[part 4 of 10: package /E40_Platform_System_SystemPackage/Components]
AUTOSAR XML (schema 4-2-1)
package /E40_Platform_System_SystemPackage/Components  (continued)
  21 x constant specification:
    CWarnMsg_Core_ObserverHudWarningDisplayDataValue0: value-spec={short-label=CWarnMsg_Core_ObserverHudWarningDisplayDataValue0, fields=[CWarnMsg_Core_ObserverHudWarningDisplayDataValue_0:0, CWarnMsg_Core_ObserverHudWarningDisplayDataValue_1:0, CWarnMsg_Core_ObserverHudWarningDisplayDataValue_2:[CWarnMsg_Core_ObserverdynData0Value:0, CWarnMsg_Core_ObserverdynData1Value:0, CWarnMsg_Core_ObserverdynData2Value:0, CWarnMsg_Core_ObserverdynData3Value:0, CWarnMsg_Core_ObserverdynData4Value:0, CWarnMsg_Core_ObserverdynData5Value:0, CWarnMsg_Core_ObserverdynData6Value:0, CWarnMsg_Core_ObserverdynData7Value:0]]}
    CWarnMsg_Core_ObserverTpmsWarningDataDataValue0: value-spec={short-label=CWarnMsg_Core_ObserverTpmsWarningDataDataValue0, fields=CWarnMsg_Core_ObserverTpmsWarningDataDataValue_0:[CWarnMsg_Core_ObservertpmsWarndata0Value:0, CWarnMsg_Core_ObservertpmsWarndata1Value:0, CWarnMsg_Core_ObservertpmsWarndata2Value:0, CWarnMsg_Core_ObservertpmsWarndata3Value:0, CWarnMsg_Core_ObservertpmsWarndata4Value:0]}
    CWarnMsg_Core_ObserverWarningHighInterrupt_StateValue0: value-spec=CWarnMsg_Core_ObserverWarningHighInterrupt_StateValue0:0
    CWarnMsg_Core_ObserverWarningInterrupt_StateValue0: value-spec=CWarnMsg_Core_ObserverWarningInterrupt_StateValue0:0
    CWarnMsg_Core_ObserverWarningDisplayDataValue0: value-spec={short-label=CWarnMsg_Core_ObserverWarningDisplayDataValue0, fields=[CWarnMsg_Core_ObserverWarningDisplayDataValue_0:0, CWarnMsg_Core_ObserverWarningDisplayDataValue_1:0, CWarnMsg_Core_ObserverWarningDisplayDataValue_2:[CWarnMsg_Core_ObserverdynData0Value:0, CWarnMsg_Core_ObserverdynData1Value:0, CWarnMsg_Core_ObserverdynData2Value:0, CWarnMsg_Core_ObserverdynData3Value:0, CWarnMsg_Core_ObserverdynData4Value:0, CWarnMsg_Core_ObserverdynData5Value:0, CWarnMsg_Core_ObserverdynData6Value:0, CWarnMsg_Core_ObserverdynData7Value:0]]}
    CWarnMsg_Core_ObserverChime_RequestValue0: value-spec=CWarnMsg_Core_ObserverChime_RequestValue0:0
    CWarnMsg_Core_ObserverChime_StatusValue0: value-spec=CWarnMsg_Core_ObserverChime_StatusValue0:0
    CWarnMsg_Core_ObserverIgnitionSubstateValue0: value-spec=CWarnMsg_Core_ObserverIgnitionSubstateValue0:0
    CWarnMsg_Core_ObserverWSSCurrentClusterModeValue0: value-spec=CWarnMsg_Core_ObserverWSSCurrentClusterModeValue0:0
    CWarnMsg_Core_ObserverFactoryModeValue0: value-spec=CWarnMsg_Core_ObserverFactoryModeValue0:0
    CWarnMsg_Core_ObserverFactoryModeStatusValue0: value-spec=CWarnMsg_Core_ObserverFactoryModeStatusValue0:0
    CWarnMsg_Core_ObserverHMI_ReadyStatusValue0: value-spec=CWarnMsg_Core_ObserverHMI_ReadyStatusValue0:0
    CWarnMsg_Core_ObserverHMIScreenMode_StatusValue0: value-spec=CWarnMsg_Core_ObserverHMIScreenMode_StatusValue0:0
    CWarnMsg_Core_ObserverWakeType_HwValue0: value-spec=CWarnMsg_Core_ObserverWakeType_HwValue0:0
    CWarnMsg_Core_ObserverWakeType_IntValue0: value-spec=CWarnMsg_Core_ObserverWakeType_IntValue0:0
    CWarnMsg_Core_ObserverHudWarningStatusDataValue0: value-spec={short-label=CWarnMsg_Core_ObserverHudWarningStatusDataValue0, fields=[CWarnMsg_Core_ObserverHudWarningStatusDataValue_0:0, CWarnMsg_Core_ObserverHudWarningStatusDataValue_1:0, CWarnMsg_Core_ObserverHudWarningStatusDataValue_2:[CWarnMsg_Core_ObserverdynData0Value:0, CWarnMsg_Core_ObserverdynData1Value:0, CWarnMsg_Core_ObserverdynData2Value:0, CWarnMsg_Core_ObserverdynData3Value:0, CWarnMsg_Core_ObserverdynData4Value:0, CWarnMsg_Core_ObserverdynData5Value:0, CWarnMsg_Core_ObserverdynData6Value:0, CWarnMsg_Core_ObserverdynData7Value:0, CWarnMsg_Core_ObserverdynData8Value:0, CWarnMsg_Core_ObserverdynData9Value:0]]}
    CWarnMsg_Core_ObserverStarterStatus_OutValue0: value-spec=CWarnMsg_Core_ObserverStarterStatus_OutValue0:0
    CWarnMsg_Core_ObserverNvmDataValue0: value-spec=CWarnMsg_Core_ObserverNvmDataValue0:0
    CWarnMsg_Core_ObserverTpms_PayloadValue0: value-spec=CWarnMsg_Core_ObserverTpms_PayloadValue0:[CWarnMsg_Core_ObserverTpms_Payload0Value:0, CWarnMsg_Core_ObserverTpms_Payload1Value:0, CWarnMsg_Core_ObserverTpms_Payload2Value:0, CWarnMsg_Core_ObserverTpms_Payload3Value:0, CWarnMsg_Core_ObserverTpms_Payload4Value:0]
    CWarnMsg_Core_ObserverTargetSwValue0: value-spec=CWarnMsg_Core_ObserverTargetSwValue0:0
    CWarnMsg_Core_ObserverWarningStatusDataValue0: value-spec={short-label=CWarnMsg_Core_ObserverWarningStatusDataValue0, fields=[CWarnMsg_Core_ObserverWarningStatusDataValue_0:0, CWarnMsg_Core_ObserverWarningStatusDataValue_1:0, CWarnMsg_Core_ObserverWarningStatusDataValue_2:[CWarnMsg_Core_ObserverdynData0Value:0, CWarnMsg_Core_ObserverdynData1Value:0, CWarnMsg_Core_ObserverdynData2Value:0, CWarnMsg_Core_ObserverdynData3Value:0, CWarnMsg_Core_ObserverdynData4Value:0, CWarnMsg_Core_ObserverdynData5Value:0, CWarnMsg_Core_ObserverdynData6Value:0, CWarnMsg_Core_ObserverdynData7Value:0, CWarnMsg_Core_ObserverdynData8Value:0, CWarnMsg_Core_ObserverdynData9Value:0]]}
  swc implementation IMPL_CWarnMsg_Core_Observer: programming-language=C, behavior=IB_CWarnMsg_Core_Observer
    code-descriptors:
      code CodeDescriptor
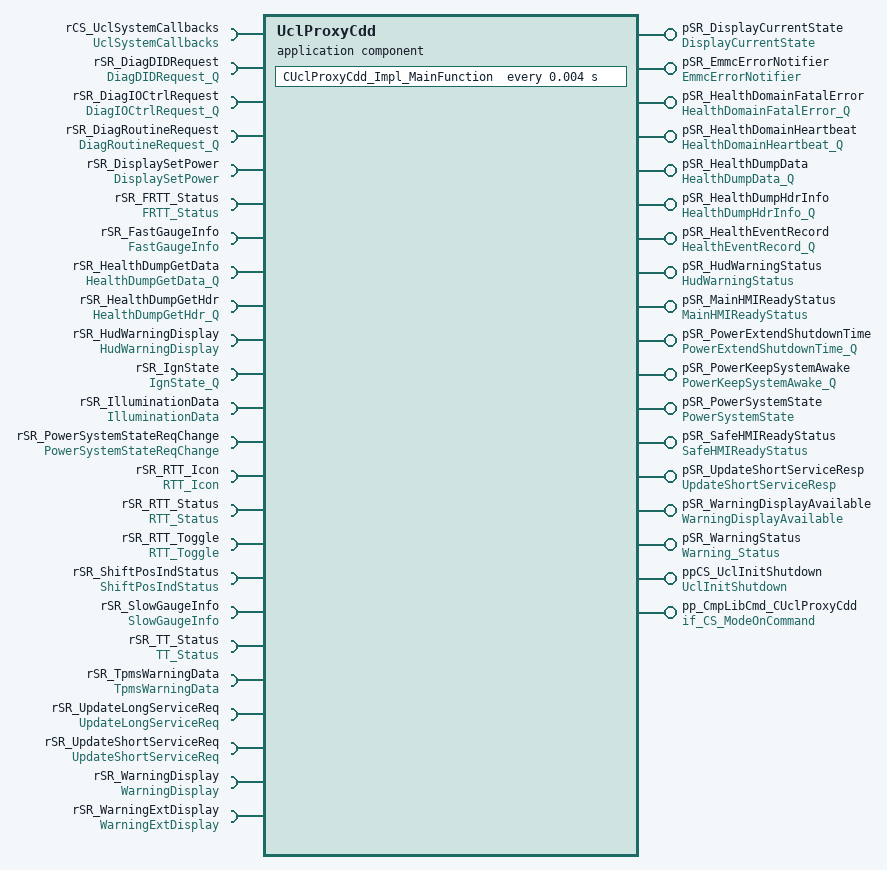
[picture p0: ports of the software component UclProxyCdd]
  application sw component type UclProxyCdd
    18 x provide port:
      pSR_DisplayCurrentState: nonqueued-sender-com-spec{data-element=DisplayCurrentStateData, init-value=constant-reference=UclProxyCddDisplayCurrentStateDataValue0}, provided-interface=DisplayCurrentState
      pSR_EmmcErrorNotifier: nonqueued-sender-com-spec{data-element=EmmcErrorNotifierData, init-value=constant-reference=UclProxyCddEmmcErrorNotifierDataValue0}, provided-interface=EmmcErrorNotifier
      pSR_HealthDomainFatalError: queued-sender-com-spec=HealthDomainFatalErrorData, provided-interface=HealthDomainFatalError_Q
      pSR_HealthDomainHeartbeat: queued-sender-com-spec=HealthDomainHeartbeatData, provided-interface=HealthDomainHeartbeat_Q
      pSR_HealthDumpData: queued-sender-com-spec=HealthDumpDataData, provided-interface=HealthDumpData_Q
      pSR_HealthDumpHdrInfo: queued-sender-com-spec=HealthDumpHdrInfoData, provided-interface=HealthDumpHdrInfo_Q
      pSR_HealthEventRecord: queued-sender-com-spec=HealthEventRecordData, provided-interface=HealthEventRecord_Q
      pSR_HudWarningStatus: nonqueued-sender-com-spec{data-element=HudWarningStatusData, init-value=constant-reference=UclProxyCddHudWarningStatusDataValue0}, provided-interface=HudWarningStatus
      pSR_MainHMIReadyStatus: queued-sender-com-spec=MainHMIReadyStatusData, provided-interface=MainHMIReadyStatus
      pSR_PowerExtendShutdownTime: queued-sender-com-spec=PowerExtendShutdownTimeData, provided-interface=PowerExtendShutdownTime_Q
      pSR_PowerKeepSystemAwake: queued-sender-com-spec=PowerKeepSystemAwakeData, provided-interface=PowerKeepSystemAwake_Q
      pSR_PowerSystemState: nonqueued-sender-com-spec{data-element=PowerSystemStateData, init-value=constant-reference=UclProxyCddPowerSystemStateDataValue0}, provided-interface=PowerSystemState
      pSR_SafeHMIReadyStatus: queued-sender-com-spec=SafeHMIReadyStatusData, provided-interface=SafeHMIReadyStatus
      pSR_UpdateShortServiceResp: nonqueued-sender-com-spec{data-element=UpdateShortServiceRespData, init-value=constant-reference=UclProxyCddUpdateShortServiceRespDataValue0}, provided-interface=UpdateShortServiceResp
      pSR_WarningDisplayAvailable: nonqueued-sender-com-spec{data-element=WarningDisplayAvailableData, init-value=constant-reference=UclProxyCddWarningDisplayAvailableDataValue0}, provided-interface=WarningDisplayAvailable
      pSR_WarningStatus: nonqueued-sender-com-spec{data-element=WarningStatusData, init-value=constant-reference=UclProxyCddWarningStatusDataValue0}, provided-interface=Warning_Status
      ppCS_UclInitShutdown: provided-com-specs=[{operation=Impl_Initialize, queue-length=1}, {operation=Impl_Shutdown, queue-length=1}], provided-interface=UclInitShutdown
      pp_CmpLibCmd_CUclProxyCdd: server-com-spec{operation=Impl_OnCommand, queue-length=1}, provided-interface=if_CS_ModeOnCommand
    24 x require port:
      rCS_UclSystemCallbacks: required-interface=UclSystemCallbacks
      rSR_DiagDIDRequest: queued-receiver-com-spec{data-element=DiagDIDRequestData, queue-length=2}, required-interface=DiagDIDRequest_Q
      rSR_DiagIOCtrlRequest: queued-receiver-com-spec{data-element=DiagIOCtrlRequestData, queue-length=2}, required-interface=DiagIOCtrlRequest_Q
      rSR_DiagRoutineRequest: queued-receiver-com-spec{data-element=DiagRoutineRequestData, queue-length=2}, required-interface=DiagRoutineRequest_Q
      rSR_DisplaySetPower: nonqueued-receiver-com-spec{data-element=DisplaySetPower/DisplaySetPowerData, init-value=constant-reference=UclProxyCddDisplaySetPowerDataValue0}, required-interface=DisplaySetPower
      rSR_FRTT_Status: nonqueued-receiver-com-spec{data-element=FRTT_StatusData, init-value=constant-reference=UclProxyCddFRTT_StatusDataValue0}, required-interface=FRTT_Status
      rSR_FastGaugeInfo: nonqueued-receiver-com-spec{data-element=FastGaugeInfoData, init-value=constant-reference=UclProxyCddFastGaugeInfoDataValue0}, required-interface=FastGaugeInfo
      rSR_HealthDumpGetData: queued-receiver-com-spec{data-element=HealthDumpGetDataData, queue-length=1}, required-interface=HealthDumpGetData_Q
      rSR_HealthDumpGetHdr: queued-receiver-com-spec{data-element=HealthDumpGetHdrData, queue-length=1}, required-interface=HealthDumpGetHdr_Q
      rSR_HudWarningDisplay: nonqueued-receiver-com-spec{data-element=HudWarningDisplayData, init-value=constant-reference=UclProxyCddHudWarningDisplayDataValue0}, required-interface=HudWarningDisplay
      rSR_IgnState: queued-receiver-com-spec{data-element=IgnStateData, queue-length=5}, required-interface=IgnState_Q
      rSR_IlluminationData: nonqueued-receiver-com-spec{data-element=IlluminationDataData, init-value=constant-reference=UclProxyCddIlluminationDataDataValue0}, required-interface=IlluminationData
      rSR_PowerSystemStateReqChange: nonqueued-receiver-com-spec{data-element=PowerSystemStateReqChangeData, init-value=constant-reference=UclProxyCddPowerSystemStateReqChangeDataValue0}, required-interface=PowerSystemStateReqChange
      rSR_RTT_Icon: nonqueued-receiver-com-spec{data-element=RTT_IconData, init-value=constant-reference=UclProxyCddRTT_IconDataValue0}, required-interface=RTT_Icon
      rSR_RTT_Status: nonqueued-receiver-com-spec{data-element=RTT_StatusData, init-value=constant-reference=UclProxyCddRTT_StatusDataValue0}, required-interface=RTT_Status
      rSR_RTT_Toggle: nonqueued-receiver-com-spec{data-element=RTT_ToggleData, init-value=constant-reference=UclProxyCddRTT_ToggleDataValue0}, required-interface=RTT_Toggle
      rSR_ShiftPosIndStatus: nonqueued-receiver-com-spec{data-element=ShiftPosIndStatusData, init-value=constant-reference=UclProxyCddShiftPosIndStatusDataValue0}, required-interface=ShiftPosIndStatus
      rSR_SlowGaugeInfo: nonqueued-receiver-com-spec{data-element=SlowGaugeInfoData, init-value=constant-reference=UclProxyCddSlowGaugeInfoDataValue0}, required-interface=SlowGaugeInfo
      rSR_TT_Status: nonqueued-receiver-com-spec{data-element=TT_StatusData, init-value=constant-reference=UclProxyCddTT_StatusDataValue0}, required-interface=TT_Status
      rSR_TpmsWarningData: nonqueued-receiver-com-spec{data-element=TpmsWarningDataData, init-value=constant-reference=UclProxyCddTpmsWarningDataDataValue0}, required-interface=TpmsWarningData
      rSR_UpdateLongServiceReq: nonqueued-receiver-com-spec{data-element=UpdateLongServiceReqData, init-value=constant-reference=UclProxyCddUpdateLongServiceReqDataValue0}, required-interface=UpdateLongServiceReq
      rSR_UpdateShortServiceReq: nonqueued-receiver-com-spec{data-element=UpdateShortServiceReqData, init-value=constant-reference=UclProxyCddUpdateShortServiceReqDataValue0}, required-interface=UpdateShortServiceReq
      rSR_WarningDisplay: nonqueued-receiver-com-spec{data-element=WarningDisplayData, init-value=constant-reference=UclProxyCddWarningDisplayDataValue0}, required-interface=WarningDisplay
      rSR_WarningExtDisplay: nonqueued-receiver-com-spec{data-element=WarningExtDisplayData, init-value=constant-reference=UclProxyCddWarningExtDisplayDataValue0}, required-interface=WarningExtDisplay
    behavior IB_UclProxyCdd
      operation invoked event OIE_ppCS_UclInitShutdown_CUclProxyCdd_Impl_InitializeTrigByImpl_Initialize: start-on-event=CUclProxyCdd_Impl_Initialize, operation=ppCS_UclInitShutdown.Impl_Initialize
      timing event TECUclProxyCdd_Impl_MainFunction: start-on-event=CUclProxyCdd_Impl_MainFunction, period=0.004
      operation invoked event OIE_pp_CmpLibCmd_CUclProxyCdd_CUclProxyCdd_Impl_OnCommandTrigByImpl_OnCommand: start-on-event=CUclProxyCdd_Impl_OnCommand, operation=pp_CmpLibCmd_CUclProxyCdd.Impl_OnCommand
      operation invoked event OIE_ppCS_UclInitShutdown_CUclProxyCdd_Impl_ShutdownTrigByImpl_Shutdown: start-on-event=CUclProxyCdd_Impl_Shutdown, operation=ppCS_UclInitShutdown.Impl_Shutdown
      17 x data received event:
        DREOnDre_DisplaySetPowerTrigByDisplaySetPowerData: start-on-event=OnDre_DisplaySetPower, data=rSR_DisplaySetPower.DisplaySetPowerData
        DREOnDre_FRTT_StatusTrigByFRTT_StatusData: start-on-event=OnDre_FRTT_Status, data=rSR_FRTT_Status.FRTT_StatusData
        DREOnDre_FastGaugeInfoTrigByFastGaugeInfoData: start-on-event=OnDre_FastGaugeInfo, data=rSR_FastGaugeInfo.FastGaugeInfoData
        DREOnDre_HealthDumpGetDataTrigByHealthDumpGetDataData: start-on-event=OnDre_HealthDumpGetData, data=rSR_HealthDumpGetData.HealthDumpGetDataData
        DREOnDre_HealthDumpGetHdrTrigByHealthDumpGetHdrData: start-on-event=OnDre_HealthDumpGetHdr, data=rSR_HealthDumpGetHdr.HealthDumpGetHdrData
        DREOnDre_IlluminationDataTrigByWarningExtDisplayData: start-on-event=OnDre_IlluminationData, data=rSR_WarningExtDisplay.WarningExtDisplayData
        DREOnDre_PowerSystemStateReqChangeTrigByPowerSystemStateReqChangeData: start-on-event=OnDre_PowerSystemStateReqChange, data=rSR_PowerSystemStateReqChange.PowerSystemStateReqChangeData
        DREOnDre_RTT_IconTrigByRTT_IconData: start-on-event=OnDre_RTT_Icon, data=rSR_RTT_Icon.RTT_IconData
        DREOnDre_RTT_StatusTrigByRTT_StatusData: start-on-event=OnDre_RTT_Status, data=rSR_RTT_Status.RTT_StatusData
        DREOnDre_RTT_ToggleTrigByRTT_ToggleData: start-on-event=OnDre_RTT_Toggle, data=rSR_RTT_Toggle.RTT_ToggleData
        DREOnDre_ShiftPosIndStatusTrigByShiftPosIndStatusData: start-on-event=OnDre_ShiftPosIndStatus, data=rSR_ShiftPosIndStatus.ShiftPosIndStatusData
        DREOnDre_SlowGaugeInfoTrigBySlowGaugeInfoData: start-on-event=OnDre_SlowGaugeInfo, data=rSR_SlowGaugeInfo.SlowGaugeInfoData
        DREOnDre_TT_StatusTrigByTT_StatusData: start-on-event=OnDre_TT_Status, data=rSR_TT_Status.TT_StatusData
        DREOnDre_UpdateLongServiceReqTrigByRTT_ToggleData: start-on-event=OnDre_UpdateLongServiceReq, data=rSR_RTT_Toggle.RTT_ToggleData
        DREOnDre_UpdateShortServiceReqTrigByRTT_ToggleData: start-on-event=OnDre_UpdateShortServiceReq, data=rSR_RTT_Toggle.RTT_ToggleData
        DREOnDre_WarningDisplayTrigByWarningDisplayData: start-on-event=OnDre_WarningDisplay, data=rSR_WarningDisplay.WarningDisplayData
        DREOnDre_WarningExtDisplayTrigByIlluminationDataData: start-on-event=OnDre_WarningExtDisplay, data=rSR_IlluminationData.IlluminationDataData
      port-api-options:
        enable-take-address=false, indirect-api=false, port=pSR_DisplayCurrentState
        enable-take-address=false, indirect-api=false, port=pSR_EmmcErrorNotifier
        enable-take-address=false, indirect-api=false, port=pSR_HealthDomainFatalError
        enable-take-address=false, indirect-api=false, port=pSR_HealthDomainHeartbeat
        enable-take-address=false, indirect-api=false, port=pSR_HealthDumpData
        enable-take-address=false, indirect-api=false, port=pSR_HealthDumpHdrInfo
        enable-take-address=false, indirect-api=false, port=pSR_HealthEventRecord
        enable-take-address=false, indirect-api=false, port=pSR_HudWarningStatus
        enable-take-address=false, indirect-api=false, port=pSR_MainHMIReadyStatus
        enable-take-address=false, indirect-api=false, port=pSR_PowerExtendShutdownTime
        enable-take-address=false, indirect-api=false, port=pSR_PowerKeepSystemAwake
        enable-take-address=false, indirect-api=false, port=pSR_PowerSystemState
        enable-take-address=false, indirect-api=false, port=pSR_SafeHMIReadyStatus
        enable-take-address=false, indirect-api=false, port=pSR_UpdateShortServiceResp
        enable-take-address=false, indirect-api=false, port=pSR_WarningDisplayAvailable
        enable-take-address=false, indirect-api=false, port=pSR_WarningStatus
        enable-take-address=false, indirect-api=false, port=ppCS_UclInitShutdown
        enable-take-address=false, indirect-api=false, port=pp_CmpLibCmd_CUclProxyCdd
        enable-take-address=false, indirect-api=false, port=rCS_UclSystemCallbacks
        enable-take-address=false, indirect-api=false, port=rSR_DiagDIDRequest
        enable-take-address=false, indirect-api=false, port=rSR_DiagIOCtrlRequest
        enable-take-address=false, indirect-api=false, port=rSR_DiagRoutineRequest
        enable-take-address=false, indirect-api=false, port=rSR_DisplaySetPower
        enable-take-address=false, indirect-api=false, port=rSR_FRTT_Status
        enable-take-address=false, indirect-api=false, port=rSR_FastGaugeInfo
        enable-take-address=false, indirect-api=false, port=rSR_HealthDumpGetData
        enable-take-address=false, indirect-api=false, port=rSR_HealthDumpGetHdr
        enable-take-address=false, indirect-api=false, port=rSR_HudWarningDisplay
        enable-take-address=false, indirect-api=false, port=rSR_IgnState
        enable-take-address=false, indirect-api=false, port=rSR_IlluminationData
        enable-take-address=false, indirect-api=false, port=rSR_PowerSystemStateReqChange
        enable-take-address=false, indirect-api=false, port=rSR_RTT_Icon
        enable-take-address=false, indirect-api=false, port=rSR_RTT_Status
        enable-take-address=false, indirect-api=false, port=rSR_RTT_Toggle
        enable-take-address=false, indirect-api=false, port=rSR_ShiftPosIndStatus
        enable-take-address=false, indirect-api=false, port=rSR_SlowGaugeInfo
        enable-take-address=false, indirect-api=false, port=rSR_TT_Status
        enable-take-address=false, indirect-api=false, port=rSR_TpmsWarningData
        enable-take-address=false, indirect-api=false, port=rSR_UpdateLongServiceReq
        enable-take-address=false, indirect-api=false, port=rSR_UpdateShortServiceReq
        enable-take-address=false, indirect-api=false, port=rSR_WarningDisplay
        enable-take-address=false, indirect-api=false, port=rSR_WarningExtDisplay
      21 x runnable, all with can-be-invoked-concurrently=true:
        CUclProxyCdd_Impl_Initialize
        CUclProxyCdd_Impl_MainFunction
          data-receive-point-by-arguments:
            23 x access:
              DRP_rSR_DiagDIDRequest_DiagDIDRequestData: accessed-variable=rSR_DiagDIDRequest.DiagDIDRequestData
              DRP_rSR_DiagIOCtrlRequest_DiagIOCtrlRequestData: accessed-variable=rSR_DiagIOCtrlRequest.DiagIOCtrlRequestData
              DRP_rSR_DiagRoutineRequest_DiagRoutineRequestData: accessed-variable=rSR_DiagRoutineRequest.DiagRoutineRequestData
              DRA_rSR_DisplaySetPower_DisplaySetPowerData: accessed-variable=rSR_DisplaySetPower.DisplaySetPowerData
              DRA_rSR_FRTT_Status_FRTT_StatusData: accessed-variable=rSR_FRTT_Status.FRTT_StatusData
              DRA_rSR_FastGaugeInfo_FastGaugeInfoData: accessed-variable=rSR_FastGaugeInfo.FastGaugeInfoData
              DRP_rSR_HealthDumpGetData_HealthDumpGetDataData: accessed-variable=rSR_HealthDumpGetData.HealthDumpGetDataData
              DRP_rSR_HealthDumpGetHdr_HealthDumpGetHdrData: accessed-variable=rSR_HealthDumpGetHdr.HealthDumpGetHdrData
              DRA_rSR_HudWarningDisplay_HudWarningDisplayData: accessed-variable=rSR_HudWarningDisplay.HudWarningDisplayData
              DRP_rSR_IgnState_IgnStateData: accessed-variable=rSR_IgnState.IgnStateData
              DRA_rSR_IlluminationData_IlluminationDataData: accessed-variable=rSR_IlluminationData.IlluminationDataData
              DRA_rSR_PowerSystemStateReqChange_PowerSystemStateReqChangeData: accessed-variable=rSR_PowerSystemStateReqChange.PowerSystemStateReqChangeData
              DRA_rSR_RTT_Icon_RTT_IconData: accessed-variable=rSR_RTT_Icon.RTT_IconData
              DRA_rSR_RTT_Status_RTT_StatusData: accessed-variable=rSR_RTT_Status.RTT_StatusData
              DRA_rSR_RTT_Toggle_RTT_ToggleData: accessed-variable=rSR_RTT_Toggle.RTT_ToggleData
              DRA_rSR_ShiftPosIndStatus_ShiftPosIndStatusData: accessed-variable=rSR_ShiftPosIndStatus.ShiftPosIndStatusData
              DRA_rSR_SlowGaugeInfo_SlowGaugeInfoData: accessed-variable=rSR_SlowGaugeInfo.SlowGaugeInfoData
              DRA_rSR_TT_Status_TT_StatusData: accessed-variable=rSR_TT_Status.TT_StatusData
              DRA_rSR_TpmsWarningData_TpmsWarningDataData: accessed-variable=rSR_TpmsWarningData.TpmsWarningDataData
              DRA_rSR_UpdateLongServiceReq_UpdateLongServiceReqData: accessed-variable=rSR_UpdateLongServiceReq.UpdateLongServiceReqData
              DRA_rSR_UpdateShortServiceReq_UpdateShortServiceReqData: accessed-variable=rSR_UpdateShortServiceReq.UpdateShortServiceReqData
              DRA_rSR_WarningDisplay_WarningDisplayData: accessed-variable=rSR_WarningDisplay.WarningDisplayData
              DRA_rSR_WarningExtDisplay_WarningExtDisplayData: accessed-variable=rSR_WarningExtDisplay.WarningExtDisplayData
          data-send-points:
            16 x access:
              DWA_pSR_DisplayCurrentState_DisplayCurrentStateData: accessed-variable=pSR_DisplayCurrentState.DisplayCurrentStateData
              DWA_pSR_EmmcErrorNotifier_EmmcErrorNotifierData: accessed-variable=pSR_EmmcErrorNotifier.EmmcErrorNotifierData
              DSP_pSR_HealthDomainFatalError_HealthDomainFatalErrorData: accessed-variable=pSR_HealthDomainFatalError.HealthDomainFatalErrorData
              DSP_pSR_HealthDomainHeartbeat_HealthDomainHeartbeatData: accessed-variable=pSR_HealthDomainHeartbeat.HealthDomainHeartbeatData
              DSP_pSR_HealthDumpData_HealthDumpDataData: accessed-variable=pSR_HealthDumpData.HealthDumpDataData
              DSP_pSR_HealthDumpHdrInfo_HealthDumpHdrInfoData: accessed-variable=pSR_HealthDumpHdrInfo.HealthDumpHdrInfoData
              DSP_pSR_HealthEventRecord_HealthEventRecordData: accessed-variable=pSR_HealthEventRecord.HealthEventRecordData
              DWA_pSR_HudWarningStatus_HudWarningStatusData: accessed-variable=pSR_HudWarningStatus.HudWarningStatusData
              DSP_pSR_MainHMIReadyStatus_MainHMIReadyStatusData: accessed-variable=pSR_MainHMIReadyStatus.MainHMIReadyStatusData
              DSP_pSR_PowerExtendShutdownTime_PowerExtendShutdownTimeData: accessed-variable=pSR_PowerExtendShutdownTime.PowerExtendShutdownTimeData
              DSP_pSR_PowerKeepSystemAwake_PowerKeepSystemAwakeData: accessed-variable=pSR_PowerKeepSystemAwake.PowerKeepSystemAwakeData
              DWA_pSR_PowerSystemState_PowerSystemStateData: accessed-variable=pSR_PowerSystemState.PowerSystemStateData
              DSP_pSR_SafeHMIReadyStatus_SafeHMIReadyStatusData: accessed-variable=pSR_SafeHMIReadyStatus.SafeHMIReadyStatusData
              DWA_pSR_UpdateShortServiceResp_UpdateShortServiceRespData: accessed-variable=pSR_UpdateShortServiceResp.UpdateShortServiceRespData
              DWA_pSR_WarningDisplayAvailable_WarningDisplayAvailableData: accessed-variable=pSR_WarningDisplayAvailable.WarningDisplayAvailableData
              DWA_pSR_WarningStatus_WarningStatusData: accessed-variable=pSR_WarningStatus.WarningStatusData
          sync call OA_rCS_UclSystemCallbacks_ErrorNotification: operation=rCS_UclSystemCallbacks.ErrorNotification, timeout=0.0
          sync call OA_rCS_UclSystemCallbacks_LinkStatusChanged: operation=rCS_UclSystemCallbacks.LinkStatusChanged, timeout=0.0
        CUclProxyCdd_Impl_OnCommand
        CUclProxyCdd_Impl_Shutdown
        OnDre_DisplaySetPower
          data-receive-point-by-arguments:
            23 x access:
              DRP_rSR_DiagDIDRequest_DiagDIDRequestData: accessed-variable=rSR_DiagDIDRequest.DiagDIDRequestData
              DRP_rSR_DiagIOCtrlRequest_DiagIOCtrlRequestData: accessed-variable=rSR_DiagIOCtrlRequest.DiagIOCtrlRequestData
              DRP_rSR_DiagRoutineRequest_DiagRoutineRequestData: accessed-variable=rSR_DiagRoutineRequest.DiagRoutineRequestData
              DRA_rSR_DisplaySetPower_DisplaySetPowerData: accessed-variable=rSR_DisplaySetPower.DisplaySetPowerData
              DRA_rSR_FRTT_Status_FRTT_StatusData: accessed-variable=rSR_FRTT_Status.FRTT_StatusData
              DRA_rSR_FastGaugeInfo_FastGaugeInfoData: accessed-variable=rSR_FastGaugeInfo.FastGaugeInfoData
              DRP_rSR_HealthDumpGetData_HealthDumpGetDataData: accessed-variable=rSR_HealthDumpGetData.HealthDumpGetDataData
              DRP_rSR_HealthDumpGetHdr_HealthDumpGetHdrData: accessed-variable=rSR_HealthDumpGetHdr.HealthDumpGetHdrData
              DRA_rSR_HudWarningDisplay_HudWarningDisplayData: accessed-variable=rSR_HudWarningDisplay.HudWarningDisplayData
              DRP_rSR_IgnState_IgnStateData: accessed-variable=rSR_IgnState.IgnStateData
              DRA_rSR_IlluminationData_IlluminationDataData: accessed-variable=rSR_IlluminationData.IlluminationDataData
              DRA_rSR_PowerSystemStateReqChange_PowerSystemStateReqChangeData: accessed-variable=rSR_PowerSystemStateReqChange.PowerSystemStateReqChangeData
              DRA_rSR_RTT_Icon_RTT_IconData: accessed-variable=rSR_RTT_Icon.RTT_IconData
              DRA_rSR_RTT_Status_RTT_StatusData: accessed-variable=rSR_RTT_Status.RTT_StatusData
              DRA_rSR_RTT_Toggle_RTT_ToggleData: accessed-variable=rSR_RTT_Toggle.RTT_ToggleData
              DRA_rSR_ShiftPosIndStatus_ShiftPosIndStatusData: accessed-variable=rSR_ShiftPosIndStatus.ShiftPosIndStatusData
              DRA_rSR_SlowGaugeInfo_SlowGaugeInfoData: accessed-variable=rSR_SlowGaugeInfo.SlowGaugeInfoData
              DRA_rSR_TT_Status_TT_StatusData: accessed-variable=rSR_TT_Status.TT_StatusData
              DRA_rSR_TpmsWarningData_TpmsWarningDataData: accessed-variable=rSR_TpmsWarningData.TpmsWarningDataData
              DRA_rSR_UpdateLongServiceReq_UpdateLongServiceReqData: accessed-variable=rSR_UpdateLongServiceReq.UpdateLongServiceReqData
              DRA_rSR_UpdateShortServiceReq_UpdateShortServiceReqData: accessed-variable=rSR_UpdateShortServiceReq.UpdateShortServiceReqData
              DRA_rSR_WarningDisplay_WarningDisplayData: accessed-variable=rSR_WarningDisplay.WarningDisplayData
              DRA_rSR_WarningExtDisplay_WarningExtDisplayData: accessed-variable=rSR_WarningExtDisplay.WarningExtDisplayData
          data-send-points:
            16 x access:
              DWA_pSR_DisplayCurrentState_DisplayCurrentStateData: accessed-variable=pSR_DisplayCurrentState.DisplayCurrentStateData
              DWA_pSR_EmmcErrorNotifier_EmmcErrorNotifierData: accessed-variable=pSR_EmmcErrorNotifier.EmmcErrorNotifierData
              DSP_pSR_HealthDomainFatalError_HealthDomainFatalErrorData: accessed-variable=pSR_HealthDomainFatalError.HealthDomainFatalErrorData
              DSP_pSR_HealthDomainHeartbeat_HealthDomainHeartbeatData: accessed-variable=pSR_HealthDomainHeartbeat.HealthDomainHeartbeatData
              DSP_pSR_HealthDumpData_HealthDumpDataData: accessed-variable=pSR_HealthDumpData.HealthDumpDataData
              DSP_pSR_HealthDumpHdrInfo_HealthDumpHdrInfoData: accessed-variable=pSR_HealthDumpHdrInfo.HealthDumpHdrInfoData
              DSP_pSR_HealthEventRecord_HealthEventRecordData: accessed-variable=pSR_HealthEventRecord.HealthEventRecordData
              DWA_pSR_HudWarningStatus_HudWarningStatusData: accessed-variable=pSR_HudWarningStatus.HudWarningStatusData
              DSP_pSR_MainHMIReadyStatus_MainHMIReadyStatusData: accessed-variable=pSR_MainHMIReadyStatus.MainHMIReadyStatusData
              DSP_pSR_PowerExtendShutdownTime_PowerExtendShutdownTimeData: accessed-variable=pSR_PowerExtendShutdownTime.PowerExtendShutdownTimeData
              DSP_pSR_PowerKeepSystemAwake_PowerKeepSystemAwakeData: accessed-variable=pSR_PowerKeepSystemAwake.PowerKeepSystemAwakeData
              DWA_pSR_PowerSystemState_PowerSystemStateData: accessed-variable=pSR_PowerSystemState.PowerSystemStateData
              DSP_pSR_SafeHMIReadyStatus_SafeHMIReadyStatusData: accessed-variable=pSR_SafeHMIReadyStatus.SafeHMIReadyStatusData
              DWA_pSR_UpdateShortServiceResp_UpdateShortServiceRespData: accessed-variable=pSR_UpdateShortServiceResp.UpdateShortServiceRespData
              DWA_pSR_WarningDisplayAvailable_WarningDisplayAvailableData: accessed-variable=pSR_WarningDisplayAvailable.WarningDisplayAvailableData
              DWA_pSR_WarningStatus_WarningStatusData: accessed-variable=pSR_WarningStatus.WarningStatusData
          sync call OA_rCS_UclSystemCallbacks_ErrorNotification: operation=rCS_UclSystemCallbacks.ErrorNotification, timeout=0.0
          sync call OA_rCS_UclSystemCallbacks_LinkStatusChanged: operation=rCS_UclSystemCallbacks.LinkStatusChanged, timeout=0.0
        OnDre_FRTT_Status
          data-receive-point-by-arguments:
            23 x access:
              DRP_rSR_DiagDIDRequest_DiagDIDRequestData: accessed-variable=rSR_DiagDIDRequest.DiagDIDRequestData
              DRP_rSR_DiagIOCtrlRequest_DiagIOCtrlRequestData: accessed-variable=rSR_DiagIOCtrlRequest.DiagIOCtrlRequestData
              DRP_rSR_DiagRoutineRequest_DiagRoutineRequestData: accessed-variable=rSR_DiagRoutineRequest.DiagRoutineRequestData
              DRA_rSR_DisplaySetPower_DisplaySetPowerData: accessed-variable=rSR_DisplaySetPower.DisplaySetPowerData
              DRA_rSR_FRTT_Status_FRTT_StatusData: accessed-variable=rSR_FRTT_Status.FRTT_StatusData
              DRA_rSR_FastGaugeInfo_FastGaugeInfoData: accessed-variable=rSR_FastGaugeInfo.FastGaugeInfoData
              DRP_rSR_HealthDumpGetData_HealthDumpGetDataData: accessed-variable=rSR_HealthDumpGetData.HealthDumpGetDataData
              DRP_rSR_HealthDumpGetHdr_HealthDumpGetHdrData: accessed-variable=rSR_HealthDumpGetHdr.HealthDumpGetHdrData
              DRA_rSR_HudWarningDisplay_HudWarningDisplayData: accessed-variable=rSR_HudWarningDisplay.HudWarningDisplayData
              DRP_rSR_IgnState_IgnStateData: accessed-variable=rSR_IgnState.IgnStateData
              DRA_rSR_IlluminationData_IlluminationDataData: accessed-variable=rSR_IlluminationData.IlluminationDataData
              DRA_rSR_PowerSystemStateReqChange_PowerSystemStateReqChangeData: accessed-variable=rSR_PowerSystemStateReqChange.PowerSystemStateReqChangeData
              DRA_rSR_RTT_Icon_RTT_IconData: accessed-variable=rSR_RTT_Icon.RTT_IconData
              DRA_rSR_RTT_Status_RTT_StatusData: accessed-variable=rSR_RTT_Status.RTT_StatusData
              DRA_rSR_RTT_Toggle_RTT_ToggleData: accessed-variable=rSR_RTT_Toggle.RTT_ToggleData
              DRA_rSR_ShiftPosIndStatus_ShiftPosIndStatusData: accessed-variable=rSR_ShiftPosIndStatus.ShiftPosIndStatusData
              DRA_rSR_SlowGaugeInfo_SlowGaugeInfoData: accessed-variable=rSR_SlowGaugeInfo.SlowGaugeInfoData
              DRA_rSR_TT_Status_TT_StatusData: accessed-variable=rSR_TT_Status.TT_StatusData
              DRA_rSR_TpmsWarningData_TpmsWarningDataData: accessed-variable=rSR_TpmsWarningData.TpmsWarningDataData
              DRA_rSR_UpdateLongServiceReq_UpdateLongServiceReqData: accessed-variable=rSR_UpdateLongServiceReq.UpdateLongServiceReqData
              DRA_rSR_UpdateShortServiceReq_UpdateShortServiceReqData: accessed-variable=rSR_UpdateShortServiceReq.UpdateShortServiceReqData
              DRA_rSR_WarningDisplay_WarningDisplayData: accessed-variable=rSR_WarningDisplay.WarningDisplayData
              DRA_rSR_WarningExtDisplay_WarningExtDisplayData: accessed-variable=rSR_WarningExtDisplay.WarningExtDisplayData
          data-send-points:
            16 x access:
              DWA_pSR_DisplayCurrentState_DisplayCurrentStateData: accessed-variable=pSR_DisplayCurrentState.DisplayCurrentStateData
              DWA_pSR_EmmcErrorNotifier_EmmcErrorNotifierData: accessed-variable=pSR_EmmcErrorNotifier.EmmcErrorNotifierData
              DSP_pSR_HealthDomainFatalError_HealthDomainFatalErrorData: accessed-variable=pSR_HealthDomainFatalError.HealthDomainFatalErrorData
              DSP_pSR_HealthDomainHeartbeat_HealthDomainHeartbeatData: accessed-variable=pSR_HealthDomainHeartbeat.HealthDomainHeartbeatData
              DSP_pSR_HealthDumpData_HealthDumpDataData: accessed-variable=pSR_HealthDumpData.HealthDumpDataData
              DSP_pSR_HealthDumpHdrInfo_HealthDumpHdrInfoData: accessed-variable=pSR_HealthDumpHdrInfo.HealthDumpHdrInfoData
              DSP_pSR_HealthEventRecord_HealthEventRecordData: accessed-variable=pSR_HealthEventRecord.HealthEventRecordData
              DWA_pSR_HudWarningStatus_HudWarningStatusData: accessed-variable=pSR_HudWarningStatus.HudWarningStatusData
              DSP_pSR_MainHMIReadyStatus_MainHMIReadyStatusData: accessed-variable=pSR_MainHMIReadyStatus.MainHMIReadyStatusData
              DSP_pSR_PowerExtendShutdownTime_PowerExtendShutdownTimeData: accessed-variable=pSR_PowerExtendShutdownTime.PowerExtendShutdownTimeData
              DSP_pSR_PowerKeepSystemAwake_PowerKeepSystemAwakeData: accessed-variable=pSR_PowerKeepSystemAwake.PowerKeepSystemAwakeData
              DWA_pSR_PowerSystemState_PowerSystemStateData: accessed-variable=pSR_PowerSystemState.PowerSystemStateData
              DSP_pSR_SafeHMIReadyStatus_SafeHMIReadyStatusData: accessed-variable=pSR_SafeHMIReadyStatus.SafeHMIReadyStatusData
              DWA_pSR_UpdateShortServiceResp_UpdateShortServiceRespData: accessed-variable=pSR_UpdateShortServiceResp.UpdateShortServiceRespData
              DWA_pSR_WarningDisplayAvailable_WarningDisplayAvailableData: accessed-variable=pSR_WarningDisplayAvailable.WarningDisplayAvailableData
              DWA_pSR_WarningStatus_WarningStatusData: accessed-variable=pSR_WarningStatus.WarningStatusData
          sync call OA_rCS_UclSystemCallbacks_ErrorNotification: operation=rCS_UclSystemCallbacks.ErrorNotification, timeout=0.0
          sync call OA_rCS_UclSystemCallbacks_LinkStatusChanged: operation=rCS_UclSystemCallbacks.LinkStatusChanged, timeout=0.0
        OnDre_FastGaugeInfo
          data-receive-point-by-arguments:
            23 x access:
              DRP_rSR_DiagDIDRequest_DiagDIDRequestData: accessed-variable=rSR_DiagDIDRequest.DiagDIDRequestData
              DRP_rSR_DiagIOCtrlRequest_DiagIOCtrlRequestData: accessed-variable=rSR_DiagIOCtrlRequest.DiagIOCtrlRequestData
              DRP_rSR_DiagRoutineRequest_DiagRoutineRequestData: accessed-variable=rSR_DiagRoutineRequest.DiagRoutineRequestData
              DRA_rSR_DisplaySetPower_DisplaySetPowerData: accessed-variable=rSR_DisplaySetPower.DisplaySetPowerData
              DRA_rSR_FRTT_Status_FRTT_StatusData: accessed-variable=rSR_FRTT_Status.FRTT_StatusData
              DRA_rSR_FastGaugeInfo_FastGaugeInfoData: accessed-variable=rSR_FastGaugeInfo.FastGaugeInfoData
              DRP_rSR_HealthDumpGetData_HealthDumpGetDataData: accessed-variable=rSR_HealthDumpGetData.HealthDumpGetDataData
              DRP_rSR_HealthDumpGetHdr_HealthDumpGetHdrData: accessed-variable=rSR_HealthDumpGetHdr.HealthDumpGetHdrData
              DRA_rSR_HudWarningDisplay_HudWarningDisplayData: accessed-variable=rSR_HudWarningDisplay.HudWarningDisplayData
              DRP_rSR_IgnState_IgnStateData: accessed-variable=rSR_IgnState.IgnStateData
              DRA_rSR_IlluminationData_IlluminationDataData: accessed-variable=rSR_IlluminationData.IlluminationDataData
              DRA_rSR_PowerSystemStateReqChange_PowerSystemStateReqChangeData: accessed-variable=rSR_PowerSystemStateReqChange.PowerSystemStateReqChangeData
              DRA_rSR_RTT_Icon_RTT_IconData: accessed-variable=rSR_RTT_Icon.RTT_IconData
              DRA_rSR_RTT_Status_RTT_StatusData: accessed-variable=rSR_RTT_Status.RTT_StatusData
              DRA_rSR_RTT_Toggle_RTT_ToggleData: accessed-variable=rSR_RTT_Toggle.RTT_ToggleData
              DRA_rSR_ShiftPosIndStatus_ShiftPosIndStatusData: accessed-variable=rSR_ShiftPosIndStatus.ShiftPosIndStatusData
              DRA_rSR_SlowGaugeInfo_SlowGaugeInfoData: accessed-variable=rSR_SlowGaugeInfo.SlowGaugeInfoData
              DRA_rSR_TT_Status_TT_StatusData: accessed-variable=rSR_TT_Status.TT_StatusData
              DRA_rSR_TpmsWarningData_TpmsWarningDataData: accessed-variable=rSR_TpmsWarningData.TpmsWarningDataData
              DRA_rSR_UpdateLongServiceReq_UpdateLongServiceReqData: accessed-variable=rSR_UpdateLongServiceReq.UpdateLongServiceReqData
              DRA_rSR_UpdateShortServiceReq_UpdateShortServiceReqData: accessed-variable=rSR_UpdateShortServiceReq.UpdateShortServiceReqData
              DRA_rSR_WarningDisplay_WarningDisplayData: accessed-variable=rSR_WarningDisplay.WarningDisplayData
              DRA_rSR_WarningExtDisplay_WarningExtDisplayData: accessed-variable=rSR_WarningExtDisplay.WarningExtDisplayData
          data-send-points:
            16 x access:
              DWA_pSR_DisplayCurrentState_DisplayCurrentStateData: accessed-variable=pSR_DisplayCurrentState.DisplayCurrentStateData
              DWA_pSR_EmmcErrorNotifier_EmmcErrorNotifierData: accessed-variable=pSR_EmmcErrorNotifier.EmmcErrorNotifierData
              DSP_pSR_HealthDomainFatalError_HealthDomainFatalErrorData: accessed-variable=pSR_HealthDomainFatalError.HealthDomainFatalErrorData
              DSP_pSR_HealthDomainHeartbeat_HealthDomainHeartbeatData: accessed-variable=pSR_HealthDomainHeartbeat.HealthDomainHeartbeatData
              DSP_pSR_HealthDumpData_HealthDumpDataData: accessed-variable=pSR_HealthDumpData.HealthDumpDataData
              DSP_pSR_HealthDumpHdrInfo_HealthDumpHdrInfoData: accessed-variable=pSR_HealthDumpHdrInfo.HealthDumpHdrInfoData
              DSP_pSR_HealthEventRecord_HealthEventRecordData: accessed-variable=pSR_HealthEventRecord.HealthEventRecordData
              DWA_pSR_HudWarningStatus_HudWarningStatusData: accessed-variable=pSR_HudWarningStatus.HudWarningStatusData
              DSP_pSR_MainHMIReadyStatus_MainHMIReadyStatusData: accessed-variable=pSR_MainHMIReadyStatus.MainHMIReadyStatusData
              DSP_pSR_PowerExtendShutdownTime_PowerExtendShutdownTimeData: accessed-variable=pSR_PowerExtendShutdownTime.PowerExtendShutdownTimeData
              DSP_pSR_PowerKeepSystemAwake_PowerKeepSystemAwakeData: accessed-variable=pSR_PowerKeepSystemAwake.PowerKeepSystemAwakeData
              DWA_pSR_PowerSystemState_PowerSystemStateData: accessed-variable=pSR_PowerSystemState.PowerSystemStateData
              DSP_pSR_SafeHMIReadyStatus_SafeHMIReadyStatusData: accessed-variable=pSR_SafeHMIReadyStatus.SafeHMIReadyStatusData
              DWA_pSR_UpdateShortServiceResp_UpdateShortServiceRespData: accessed-variable=pSR_UpdateShortServiceResp.UpdateShortServiceRespData
              DWA_pSR_WarningDisplayAvailable_WarningDisplayAvailableData: accessed-variable=pSR_WarningDisplayAvailable.WarningDisplayAvailableData
              DWA_pSR_WarningStatus_WarningStatusData: accessed-variable=pSR_WarningStatus.WarningStatusData
          sync call OA_rCS_UclSystemCallbacks_ErrorNotification: operation=rCS_UclSystemCallbacks.ErrorNotification, timeout=0.0
          sync call OA_rCS_UclSystemCallbacks_LinkStatusChanged: operation=rCS_UclSystemCallbacks.LinkStatusChanged, timeout=0.0
        OnDre_HealthDumpGetData
          data-receive-point-by-arguments:
            23 x access:
              DRP_rSR_DiagDIDRequest_DiagDIDRequestData: accessed-variable=rSR_DiagDIDRequest.DiagDIDRequestData
              DRP_rSR_DiagIOCtrlRequest_DiagIOCtrlRequestData: accessed-variable=rSR_DiagIOCtrlRequest.DiagIOCtrlRequestData
              DRP_rSR_DiagRoutineRequest_DiagRoutineRequestData: accessed-variable=rSR_DiagRoutineRequest.DiagRoutineRequestData
              DRA_rSR_DisplaySetPower_DisplaySetPowerData: accessed-variable=rSR_DisplaySetPower.DisplaySetPowerData
              DRA_rSR_FRTT_Status_FRTT_StatusData: accessed-variable=rSR_FRTT_Status.FRTT_StatusData
              DRA_rSR_FastGaugeInfo_FastGaugeInfoData: accessed-variable=rSR_FastGaugeInfo.FastGaugeInfoData
              DRP_rSR_HealthDumpGetData_HealthDumpGetDataData: accessed-variable=rSR_HealthDumpGetData.HealthDumpGetDataData
              DRP_rSR_HealthDumpGetHdr_HealthDumpGetHdrData: accessed-variable=rSR_HealthDumpGetHdr.HealthDumpGetHdrData
              DRA_rSR_HudWarningDisplay_HudWarningDisplayData: accessed-variable=rSR_HudWarningDisplay.HudWarningDisplayData
              DRP_rSR_IgnState_IgnStateData: accessed-variable=rSR_IgnState.IgnStateData
              DRA_rSR_IlluminationData_IlluminationDataData: accessed-variable=rSR_IlluminationData.IlluminationDataData
              DRA_rSR_PowerSystemStateReqChange_PowerSystemStateReqChangeData: accessed-variable=rSR_PowerSystemStateReqChange.PowerSystemStateReqChangeData
              DRA_rSR_RTT_Icon_RTT_IconData: accessed-variable=rSR_RTT_Icon.RTT_IconData
              DRA_rSR_RTT_Status_RTT_StatusData: accessed-variable=rSR_RTT_Status.RTT_StatusData
              DRA_rSR_RTT_Toggle_RTT_ToggleData: accessed-variable=rSR_RTT_Toggle.RTT_ToggleData
              DRA_rSR_ShiftPosIndStatus_ShiftPosIndStatusData: accessed-variable=rSR_ShiftPosIndStatus.ShiftPosIndStatusData
              DRA_rSR_SlowGaugeInfo_SlowGaugeInfoData: accessed-variable=rSR_SlowGaugeInfo.SlowGaugeInfoData
              DRA_rSR_TT_Status_TT_StatusData: accessed-variable=rSR_TT_Status.TT_StatusData
              DRA_rSR_TpmsWarningData_TpmsWarningDataData: accessed-variable=rSR_TpmsWarningData.TpmsWarningDataData
              DRA_rSR_UpdateLongServiceReq_UpdateLongServiceReqData: accessed-variable=rSR_UpdateLongServiceReq.UpdateLongServiceReqData
              DRA_rSR_UpdateShortServiceReq_UpdateShortServiceReqData: accessed-variable=rSR_UpdateShortServiceReq.UpdateShortServiceReqData
              DRA_rSR_WarningDisplay_WarningDisplayData: accessed-variable=rSR_WarningDisplay.WarningDisplayData
              DRA_rSR_WarningExtDisplay_WarningExtDisplayData: accessed-variable=rSR_WarningExtDisplay.WarningExtDisplayData
          data-send-points:
            16 x access:
              DWA_pSR_DisplayCurrentState_DisplayCurrentStateData: accessed-variable=pSR_DisplayCurrentState.DisplayCurrentStateData
              DWA_pSR_EmmcErrorNotifier_EmmcErrorNotifierData: accessed-variable=pSR_EmmcErrorNotifier.EmmcErrorNotifierData
              DSP_pSR_HealthDomainFatalError_HealthDomainFatalErrorData: accessed-variable=pSR_HealthDomainFatalError.HealthDomainFatalErrorData
              DSP_pSR_HealthDomainHeartbeat_HealthDomainHeartbeatData: accessed-variable=pSR_HealthDomainHeartbeat.HealthDomainHeartbeatData
              DSP_pSR_HealthDumpData_HealthDumpDataData: accessed-variable=pSR_HealthDumpData.HealthDumpDataData
              DSP_pSR_HealthDumpHdrInfo_HealthDumpHdrInfoData: accessed-variable=pSR_HealthDumpHdrInfo.HealthDumpHdrInfoData
              DSP_pSR_HealthEventRecord_HealthEventRecordData: accessed-variable=pSR_HealthEventRecord.HealthEventRecordData
              DWA_pSR_HudWarningStatus_HudWarningStatusData: accessed-variable=pSR_HudWarningStatus.HudWarningStatusData
              DSP_pSR_MainHMIReadyStatus_MainHMIReadyStatusData: accessed-variable=pSR_MainHMIReadyStatus.MainHMIReadyStatusData
              DSP_pSR_PowerExtendShutdownTime_PowerExtendShutdownTimeData: accessed-variable=pSR_PowerExtendShutdownTime.PowerExtendShutdownTimeData
              DSP_pSR_PowerKeepSystemAwake_PowerKeepSystemAwakeData: accessed-variable=pSR_PowerKeepSystemAwake.PowerKeepSystemAwakeData
              DWA_pSR_PowerSystemState_PowerSystemStateData: accessed-variable=pSR_PowerSystemState.PowerSystemStateData
              DSP_pSR_SafeHMIReadyStatus_SafeHMIReadyStatusData: accessed-variable=pSR_SafeHMIReadyStatus.SafeHMIReadyStatusData
              DWA_pSR_UpdateShortServiceResp_UpdateShortServiceRespData: accessed-variable=pSR_UpdateShortServiceResp.UpdateShortServiceRespData
              DWA_pSR_WarningDisplayAvailable_WarningDisplayAvailableData: accessed-variable=pSR_WarningDisplayAvailable.WarningDisplayAvailableData
              DWA_pSR_WarningStatus_WarningStatusData: accessed-variable=pSR_WarningStatus.WarningStatusData
          sync call OA_rCS_UclSystemCallbacks_ErrorNotification: operation=rCS_UclSystemCallbacks.ErrorNotification, timeout=0.0
          sync call OA_rCS_UclSystemCallbacks_LinkStatusChanged: operation=rCS_UclSystemCallbacks.LinkStatusChanged, timeout=0.0
        OnDre_HealthDumpGetHdr
          data-receive-point-by-arguments:
            23 x access:
              DRP_rSR_DiagDIDRequest_DiagDIDRequestData: accessed-variable=rSR_DiagDIDRequest.DiagDIDRequestData
              DRP_rSR_DiagIOCtrlRequest_DiagIOCtrlRequestData: accessed-variable=rSR_DiagIOCtrlRequest.DiagIOCtrlRequestData
              DRP_rSR_DiagRoutineRequest_DiagRoutineRequestData: accessed-variable=rSR_DiagRoutineRequest.DiagRoutineRequestData
              DRA_rSR_DisplaySetPower_DisplaySetPowerData: accessed-variable=rSR_DisplaySetPower.DisplaySetPowerData
              DRA_rSR_FRTT_Status_FRTT_StatusData: accessed-variable=rSR_FRTT_Status.FRTT_StatusData
              DRA_rSR_FastGaugeInfo_FastGaugeInfoData: accessed-variable=rSR_FastGaugeInfo.FastGaugeInfoData
              DRP_rSR_HealthDumpGetData_HealthDumpGetDataData: accessed-variable=rSR_HealthDumpGetData.HealthDumpGetDataData
              DRP_rSR_HealthDumpGetHdr_HealthDumpGetHdrData: accessed-variable=rSR_HealthDumpGetHdr.HealthDumpGetHdrData
              DRA_rSR_HudWarningDisplay_HudWarningDisplayData: accessed-variable=rSR_HudWarningDisplay.HudWarningDisplayData
              DRP_rSR_IgnState_IgnStateData: accessed-variable=rSR_IgnState.IgnStateData
              DRA_rSR_IlluminationData_IlluminationDataData: accessed-variable=rSR_IlluminationData.IlluminationDataData
              DRA_rSR_PowerSystemStateReqChange_PowerSystemStateReqChangeData: accessed-variable=rSR_PowerSystemStateReqChange.PowerSystemStateReqChangeData
              DRA_rSR_RTT_Icon_RTT_IconData: accessed-variable=rSR_RTT_Icon.RTT_IconData
              DRA_rSR_RTT_Status_RTT_StatusData: accessed-variable=rSR_RTT_Status.RTT_StatusData
              DRA_rSR_RTT_Toggle_RTT_ToggleData: accessed-variable=rSR_RTT_Toggle.RTT_ToggleData
              DRA_rSR_ShiftPosIndStatus_ShiftPosIndStatusData: accessed-variable=rSR_ShiftPosIndStatus.ShiftPosIndStatusData
              DRA_rSR_SlowGaugeInfo_SlowGaugeInfoData: accessed-variable=rSR_SlowGaugeInfo.SlowGaugeInfoData
              DRA_rSR_TT_Status_TT_StatusData: accessed-variable=rSR_TT_Status.TT_StatusData
              DRA_rSR_TpmsWarningData_TpmsWarningDataData: accessed-variable=rSR_TpmsWarningData.TpmsWarningDataData
              DRA_rSR_UpdateLongServiceReq_UpdateLongServiceReqData: accessed-variable=rSR_UpdateLongServiceReq.UpdateLongServiceReqData
              DRA_rSR_UpdateShortServiceReq_UpdateShortServiceReqData: accessed-variable=rSR_UpdateShortServiceReq.UpdateShortServiceReqData
              DRA_rSR_WarningDisplay_WarningDisplayData: accessed-variable=rSR_WarningDisplay.WarningDisplayData
              DRA_rSR_WarningExtDisplay_WarningExtDisplayData: accessed-variable=rSR_WarningExtDisplay.WarningExtDisplayData
          data-send-points:
            16 x access:
              DWA_pSR_DisplayCurrentState_DisplayCurrentStateData: accessed-variable=pSR_DisplayCurrentState.DisplayCurrentStateData
              DWA_pSR_EmmcErrorNotifier_EmmcErrorNotifierData: accessed-variable=pSR_EmmcErrorNotifier.EmmcErrorNotifierData
              DSP_pSR_HealthDomainFatalError_HealthDomainFatalErrorData: accessed-variable=pSR_HealthDomainFatalError.HealthDomainFatalErrorData
              DSP_pSR_HealthDomainHeartbeat_HealthDomainHeartbeatData: accessed-variable=pSR_HealthDomainHeartbeat.HealthDomainHeartbeatData
              DSP_pSR_HealthDumpData_HealthDumpDataData: accessed-variable=pSR_HealthDumpData.HealthDumpDataData
              DSP_pSR_HealthDumpHdrInfo_HealthDumpHdrInfoData: accessed-variable=pSR_HealthDumpHdrInfo.HealthDumpHdrInfoData
              DSP_pSR_HealthEventRecord_HealthEventRecordData: accessed-variable=pSR_HealthEventRecord.HealthEventRecordData
              DWA_pSR_HudWarningStatus_HudWarningStatusData: accessed-variable=pSR_HudWarningStatus.HudWarningStatusData
              DSP_pSR_MainHMIReadyStatus_MainHMIReadyStatusData: accessed-variable=pSR_MainHMIReadyStatus.MainHMIReadyStatusData
              DSP_pSR_PowerExtendShutdownTime_PowerExtendShutdownTimeData: accessed-variable=pSR_PowerExtendShutdownTime.PowerExtendShutdownTimeData
              DSP_pSR_PowerKeepSystemAwake_PowerKeepSystemAwakeData: accessed-variable=pSR_PowerKeepSystemAwake.PowerKeepSystemAwakeData
              DWA_pSR_PowerSystemState_PowerSystemStateData: accessed-variable=pSR_PowerSystemState.PowerSystemStateData
              DSP_pSR_SafeHMIReadyStatus_SafeHMIReadyStatusData: accessed-variable=pSR_SafeHMIReadyStatus.SafeHMIReadyStatusData
              DWA_pSR_UpdateShortServiceResp_UpdateShortServiceRespData: accessed-variable=pSR_UpdateShortServiceResp.UpdateShortServiceRespData
              DWA_pSR_WarningDisplayAvailable_WarningDisplayAvailableData: accessed-variable=pSR_WarningDisplayAvailable.WarningDisplayAvailableData
              DWA_pSR_WarningStatus_WarningStatusData: accessed-variable=pSR_WarningStatus.WarningStatusData
          sync call OA_rCS_UclSystemCallbacks_ErrorNotification: operation=rCS_UclSystemCallbacks.ErrorNotification, timeout=0.0
          sync call OA_rCS_UclSystemCallbacks_LinkStatusChanged: operation=rCS_UclSystemCallbacks.LinkStatusChanged, timeout=0.0
        OnDre_IlluminationData
          data-receive-point-by-arguments:
            23 x access:
              DRP_rSR_DiagDIDRequest_DiagDIDRequestData: accessed-variable=rSR_DiagDIDRequest.DiagDIDRequestData
              DRP_rSR_DiagIOCtrlRequest_DiagIOCtrlRequestData: accessed-variable=rSR_DiagIOCtrlRequest.DiagIOCtrlRequestData
              DRP_rSR_DiagRoutineRequest_DiagRoutineRequestData: accessed-variable=rSR_DiagRoutineRequest.DiagRoutineRequestData
              DRA_rSR_DisplaySetPower_DisplaySetPowerData: accessed-variable=rSR_DisplaySetPower.DisplaySetPowerData
              DRA_rSR_FRTT_Status_FRTT_StatusData: accessed-variable=rSR_FRTT_Status.FRTT_StatusData
              DRA_rSR_FastGaugeInfo_FastGaugeInfoData: accessed-variable=rSR_FastGaugeInfo.FastGaugeInfoData
              DRP_rSR_HealthDumpGetData_HealthDumpGetDataData: accessed-variable=rSR_HealthDumpGetData.HealthDumpGetDataData
              DRP_rSR_HealthDumpGetHdr_HealthDumpGetHdrData: accessed-variable=rSR_HealthDumpGetHdr.HealthDumpGetHdrData
              DRA_rSR_HudWarningDisplay_HudWarningDisplayData: accessed-variable=rSR_HudWarningDisplay.HudWarningDisplayData
              DRP_rSR_IgnState_IgnStateData: accessed-variable=rSR_IgnState.IgnStateData
              DRA_rSR_IlluminationData_IlluminationDataData: accessed-variable=rSR_IlluminationData.IlluminationDataData
              DRA_rSR_PowerSystemStateReqChange_PowerSystemStateReqChangeData: accessed-variable=rSR_PowerSystemStateReqChange.PowerSystemStateReqChangeData
              DRA_rSR_RTT_Icon_RTT_IconData: accessed-variable=rSR_RTT_Icon.RTT_IconData
              DRA_rSR_RTT_Status_RTT_StatusData: accessed-variable=rSR_RTT_Status.RTT_StatusData
              DRA_rSR_RTT_Toggle_RTT_ToggleData: accessed-variable=rSR_RTT_Toggle.RTT_ToggleData
              DRA_rSR_ShiftPosIndStatus_ShiftPosIndStatusData: accessed-variable=rSR_ShiftPosIndStatus.ShiftPosIndStatusData
              DRA_rSR_SlowGaugeInfo_SlowGaugeInfoData: accessed-variable=rSR_SlowGaugeInfo.SlowGaugeInfoData
              DRA_rSR_TT_Status_TT_StatusData: accessed-variable=rSR_TT_Status.TT_StatusData
              DRA_rSR_TpmsWarningData_TpmsWarningDataData: accessed-variable=rSR_TpmsWarningData.TpmsWarningDataData
              DRA_rSR_UpdateLongServiceReq_UpdateLongServiceReqData: accessed-variable=rSR_UpdateLongServiceReq.UpdateLongServiceReqData
              DRA_rSR_UpdateShortServiceReq_UpdateShortServiceReqData: accessed-variable=rSR_UpdateShortServiceReq.UpdateShortServiceReqData
              DRA_rSR_WarningDisplay_WarningDisplayData: accessed-variable=rSR_WarningDisplay.WarningDisplayData
              DRA_rSR_WarningExtDisplay_WarningExtDisplayData: accessed-variable=rSR_WarningExtDisplay.WarningExtDisplayData
          data-send-points:
            16 x access:
              DWA_pSR_DisplayCurrentState_DisplayCurrentStateData: accessed-variable=pSR_DisplayCurrentState.DisplayCurrentStateData
              DWA_pSR_EmmcErrorNotifier_EmmcErrorNotifierData: accessed-variable=pSR_EmmcErrorNotifier.EmmcErrorNotifierData
              DSP_pSR_HealthDomainFatalError_HealthDomainFatalErrorData: accessed-variable=pSR_HealthDomainFatalError.HealthDomainFatalErrorData
              DSP_pSR_HealthDomainHeartbeat_HealthDomainHeartbeatData: accessed-variable=pSR_HealthDomainHeartbeat.HealthDomainHeartbeatData
              DSP_pSR_HealthDumpData_HealthDumpDataData: accessed-variable=pSR_HealthDumpData.HealthDumpDataData
              DSP_pSR_HealthDumpHdrInfo_HealthDumpHdrInfoData: accessed-variable=pSR_HealthDumpHdrInfo.HealthDumpHdrInfoData
              DSP_pSR_HealthEventRecord_HealthEventRecordData: accessed-variable=pSR_HealthEventRecord.HealthEventRecordData
              DWA_pSR_HudWarningStatus_HudWarningStatusData: accessed-variable=pSR_HudWarningStatus.HudWarningStatusData
              DSP_pSR_MainHMIReadyStatus_MainHMIReadyStatusData: accessed-variable=pSR_MainHMIReadyStatus.MainHMIReadyStatusData
              DSP_pSR_PowerExtendShutdownTime_PowerExtendShutdownTimeData: accessed-variable=pSR_PowerExtendShutdownTime.PowerExtendShutdownTimeData
              DSP_pSR_PowerKeepSystemAwake_PowerKeepSystemAwakeData: accessed-variable=pSR_PowerKeepSystemAwake.PowerKeepSystemAwakeData
              DWA_pSR_PowerSystemState_PowerSystemStateData: accessed-variable=pSR_PowerSystemState.PowerSystemStateData
              DSP_pSR_SafeHMIReadyStatus_SafeHMIReadyStatusData: accessed-variable=pSR_SafeHMIReadyStatus.SafeHMIReadyStatusData
              DWA_pSR_UpdateShortServiceResp_UpdateShortServiceRespData: accessed-variable=pSR_UpdateShortServiceResp.UpdateShortServiceRespData
              DWA_pSR_WarningDisplayAvailable_WarningDisplayAvailableData: accessed-variable=pSR_WarningDisplayAvailable.WarningDisplayAvailableData
              DWA_pSR_WarningStatus_WarningStatusData: accessed-variable=pSR_WarningStatus.WarningStatusData
          sync call OA_rCS_UclSystemCallbacks_ErrorNotification: operation=rCS_UclSystemCallbacks.ErrorNotification, timeout=0.0
          sync call OA_rCS_UclSystemCallbacks_LinkStatusChanged: operation=rCS_UclSystemCallbacks.LinkStatusChanged, timeout=0.0
        OnDre_PowerSystemStateReqChange
          data-receive-point-by-arguments:
            23 x access:
              DRP_rSR_DiagDIDRequest_DiagDIDRequestData: accessed-variable=rSR_DiagDIDRequest.DiagDIDRequestData
              DRP_rSR_DiagIOCtrlRequest_DiagIOCtrlRequestData: accessed-variable=rSR_DiagIOCtrlRequest.DiagIOCtrlRequestData
              DRP_rSR_DiagRoutineRequest_DiagRoutineRequestData: accessed-variable=rSR_DiagRoutineRequest.DiagRoutineRequestData
              DRA_rSR_DisplaySetPower_DisplaySetPowerData: accessed-variable=rSR_DisplaySetPower.DisplaySetPowerData
              DRA_rSR_FRTT_Status_FRTT_StatusData: accessed-variable=rSR_FRTT_Status.FRTT_StatusData
              DRA_rSR_FastGaugeInfo_FastGaugeInfoData: accessed-variable=rSR_FastGaugeInfo.FastGaugeInfoData
              DRP_rSR_HealthDumpGetData_HealthDumpGetDataData: accessed-variable=rSR_HealthDumpGetData.HealthDumpGetDataData
              DRP_rSR_HealthDumpGetHdr_HealthDumpGetHdrData: accessed-variable=rSR_HealthDumpGetHdr.HealthDumpGetHdrData
              DRA_rSR_HudWarningDisplay_HudWarningDisplayData: accessed-variable=rSR_HudWarningDisplay.HudWarningDisplayData
              DRP_rSR_IgnState_IgnStateData: accessed-variable=rSR_IgnState.IgnStateData
              DRA_rSR_IlluminationData_IlluminationDataData: accessed-variable=rSR_IlluminationData.IlluminationDataData
              DRA_rSR_PowerSystemStateReqChange_PowerSystemStateReqChangeData: accessed-variable=rSR_PowerSystemStateReqChange.PowerSystemStateReqChangeData
              DRA_rSR_RTT_Icon_RTT_IconData: accessed-variable=rSR_RTT_Icon.RTT_IconData
              DRA_rSR_RTT_Status_RTT_StatusData: accessed-variable=rSR_RTT_Status.RTT_StatusData
              DRA_rSR_RTT_Toggle_RTT_ToggleData: accessed-variable=rSR_RTT_Toggle.RTT_ToggleData
              DRA_rSR_ShiftPosIndStatus_ShiftPosIndStatusData: accessed-variable=rSR_ShiftPosIndStatus.ShiftPosIndStatusData
              DRA_rSR_SlowGaugeInfo_SlowGaugeInfoData: accessed-variable=rSR_SlowGaugeInfo.SlowGaugeInfoData
              DRA_rSR_TT_Status_TT_StatusData: accessed-variable=rSR_TT_Status.TT_StatusData
              DRA_rSR_TpmsWarningData_TpmsWarningDataData: accessed-variable=rSR_TpmsWarningData.TpmsWarningDataData
              DRA_rSR_UpdateLongServiceReq_UpdateLongServiceReqData: accessed-variable=rSR_UpdateLongServiceReq.UpdateLongServiceReqData
              DRA_rSR_UpdateShortServiceReq_UpdateShortServiceReqData: accessed-variable=rSR_UpdateShortServiceReq.UpdateShortServiceReqData
              DRA_rSR_WarningDisplay_WarningDisplayData: accessed-variable=rSR_WarningDisplay.WarningDisplayData
              DRA_rSR_WarningExtDisplay_WarningExtDisplayData: accessed-variable=rSR_WarningExtDisplay.WarningExtDisplayData
          data-send-points:
            16 x access:
              DWA_pSR_DisplayCurrentState_DisplayCurrentStateData: accessed-variable=pSR_DisplayCurrentState.DisplayCurrentStateData
              DWA_pSR_EmmcErrorNotifier_EmmcErrorNotifierData: accessed-variable=pSR_EmmcErrorNotifier.EmmcErrorNotifierData
              DSP_pSR_HealthDomainFatalError_HealthDomainFatalErrorData: accessed-variable=pSR_HealthDomainFatalError.HealthDomainFatalErrorData
              DSP_pSR_HealthDomainHeartbeat_HealthDomainHeartbeatData: accessed-variable=pSR_HealthDomainHeartbeat.HealthDomainHeartbeatData
              DSP_pSR_HealthDumpData_HealthDumpDataData: accessed-variable=pSR_HealthDumpData.HealthDumpDataData
              DSP_pSR_HealthDumpHdrInfo_HealthDumpHdrInfoData: accessed-variable=pSR_HealthDumpHdrInfo.HealthDumpHdrInfoData
              DSP_pSR_HealthEventRecord_HealthEventRecordData: accessed-variable=pSR_HealthEventRecord.HealthEventRecordData
              DWA_pSR_HudWarningStatus_HudWarningStatusData: accessed-variable=pSR_HudWarningStatus.HudWarningStatusData
              DSP_pSR_MainHMIReadyStatus_MainHMIReadyStatusData: accessed-variable=pSR_MainHMIReadyStatus.MainHMIReadyStatusData
              DSP_pSR_PowerExtendShutdownTime_PowerExtendShutdownTimeData: accessed-variable=pSR_PowerExtendShutdownTime.PowerExtendShutdownTimeData
              DSP_pSR_PowerKeepSystemAwake_PowerKeepSystemAwakeData: accessed-variable=pSR_PowerKeepSystemAwake.PowerKeepSystemAwakeData
              DWA_pSR_PowerSystemState_PowerSystemStateData: accessed-variable=pSR_PowerSystemState.PowerSystemStateData
              DSP_pSR_SafeHMIReadyStatus_SafeHMIReadyStatusData: accessed-variable=pSR_SafeHMIReadyStatus.SafeHMIReadyStatusData
              DWA_pSR_UpdateShortServiceResp_UpdateShortServiceRespData: accessed-variable=pSR_UpdateShortServiceResp.UpdateShortServiceRespData
              DWA_pSR_WarningDisplayAvailable_WarningDisplayAvailableData: accessed-variable=pSR_WarningDisplayAvailable.WarningDisplayAvailableData
              DWA_pSR_WarningStatus_WarningStatusData: accessed-variable=pSR_WarningStatus.WarningStatusData
          sync call OA_rCS_UclSystemCallbacks_ErrorNotification: operation=rCS_UclSystemCallbacks.ErrorNotification, timeout=0.0
          sync call OA_rCS_UclSystemCallbacks_LinkStatusChanged: operation=rCS_UclSystemCallbacks.LinkStatusChanged, timeout=0.0
        OnDre_RTT_Icon
          data-receive-point-by-arguments:
            23 x access:
              DRP_rSR_DiagDIDRequest_DiagDIDRequestData: accessed-variable=rSR_DiagDIDRequest.DiagDIDRequestData
              DRP_rSR_DiagIOCtrlRequest_DiagIOCtrlRequestData: accessed-variable=rSR_DiagIOCtrlRequest.DiagIOCtrlRequestData
              DRP_rSR_DiagRoutineRequest_DiagRoutineRequestData: accessed-variable=rSR_DiagRoutineRequest.DiagRoutineRequestData
              DRA_rSR_DisplaySetPower_DisplaySetPowerData: accessed-variable=rSR_DisplaySetPower.DisplaySetPowerData
              DRA_rSR_FRTT_Status_FRTT_StatusData: accessed-variable=rSR_FRTT_Status.FRTT_StatusData
              DRA_rSR_FastGaugeInfo_FastGaugeInfoData: accessed-variable=rSR_FastGaugeInfo.FastGaugeInfoData
              DRP_rSR_HealthDumpGetData_HealthDumpGetDataData: accessed-variable=rSR_HealthDumpGetData.HealthDumpGetDataData
              DRP_rSR_HealthDumpGetHdr_HealthDumpGetHdrData: accessed-variable=rSR_HealthDumpGetHdr.HealthDumpGetHdrData
              DRA_rSR_HudWarningDisplay_HudWarningDisplayData: accessed-variable=rSR_HudWarningDisplay.HudWarningDisplayData
              DRP_rSR_IgnState_IgnStateData: accessed-variable=rSR_IgnState.IgnStateData
              DRA_rSR_IlluminationData_IlluminationDataData: accessed-variable=rSR_IlluminationData.IlluminationDataData
              DRA_rSR_PowerSystemStateReqChange_PowerSystemStateReqChangeData: accessed-variable=rSR_PowerSystemStateReqChange.PowerSystemStateReqChangeData
              DRA_rSR_RTT_Icon_RTT_IconData: accessed-variable=rSR_RTT_Icon.RTT_IconData
              DRA_rSR_RTT_Status_RTT_StatusData: accessed-variable=rSR_RTT_Status.RTT_StatusData
              DRA_rSR_RTT_Toggle_RTT_ToggleData: accessed-variable=rSR_RTT_Toggle.RTT_ToggleData
              DRA_rSR_ShiftPosIndStatus_ShiftPosIndStatusData: accessed-variable=rSR_ShiftPosIndStatus.ShiftPosIndStatusData
              DRA_rSR_SlowGaugeInfo_SlowGaugeInfoData: accessed-variable=rSR_SlowGaugeInfo.SlowGaugeInfoData
              DRA_rSR_TT_Status_TT_StatusData: accessed-variable=rSR_TT_Status.TT_StatusData
              DRA_rSR_TpmsWarningData_TpmsWarningDataData: accessed-variable=rSR_TpmsWarningData.TpmsWarningDataData
              DRA_rSR_UpdateLongServiceReq_UpdateLongServiceReqData: accessed-variable=rSR_UpdateLongServiceReq.UpdateLongServiceReqData
              DRA_rSR_UpdateShortServiceReq_UpdateShortServiceReqData: accessed-variable=rSR_UpdateShortServiceReq.UpdateShortServiceReqData
              DRA_rSR_WarningDisplay_WarningDisplayData: accessed-variable=rSR_WarningDisplay.WarningDisplayData
              DRA_rSR_WarningExtDisplay_WarningExtDisplayData: accessed-variable=rSR_WarningExtDisplay.WarningExtDisplayData
          data-send-points:
            16 x access:
              DWA_pSR_DisplayCurrentState_DisplayCurrentStateData: accessed-variable=pSR_DisplayCurrentState.DisplayCurrentStateData
              DWA_pSR_EmmcErrorNotifier_EmmcErrorNotifierData: accessed-variable=pSR_EmmcErrorNotifier.EmmcErrorNotifierData
              DSP_pSR_HealthDomainFatalError_HealthDomainFatalErrorData: accessed-variable=pSR_HealthDomainFatalError.HealthDomainFatalErrorData
              DSP_pSR_HealthDomainHeartbeat_HealthDomainHeartbeatData: accessed-variable=pSR_HealthDomainHeartbeat.HealthDomainHeartbeatData
              DSP_pSR_HealthDumpData_HealthDumpDataData: accessed-variable=pSR_HealthDumpData.HealthDumpDataData
              DSP_pSR_HealthDumpHdrInfo_HealthDumpHdrInfoData: accessed-variable=pSR_HealthDumpHdrInfo.HealthDumpHdrInfoData
              DSP_pSR_HealthEventRecord_HealthEventRecordData: accessed-variable=pSR_HealthEventRecord.HealthEventRecordData
              DWA_pSR_HudWarningStatus_HudWarningStatusData: accessed-variable=pSR_HudWarningStatus.HudWarningStatusData
              DSP_pSR_MainHMIReadyStatus_MainHMIReadyStatusData: accessed-variable=pSR_MainHMIReadyStatus.MainHMIReadyStatusData
              DSP_pSR_PowerExtendShutdownTime_PowerExtendShutdownTimeData: accessed-variable=pSR_PowerExtendShutdownTime.PowerExtendShutdownTimeData
              DSP_pSR_PowerKeepSystemAwake_PowerKeepSystemAwakeData: accessed-variable=pSR_PowerKeepSystemAwake.PowerKeepSystemAwakeData
              DWA_pSR_PowerSystemState_PowerSystemStateData: accessed-variable=pSR_PowerSystemState.PowerSystemStateData
              DSP_pSR_SafeHMIReadyStatus_SafeHMIReadyStatusData: accessed-variable=pSR_SafeHMIReadyStatus.SafeHMIReadyStatusData
              DWA_pSR_UpdateShortServiceResp_UpdateShortServiceRespData: accessed-variable=pSR_UpdateShortServiceResp.UpdateShortServiceRespData
              DWA_pSR_WarningDisplayAvailable_WarningDisplayAvailableData: accessed-variable=pSR_WarningDisplayAvailable.WarningDisplayAvailableData
              DWA_pSR_WarningStatus_WarningStatusData: accessed-variable=pSR_WarningStatus.WarningStatusData
          sync call OA_rCS_UclSystemCallbacks_ErrorNotification: operation=rCS_UclSystemCallbacks.ErrorNotification, timeout=0.0
          sync call OA_rCS_UclSystemCallbacks_LinkStatusChanged: operation=rCS_UclSystemCallbacks.LinkStatusChanged, timeout=0.0
        OnDre_RTT_Status
          data-receive-point-by-arguments:
            23 x access:
              DRP_rSR_DiagDIDRequest_DiagDIDRequestData: accessed-variable=rSR_DiagDIDRequest.DiagDIDRequestData
              DRP_rSR_DiagIOCtrlRequest_DiagIOCtrlRequestData: accessed-variable=rSR_DiagIOCtrlRequest.DiagIOCtrlRequestData
              DRP_rSR_DiagRoutineRequest_DiagRoutineRequestData: accessed-variable=rSR_DiagRoutineRequest.DiagRoutineRequestData
              DRA_rSR_DisplaySetPower_DisplaySetPowerData: accessed-variable=rSR_DisplaySetPower.DisplaySetPowerData
              DRA_rSR_FRTT_Status_FRTT_StatusData: accessed-variable=rSR_FRTT_Status.FRTT_StatusData
              DRA_rSR_FastGaugeInfo_FastGaugeInfoData: accessed-variable=rSR_FastGaugeInfo.FastGaugeInfoData
              DRP_rSR_HealthDumpGetData_HealthDumpGetDataData: accessed-variable=rSR_HealthDumpGetData.HealthDumpGetDataData
              DRP_rSR_HealthDumpGetHdr_HealthDumpGetHdrData: accessed-variable=rSR_HealthDumpGetHdr.HealthDumpGetHdrData
              DRA_rSR_HudWarningDisplay_HudWarningDisplayData: accessed-variable=rSR_HudWarningDisplay.HudWarningDisplayData
              DRP_rSR_IgnState_IgnStateData: accessed-variable=rSR_IgnState.IgnStateData
              DRA_rSR_IlluminationData_IlluminationDataData: accessed-variable=rSR_IlluminationData.IlluminationDataData
              DRA_rSR_PowerSystemStateReqChange_PowerSystemStateReqChangeData: accessed-variable=rSR_PowerSystemStateReqChange.PowerSystemStateReqChangeData
              DRA_rSR_RTT_Icon_RTT_IconData: accessed-variable=rSR_RTT_Icon.RTT_IconData
              DRA_rSR_RTT_Status_RTT_StatusData: accessed-variable=rSR_RTT_Status.RTT_StatusData
              DRA_rSR_RTT_Toggle_RTT_ToggleData: accessed-variable=rSR_RTT_Toggle.RTT_ToggleData
              DRA_rSR_ShiftPosIndStatus_ShiftPosIndStatusData: accessed-variable=rSR_ShiftPosIndStatus.ShiftPosIndStatusData
              DRA_rSR_SlowGaugeInfo_SlowGaugeInfoData: accessed-variable=rSR_SlowGaugeInfo.SlowGaugeInfoData
              DRA_rSR_TT_Status_TT_StatusData: accessed-variable=rSR_TT_Status.TT_StatusData
              DRA_rSR_TpmsWarningData_TpmsWarningDataData: accessed-variable=rSR_TpmsWarningData.TpmsWarningDataData
              DRA_rSR_UpdateLongServiceReq_UpdateLongServiceReqData: accessed-variable=rSR_UpdateLongServiceReq.UpdateLongServiceReqData
              DRA_rSR_UpdateShortServiceReq_UpdateShortServiceReqData: accessed-variable=rSR_UpdateShortServiceReq.UpdateShortServiceReqData
              DRA_rSR_WarningDisplay_WarningDisplayData: accessed-variable=rSR_WarningDisplay.WarningDisplayData
              DRA_rSR_WarningExtDisplay_WarningExtDisplayData: accessed-variable=rSR_WarningExtDisplay.WarningExtDisplayData
          data-send-points:
            16 x access:
              DWA_pSR_DisplayCurrentState_DisplayCurrentStateData: accessed-variable=pSR_DisplayCurrentState.DisplayCurrentStateData
              DWA_pSR_EmmcErrorNotifier_EmmcErrorNotifierData: accessed-variable=pSR_EmmcErrorNotifier.EmmcErrorNotifierData
              DSP_pSR_HealthDomainFatalError_HealthDomainFatalErrorData: accessed-variable=pSR_HealthDomainFatalError.HealthDomainFatalErrorData
              DSP_pSR_HealthDomainHeartbeat_HealthDomainHeartbeatData: accessed-variable=pSR_HealthDomainHeartbeat.HealthDomainHeartbeatData
              DSP_pSR_HealthDumpData_HealthDumpDataData: accessed-variable=pSR_HealthDumpData.HealthDumpDataData
              DSP_pSR_HealthDumpHdrInfo_HealthDumpHdrInfoData: accessed-variable=pSR_HealthDumpHdrInfo.HealthDumpHdrInfoData
              DSP_pSR_HealthEventRecord_HealthEventRecordData: accessed-variable=pSR_HealthEventRecord.HealthEventRecordData
              DWA_pSR_HudWarningStatus_HudWarningStatusData: accessed-variable=pSR_HudWarningStatus.HudWarningStatusData
              DSP_pSR_MainHMIReadyStatus_MainHMIReadyStatusData: accessed-variable=pSR_MainHMIReadyStatus.MainHMIReadyStatusData
              DSP_pSR_PowerExtendShutdownTime_PowerExtendShutdownTimeData: accessed-variable=pSR_PowerExtendShutdownTime.PowerExtendShutdownTimeData
              DSP_pSR_PowerKeepSystemAwake_PowerKeepSystemAwakeData: accessed-variable=pSR_PowerKeepSystemAwake.PowerKeepSystemAwakeData
              DWA_pSR_PowerSystemState_PowerSystemStateData: accessed-variable=pSR_PowerSystemState.PowerSystemStateData
              DSP_pSR_SafeHMIReadyStatus_SafeHMIReadyStatusData: accessed-variable=pSR_SafeHMIReadyStatus.SafeHMIReadyStatusData
              DWA_pSR_UpdateShortServiceResp_UpdateShortServiceRespData: accessed-variable=pSR_UpdateShortServiceResp.UpdateShortServiceRespData
              DWA_pSR_WarningDisplayAvailable_WarningDisplayAvailableData: accessed-variable=pSR_WarningDisplayAvailable.WarningDisplayAvailableData
              DWA_pSR_WarningStatus_WarningStatusData: accessed-variable=pSR_WarningStatus.WarningStatusData
          sync call OA_rCS_UclSystemCallbacks_ErrorNotification: operation=rCS_UclSystemCallbacks.ErrorNotification, timeout=0.0
          sync call OA_rCS_UclSystemCallbacks_LinkStatusChanged: operation=rCS_UclSystemCallbacks.LinkStatusChanged, timeout=0.0
        OnDre_RTT_Toggle
          data-receive-point-by-arguments:
            23 x access:
              DRP_rSR_DiagDIDRequest_DiagDIDRequestData: accessed-variable=rSR_DiagDIDRequest.DiagDIDRequestData
              DRP_rSR_DiagIOCtrlRequest_DiagIOCtrlRequestData: accessed-variable=rSR_DiagIOCtrlRequest.DiagIOCtrlRequestData
              DRP_rSR_DiagRoutineRequest_DiagRoutineRequestData: accessed-variable=rSR_DiagRoutineRequest.DiagRoutineRequestData
              DRA_rSR_DisplaySetPower_DisplaySetPowerData: accessed-variable=rSR_DisplaySetPower.DisplaySetPowerData
              DRA_rSR_FRTT_Status_FRTT_StatusData: accessed-variable=rSR_FRTT_Status.FRTT_StatusData
              DRA_rSR_FastGaugeInfo_FastGaugeInfoData: accessed-variable=rSR_FastGaugeInfo.FastGaugeInfoData
              DRP_rSR_HealthDumpGetData_HealthDumpGetDataData: accessed-variable=rSR_HealthDumpGetData.HealthDumpGetDataData
              DRP_rSR_HealthDumpGetHdr_HealthDumpGetHdrData: accessed-variable=rSR_HealthDumpGetHdr.HealthDumpGetHdrData
              DRA_rSR_HudWarningDisplay_HudWarningDisplayData: accessed-variable=rSR_HudWarningDisplay.HudWarningDisplayData
              DRP_rSR_IgnState_IgnStateData: accessed-variable=rSR_IgnState.IgnStateData
              DRA_rSR_IlluminationData_IlluminationDataData: accessed-variable=rSR_IlluminationData.IlluminationDataData
              DRA_rSR_PowerSystemStateReqChange_PowerSystemStateReqChangeData: accessed-variable=rSR_PowerSystemStateReqChange.PowerSystemStateReqChangeData
              DRA_rSR_RTT_Icon_RTT_IconData: accessed-variable=rSR_RTT_Icon.RTT_IconData
              DRA_rSR_RTT_Status_RTT_StatusData: accessed-variable=rSR_RTT_Status.RTT_StatusData
              DRA_rSR_RTT_Toggle_RTT_ToggleData: accessed-variable=rSR_RTT_Toggle.RTT_ToggleData
              DRA_rSR_ShiftPosIndStatus_ShiftPosIndStatusData: accessed-variable=rSR_ShiftPosIndStatus.ShiftPosIndStatusData
              DRA_rSR_SlowGaugeInfo_SlowGaugeInfoData: accessed-variable=rSR_SlowGaugeInfo.SlowGaugeInfoData
              DRA_rSR_TT_Status_TT_StatusData: accessed-variable=rSR_TT_Status.TT_StatusData
              DRA_rSR_TpmsWarningData_TpmsWarningDataData: accessed-variable=rSR_TpmsWarningData.TpmsWarningDataData
              DRA_rSR_UpdateLongServiceReq_UpdateLongServiceReqData: accessed-variable=rSR_UpdateLongServiceReq.UpdateLongServiceReqData
              DRA_rSR_UpdateShortServiceReq_UpdateShortServiceReqData: accessed-variable=rSR_UpdateShortServiceReq.UpdateShortServiceReqData
              DRA_rSR_WarningDisplay_WarningDisplayData: accessed-variable=rSR_WarningDisplay.WarningDisplayData
              DRA_rSR_WarningExtDisplay_WarningExtDisplayData: accessed-variable=rSR_WarningExtDisplay.WarningExtDisplayData
          data-send-points:
            16 x access:
              DWA_pSR_DisplayCurrentState_DisplayCurrentStateData: accessed-variable=pSR_DisplayCurrentState.DisplayCurrentStateData
              DWA_pSR_EmmcErrorNotifier_EmmcErrorNotifierData: accessed-variable=pSR_EmmcErrorNotifier.EmmcErrorNotifierData
              DSP_pSR_HealthDomainFatalError_HealthDomainFatalErrorData: accessed-variable=pSR_HealthDomainFatalError.HealthDomainFatalErrorData
              DSP_pSR_HealthDomainHeartbeat_HealthDomainHeartbeatData: accessed-variable=pSR_HealthDomainHeartbeat.HealthDomainHeartbeatData
              DSP_pSR_HealthDumpData_HealthDumpDataData: accessed-variable=pSR_HealthDumpData.HealthDumpDataData
              DSP_pSR_HealthDumpHdrInfo_HealthDumpHdrInfoData: accessed-variable=pSR_HealthDumpHdrInfo.HealthDumpHdrInfoData
              DSP_pSR_HealthEventRecord_HealthEventRecordData: accessed-variable=pSR_HealthEventRecord.HealthEventRecordData
              DWA_pSR_HudWarningStatus_HudWarningStatusData: accessed-variable=pSR_HudWarningStatus.HudWarningStatusData
              DSP_pSR_MainHMIReadyStatus_MainHMIReadyStatusData: accessed-variable=pSR_MainHMIReadyStatus.MainHMIReadyStatusData
              DSP_pSR_PowerExtendShutdownTime_PowerExtendShutdownTimeData: accessed-variable=pSR_PowerExtendShutdownTime.PowerExtendShutdownTimeData
              DSP_pSR_PowerKeepSystemAwake_PowerKeepSystemAwakeData: accessed-variable=pSR_PowerKeepSystemAwake.PowerKeepSystemAwakeData
              DWA_pSR_PowerSystemState_PowerSystemStateData: accessed-variable=pSR_PowerSystemState.PowerSystemStateData
              DSP_pSR_SafeHMIReadyStatus_SafeHMIReadyStatusData: accessed-variable=pSR_SafeHMIReadyStatus.SafeHMIReadyStatusData
              DWA_pSR_UpdateShortServiceResp_UpdateShortServiceRespData: accessed-variable=pSR_UpdateShortServiceResp.UpdateShortServiceRespData
              DWA_pSR_WarningDisplayAvailable_WarningDisplayAvailableData: accessed-variable=pSR_WarningDisplayAvailable.WarningDisplayAvailableData
              DWA_pSR_WarningStatus_WarningStatusData: accessed-variable=pSR_WarningStatus.WarningStatusData
          sync call OA_rCS_UclSystemCallbacks_ErrorNotification: operation=rCS_UclSystemCallbacks.ErrorNotification, timeout=0.0
          sync call OA_rCS_UclSystemCallbacks_LinkStatusChanged: operation=rCS_UclSystemCallbacks.LinkStatusChanged, timeout=0.0
        OnDre_ShiftPosIndStatus
          data-receive-point-by-arguments:
            23 x access:
              DRP_rSR_DiagDIDRequest_DiagDIDRequestData: accessed-variable=rSR_DiagDIDRequest.DiagDIDRequestData
              DRP_rSR_DiagIOCtrlRequest_DiagIOCtrlRequestData: accessed-variable=rSR_DiagIOCtrlRequest.DiagIOCtrlRequestData
              DRP_rSR_DiagRoutineRequest_DiagRoutineRequestData: accessed-variable=rSR_DiagRoutineRequest.DiagRoutineRequestData
              DRA_rSR_DisplaySetPower_DisplaySetPowerData: accessed-variable=rSR_DisplaySetPower.DisplaySetPowerData
              DRA_rSR_FRTT_Status_FRTT_StatusData: accessed-variable=rSR_FRTT_Status.FRTT_StatusData
              DRA_rSR_FastGaugeInfo_FastGaugeInfoData: accessed-variable=rSR_FastGaugeInfo.FastGaugeInfoData
              DRP_rSR_HealthDumpGetData_HealthDumpGetDataData: accessed-variable=rSR_HealthDumpGetData.HealthDumpGetDataData
              DRP_rSR_HealthDumpGetHdr_HealthDumpGetHdrData: accessed-variable=rSR_HealthDumpGetHdr.HealthDumpGetHdrData
              DRA_rSR_HudWarningDisplay_HudWarningDisplayData: accessed-variable=rSR_HudWarningDisplay.HudWarningDisplayData
              DRP_rSR_IgnState_IgnStateData: accessed-variable=rSR_IgnState.IgnStateData
              DRA_rSR_IlluminationData_IlluminationDataData: accessed-variable=rSR_IlluminationData.IlluminationDataData
              DRA_rSR_PowerSystemStateReqChange_PowerSystemStateReqChangeData: accessed-variable=rSR_PowerSystemStateReqChange.PowerSystemStateReqChangeData
              DRA_rSR_RTT_Icon_RTT_IconData: accessed-variable=rSR_RTT_Icon.RTT_IconData
              DRA_rSR_RTT_Status_RTT_StatusData: accessed-variable=rSR_RTT_Status.RTT_StatusData
              DRA_rSR_RTT_Toggle_RTT_ToggleData: accessed-variable=rSR_RTT_Toggle.RTT_ToggleData
              DRA_rSR_ShiftPosIndStatus_ShiftPosIndStatusData: accessed-variable=rSR_ShiftPosIndStatus.ShiftPosIndStatusData
              DRA_rSR_SlowGaugeInfo_SlowGaugeInfoData: accessed-variable=rSR_SlowGaugeInfo.SlowGaugeInfoData
              DRA_rSR_TT_Status_TT_StatusData: accessed-variable=rSR_TT_Status.TT_StatusData
              DRA_rSR_TpmsWarningData_TpmsWarningDataData: accessed-variable=rSR_TpmsWarningData.TpmsWarningDataData
              DRA_rSR_UpdateLongServiceReq_UpdateLongServiceReqData: accessed-variable=rSR_UpdateLongServiceReq.UpdateLongServiceReqData
              DRA_rSR_UpdateShortServiceReq_UpdateShortServiceReqData: accessed-variable=rSR_UpdateShortServiceReq.UpdateShortServiceReqData
              DRA_rSR_WarningDisplay_WarningDisplayData: accessed-variable=rSR_WarningDisplay.WarningDisplayData
              DRA_rSR_WarningExtDisplay_WarningExtDisplayData: accessed-variable=rSR_WarningExtDisplay.WarningExtDisplayData
          data-send-points:
            16 x access:
              DWA_pSR_DisplayCurrentState_DisplayCurrentStateData: accessed-variable=pSR_DisplayCurrentState.DisplayCurrentStateData
              DWA_pSR_EmmcErrorNotifier_EmmcErrorNotifierData: accessed-variable=pSR_EmmcErrorNotifier.EmmcErrorNotifierData
              DSP_pSR_HealthDomainFatalError_HealthDomainFatalErrorData: accessed-variable=pSR_HealthDomainFatalError.HealthDomainFatalErrorData
              DSP_pSR_HealthDomainHeartbeat_HealthDomainHeartbeatData: accessed-variable=pSR_HealthDomainHeartbeat.HealthDomainHeartbeatData
              DSP_pSR_HealthDumpData_HealthDumpDataData: accessed-variable=pSR_HealthDumpData.HealthDumpDataData
              DSP_pSR_HealthDumpHdrInfo_HealthDumpHdrInfoData: accessed-variable=pSR_HealthDumpHdrInfo.HealthDumpHdrInfoData
              DSP_pSR_HealthEventRecord_HealthEventRecordData: accessed-variable=pSR_HealthEventRecord.HealthEventRecordData
              DWA_pSR_HudWarningStatus_HudWarningStatusData: accessed-variable=pSR_HudWarningStatus.HudWarningStatusData
              DSP_pSR_MainHMIReadyStatus_MainHMIReadyStatusData: accessed-variable=pSR_MainHMIReadyStatus.MainHMIReadyStatusData
              DSP_pSR_PowerExtendShutdownTime_PowerExtendShutdownTimeData: accessed-variable=pSR_PowerExtendShutdownTime.PowerExtendShutdownTimeData
              DSP_pSR_PowerKeepSystemAwake_PowerKeepSystemAwakeData: accessed-variable=pSR_PowerKeepSystemAwake.PowerKeepSystemAwakeData
              DWA_pSR_PowerSystemState_PowerSystemStateData: accessed-variable=pSR_PowerSystemState.PowerSystemStateData
              DSP_pSR_SafeHMIReadyStatus_SafeHMIReadyStatusData: accessed-variable=pSR_SafeHMIReadyStatus.SafeHMIReadyStatusData
              DWA_pSR_UpdateShortServiceResp_UpdateShortServiceRespData: accessed-variable=pSR_UpdateShortServiceResp.UpdateShortServiceRespData
              DWA_pSR_WarningDisplayAvailable_WarningDisplayAvailableData: accessed-variable=pSR_WarningDisplayAvailable.WarningDisplayAvailableData
              DWA_pSR_WarningStatus_WarningStatusData: accessed-variable=pSR_WarningStatus.WarningStatusData
          sync call OA_rCS_UclSystemCallbacks_ErrorNotification: operation=rCS_UclSystemCallbacks.ErrorNotification, timeout=0.0
          sync call OA_rCS_UclSystemCallbacks_LinkStatusChanged: operation=rCS_UclSystemCallbacks.LinkStatusChanged, timeout=0.0
        OnDre_SlowGaugeInfo
          data-receive-point-by-arguments:
            23 x access:
              DRP_rSR_DiagDIDRequest_DiagDIDRequestData: accessed-variable=rSR_DiagDIDRequest.DiagDIDRequestData
              DRP_rSR_DiagIOCtrlRequest_DiagIOCtrlRequestData: accessed-variable=rSR_DiagIOCtrlRequest.DiagIOCtrlRequestData
              DRP_rSR_DiagRoutineRequest_DiagRoutineRequestData: accessed-variable=rSR_DiagRoutineRequest.DiagRoutineRequestData
              DRA_rSR_DisplaySetPower_DisplaySetPowerData: accessed-variable=rSR_DisplaySetPower.DisplaySetPowerData
              DRA_rSR_FRTT_Status_FRTT_StatusData: accessed-variable=rSR_FRTT_Status.FRTT_StatusData
              DRA_rSR_FastGaugeInfo_FastGaugeInfoData: accessed-variable=rSR_FastGaugeInfo.FastGaugeInfoData
              DRP_rSR_HealthDumpGetData_HealthDumpGetDataData: accessed-variable=rSR_HealthDumpGetData.HealthDumpGetDataData
              DRP_rSR_HealthDumpGetHdr_HealthDumpGetHdrData: accessed-variable=rSR_HealthDumpGetHdr.HealthDumpGetHdrData
              DRA_rSR_HudWarningDisplay_HudWarningDisplayData: accessed-variable=rSR_HudWarningDisplay.HudWarningDisplayData
              DRP_rSR_IgnState_IgnStateData: accessed-variable=rSR_IgnState.IgnStateData
              DRA_rSR_IlluminationData_IlluminationDataData: accessed-variable=rSR_IlluminationData.IlluminationDataData
              DRA_rSR_PowerSystemStateReqChange_PowerSystemStateReqChangeData: accessed-variable=rSR_PowerSystemStateReqChange.PowerSystemStateReqChangeData
              DRA_rSR_RTT_Icon_RTT_IconData: accessed-variable=rSR_RTT_Icon.RTT_IconData
              DRA_rSR_RTT_Status_RTT_StatusData: accessed-variable=rSR_RTT_Status.RTT_StatusData
              DRA_rSR_RTT_Toggle_RTT_ToggleData: accessed-variable=rSR_RTT_Toggle.RTT_ToggleData
              DRA_rSR_ShiftPosIndStatus_ShiftPosIndStatusData: accessed-variable=rSR_ShiftPosIndStatus.ShiftPosIndStatusData
              DRA_rSR_SlowGaugeInfo_SlowGaugeInfoData: accessed-variable=rSR_SlowGaugeInfo.SlowGaugeInfoData
              DRA_rSR_TT_Status_TT_StatusData: accessed-variable=rSR_TT_Status.TT_StatusData
              DRA_rSR_TpmsWarningData_TpmsWarningDataData: accessed-variable=rSR_TpmsWarningData.TpmsWarningDataData
              DRA_rSR_UpdateLongServiceReq_UpdateLongServiceReqData: accessed-variable=rSR_UpdateLongServiceReq.UpdateLongServiceReqData
              DRA_rSR_UpdateShortServiceReq_UpdateShortServiceReqData: accessed-variable=rSR_UpdateShortServiceReq.UpdateShortServiceReqData
              DRA_rSR_WarningDisplay_WarningDisplayData: accessed-variable=rSR_WarningDisplay.WarningDisplayData
              DRA_rSR_WarningExtDisplay_WarningExtDisplayData: accessed-variable=rSR_WarningExtDisplay.WarningExtDisplayData
          data-send-points:
            16 x access:
              DWA_pSR_DisplayCurrentState_DisplayCurrentStateData: accessed-variable=pSR_DisplayCurrentState.DisplayCurrentStateData
              DWA_pSR_EmmcErrorNotifier_EmmcErrorNotifierData: accessed-variable=pSR_EmmcErrorNotifier.EmmcErrorNotifierData
              DSP_pSR_HealthDomainFatalError_HealthDomainFatalErrorData: accessed-variable=pSR_HealthDomainFatalError.HealthDomainFatalErrorData
              DSP_pSR_HealthDomainHeartbeat_HealthDomainHeartbeatData: accessed-variable=pSR_HealthDomainHeartbeat.HealthDomainHeartbeatData
              DSP_pSR_HealthDumpData_HealthDumpDataData: accessed-variable=pSR_HealthDumpData.HealthDumpDataData
              DSP_pSR_HealthDumpHdrInfo_HealthDumpHdrInfoData: accessed-variable=pSR_HealthDumpHdrInfo.HealthDumpHdrInfoData
              DSP_pSR_HealthEventRecord_HealthEventRecordData: accessed-variable=pSR_HealthEventRecord.HealthEventRecordData
              DWA_pSR_HudWarningStatus_HudWarningStatusData: accessed-variable=pSR_HudWarningStatus.HudWarningStatusData
              DSP_pSR_MainHMIReadyStatus_MainHMIReadyStatusData: accessed-variable=pSR_MainHMIReadyStatus.MainHMIReadyStatusData
              DSP_pSR_PowerExtendShutdownTime_PowerExtendShutdownTimeData: accessed-variable=pSR_PowerExtendShutdownTime.PowerExtendShutdownTimeData
              DSP_pSR_PowerKeepSystemAwake_PowerKeepSystemAwakeData: accessed-variable=pSR_PowerKeepSystemAwake.PowerKeepSystemAwakeData
              DWA_pSR_PowerSystemState_PowerSystemStateData: accessed-variable=pSR_PowerSystemState.PowerSystemStateData
              DSP_pSR_SafeHMIReadyStatus_SafeHMIReadyStatusData: accessed-variable=pSR_SafeHMIReadyStatus.SafeHMIReadyStatusData
              DWA_pSR_UpdateShortServiceResp_UpdateShortServiceRespData: accessed-variable=pSR_UpdateShortServiceResp.UpdateShortServiceRespData
              DWA_pSR_WarningDisplayAvailable_WarningDisplayAvailableData: accessed-variable=pSR_WarningDisplayAvailable.WarningDisplayAvailableData
              DWA_pSR_WarningStatus_WarningStatusData: accessed-variable=pSR_WarningStatus.WarningStatusData
          sync call OA_rCS_UclSystemCallbacks_ErrorNotification: operation=rCS_UclSystemCallbacks.ErrorNotification, timeout=0.0
          sync call OA_rCS_UclSystemCallbacks_LinkStatusChanged: operation=rCS_UclSystemCallbacks.LinkStatusChanged, timeout=0.0
        OnDre_TT_Status
          data-receive-point-by-arguments:
            23 x access:
              DRP_rSR_DiagDIDRequest_DiagDIDRequestData: accessed-variable=rSR_DiagDIDRequest.DiagDIDRequestData
              DRP_rSR_DiagIOCtrlRequest_DiagIOCtrlRequestData: accessed-variable=rSR_DiagIOCtrlRequest.DiagIOCtrlRequestData
              DRP_rSR_DiagRoutineRequest_DiagRoutineRequestData: accessed-variable=rSR_DiagRoutineRequest.DiagRoutineRequestData
              DRA_rSR_DisplaySetPower_DisplaySetPowerData: accessed-variable=rSR_DisplaySetPower.DisplaySetPowerData
              DRA_rSR_FRTT_Status_FRTT_StatusData: accessed-variable=rSR_FRTT_Status.FRTT_StatusData
              DRA_rSR_FastGaugeInfo_FastGaugeInfoData: accessed-variable=rSR_FastGaugeInfo.FastGaugeInfoData
              DRP_rSR_HealthDumpGetData_HealthDumpGetDataData: accessed-variable=rSR_HealthDumpGetData.HealthDumpGetDataData
              DRP_rSR_HealthDumpGetHdr_HealthDumpGetHdrData: accessed-variable=rSR_HealthDumpGetHdr.HealthDumpGetHdrData
              DRA_rSR_HudWarningDisplay_HudWarningDisplayData: accessed-variable=rSR_HudWarningDisplay.HudWarningDisplayData
              DRP_rSR_IgnState_IgnStateData: accessed-variable=rSR_IgnState.IgnStateData
              DRA_rSR_IlluminationData_IlluminationDataData: accessed-variable=rSR_IlluminationData.IlluminationDataData
              DRA_rSR_PowerSystemStateReqChange_PowerSystemStateReqChangeData: accessed-variable=rSR_PowerSystemStateReqChange.PowerSystemStateReqChangeData
              DRA_rSR_RTT_Icon_RTT_IconData: accessed-variable=rSR_RTT_Icon.RTT_IconData
              DRA_rSR_RTT_Status_RTT_StatusData: accessed-variable=rSR_RTT_Status.RTT_StatusData
              DRA_rSR_RTT_Toggle_RTT_ToggleData: accessed-variable=rSR_RTT_Toggle.RTT_ToggleData
              DRA_rSR_ShiftPosIndStatus_ShiftPosIndStatusData: accessed-variable=rSR_ShiftPosIndStatus.ShiftPosIndStatusData
              DRA_rSR_SlowGaugeInfo_SlowGaugeInfoData: accessed-variable=rSR_SlowGaugeInfo.SlowGaugeInfoData
              DRA_rSR_TT_Status_TT_StatusData: accessed-variable=rSR_TT_Status.TT_StatusData
              DRA_rSR_TpmsWarningData_TpmsWarningDataData: accessed-variable=rSR_TpmsWarningData.TpmsWarningDataData
              DRA_rSR_UpdateLongServiceReq_UpdateLongServiceReqData: accessed-variable=rSR_UpdateLongServiceReq.UpdateLongServiceReqData
              DRA_rSR_UpdateShortServiceReq_UpdateShortServiceReqData: accessed-variable=rSR_UpdateShortServiceReq.UpdateShortServiceReqData
              DRA_rSR_WarningDisplay_WarningDisplayData: accessed-variable=rSR_WarningDisplay.WarningDisplayData
              DRA_rSR_WarningExtDisplay_WarningExtDisplayData: accessed-variable=rSR_WarningExtDisplay.WarningExtDisplayData
          data-send-points:
            16 x access:
              DWA_pSR_DisplayCurrentState_DisplayCurrentStateData: accessed-variable=pSR_DisplayCurrentState.DisplayCurrentStateData
              DWA_pSR_EmmcErrorNotifier_EmmcErrorNotifierData: accessed-variable=pSR_EmmcErrorNotifier.EmmcErrorNotifierData
              DSP_pSR_HealthDomainFatalError_HealthDomainFatalErrorData: accessed-variable=pSR_HealthDomainFatalError.HealthDomainFatalErrorData
              DSP_pSR_HealthDomainHeartbeat_HealthDomainHeartbeatData: accessed-variable=pSR_HealthDomainHeartbeat.HealthDomainHeartbeatData
              DSP_pSR_HealthDumpData_HealthDumpDataData: accessed-variable=pSR_HealthDumpData.HealthDumpDataData
              DSP_pSR_HealthDumpHdrInfo_HealthDumpHdrInfoData: accessed-variable=pSR_HealthDumpHdrInfo.HealthDumpHdrInfoData
              DSP_pSR_HealthEventRecord_HealthEventRecordData: accessed-variable=pSR_HealthEventRecord.HealthEventRecordData
              DWA_pSR_HudWarningStatus_HudWarningStatusData: accessed-variable=pSR_HudWarningStatus.HudWarningStatusData
              DSP_pSR_MainHMIReadyStatus_MainHMIReadyStatusData: accessed-variable=pSR_MainHMIReadyStatus.MainHMIReadyStatusData
              DSP_pSR_PowerExtendShutdownTime_PowerExtendShutdownTimeData: accessed-variable=pSR_PowerExtendShutdownTime.PowerExtendShutdownTimeData
              DSP_pSR_PowerKeepSystemAwake_PowerKeepSystemAwakeData: accessed-variable=pSR_PowerKeepSystemAwake.PowerKeepSystemAwakeData
              DWA_pSR_PowerSystemState_PowerSystemStateData: accessed-variable=pSR_PowerSystemState.PowerSystemStateData
              DSP_pSR_SafeHMIReadyStatus_SafeHMIReadyStatusData: accessed-variable=pSR_SafeHMIReadyStatus.SafeHMIReadyStatusData
              DWA_pSR_UpdateShortServiceResp_UpdateShortServiceRespData: accessed-variable=pSR_UpdateShortServiceResp.UpdateShortServiceRespData
              DWA_pSR_WarningDisplayAvailable_WarningDisplayAvailableData: accessed-variable=pSR_WarningDisplayAvailable.WarningDisplayAvailableData
              DWA_pSR_WarningStatus_WarningStatusData: accessed-variable=pSR_WarningStatus.WarningStatusData
          sync call OA_rCS_UclSystemCallbacks_ErrorNotification: operation=rCS_UclSystemCallbacks.ErrorNotification, timeout=0.0
          sync call OA_rCS_UclSystemCallbacks_LinkStatusChanged: operation=rCS_UclSystemCallbacks.LinkStatusChanged, timeout=0.0
        OnDre_UpdateLongServiceReq
          data-receive-point-by-arguments:
            23 x access:
              DRP_rSR_DiagDIDRequest_DiagDIDRequestData: accessed-variable=rSR_DiagDIDRequest.DiagDIDRequestData
              DRP_rSR_DiagIOCtrlRequest_DiagIOCtrlRequestData: accessed-variable=rSR_DiagIOCtrlRequest.DiagIOCtrlRequestData
              DRP_rSR_DiagRoutineRequest_DiagRoutineRequestData: accessed-variable=rSR_DiagRoutineRequest.DiagRoutineRequestData
              DRA_rSR_DisplaySetPower_DisplaySetPowerData: accessed-variable=rSR_DisplaySetPower.DisplaySetPowerData
              DRA_rSR_FRTT_Status_FRTT_StatusData: accessed-variable=rSR_FRTT_Status.FRTT_StatusData
              DRA_rSR_FastGaugeInfo_FastGaugeInfoData: accessed-variable=rSR_FastGaugeInfo.FastGaugeInfoData
              DRP_rSR_HealthDumpGetData_HealthDumpGetDataData: accessed-variable=rSR_HealthDumpGetData.HealthDumpGetDataData
              DRP_rSR_HealthDumpGetHdr_HealthDumpGetHdrData: accessed-variable=rSR_HealthDumpGetHdr.HealthDumpGetHdrData
              DRA_rSR_HudWarningDisplay_HudWarningDisplayData: accessed-variable=rSR_HudWarningDisplay.HudWarningDisplayData
              DRP_rSR_IgnState_IgnStateData: accessed-variable=rSR_IgnState.IgnStateData
              DRA_rSR_IlluminationData_IlluminationDataData: accessed-variable=rSR_IlluminationData.IlluminationDataData
              DRA_rSR_PowerSystemStateReqChange_PowerSystemStateReqChangeData: accessed-variable=rSR_PowerSystemStateReqChange.PowerSystemStateReqChangeData
              DRA_rSR_RTT_Icon_RTT_IconData: accessed-variable=rSR_RTT_Icon.RTT_IconData
              DRA_rSR_RTT_Status_RTT_StatusData: accessed-variable=rSR_RTT_Status.RTT_StatusData
              DRA_rSR_RTT_Toggle_RTT_ToggleData: accessed-variable=rSR_RTT_Toggle.RTT_ToggleData
              DRA_rSR_ShiftPosIndStatus_ShiftPosIndStatusData: accessed-variable=rSR_ShiftPosIndStatus.ShiftPosIndStatusData
              DRA_rSR_SlowGaugeInfo_SlowGaugeInfoData: accessed-variable=rSR_SlowGaugeInfo.SlowGaugeInfoData
              DRA_rSR_TT_Status_TT_StatusData: accessed-variable=rSR_TT_Status.TT_StatusData
              DRA_rSR_TpmsWarningData_TpmsWarningDataData: accessed-variable=rSR_TpmsWarningData.TpmsWarningDataData
              DRA_rSR_UpdateLongServiceReq_UpdateLongServiceReqData: accessed-variable=rSR_UpdateLongServiceReq.UpdateLongServiceReqData
              DRA_rSR_UpdateShortServiceReq_UpdateShortServiceReqData: accessed-variable=rSR_UpdateShortServiceReq.UpdateShortServiceReqData
              DRA_rSR_WarningDisplay_WarningDisplayData: accessed-variable=rSR_WarningDisplay.WarningDisplayData
              DRA_rSR_WarningExtDisplay_WarningExtDisplayData: accessed-variable=rSR_WarningExtDisplay.WarningExtDisplayData
          data-send-points:
            16 x access:
              DWA_pSR_DisplayCurrentState_DisplayCurrentStateData: accessed-variable=pSR_DisplayCurrentState.DisplayCurrentStateData
              DWA_pSR_EmmcErrorNotifier_EmmcErrorNotifierData: accessed-variable=pSR_EmmcErrorNotifier.EmmcErrorNotifierData
              DSP_pSR_HealthDomainFatalError_HealthDomainFatalErrorData: accessed-variable=pSR_HealthDomainFatalError.HealthDomainFatalErrorData
              DSP_pSR_HealthDomainHeartbeat_HealthDomainHeartbeatData: accessed-variable=pSR_HealthDomainHeartbeat.HealthDomainHeartbeatData
              DSP_pSR_HealthDumpData_HealthDumpDataData: accessed-variable=pSR_HealthDumpData.HealthDumpDataData
              DSP_pSR_HealthDumpHdrInfo_HealthDumpHdrInfoData: accessed-variable=pSR_HealthDumpHdrInfo.HealthDumpHdrInfoData
              DSP_pSR_HealthEventRecord_HealthEventRecordData: accessed-variable=pSR_HealthEventRecord.HealthEventRecordData
              DWA_pSR_HudWarningStatus_HudWarningStatusData: accessed-variable=pSR_HudWarningStatus.HudWarningStatusData
              DSP_pSR_MainHMIReadyStatus_MainHMIReadyStatusData: accessed-variable=pSR_MainHMIReadyStatus.MainHMIReadyStatusData
              DSP_pSR_PowerExtendShutdownTime_PowerExtendShutdownTimeData: accessed-variable=pSR_PowerExtendShutdownTime.PowerExtendShutdownTimeData
              DSP_pSR_PowerKeepSystemAwake_PowerKeepSystemAwakeData: accessed-variable=pSR_PowerKeepSystemAwake.PowerKeepSystemAwakeData
              DWA_pSR_PowerSystemState_PowerSystemStateData: accessed-variable=pSR_PowerSystemState.PowerSystemStateData
              DSP_pSR_SafeHMIReadyStatus_SafeHMIReadyStatusData: accessed-variable=pSR_SafeHMIReadyStatus.SafeHMIReadyStatusData
              DWA_pSR_UpdateShortServiceResp_UpdateShortServiceRespData: accessed-variable=pSR_UpdateShortServiceResp.UpdateShortServiceRespData
              DWA_pSR_WarningDisplayAvailable_WarningDisplayAvailableData: accessed-variable=pSR_WarningDisplayAvailable.WarningDisplayAvailableData
              DWA_pSR_WarningStatus_WarningStatusData: accessed-variable=pSR_WarningStatus.WarningStatusData
          sync call OA_rCS_UclSystemCallbacks_ErrorNotification: operation=rCS_UclSystemCallbacks.ErrorNotification, timeout=0.0
          sync call OA_rCS_UclSystemCallbacks_LinkStatusChanged: operation=rCS_UclSystemCallbacks.LinkStatusChanged, timeout=0.0
        OnDre_UpdateShortServiceReq
          data-receive-point-by-arguments:
            23 x access:
              DRP_rSR_DiagDIDRequest_DiagDIDRequestData: accessed-variable=rSR_DiagDIDRequest.DiagDIDRequestData
              DRP_rSR_DiagIOCtrlRequest_DiagIOCtrlRequestData: accessed-variable=rSR_DiagIOCtrlRequest.DiagIOCtrlRequestData
              DRP_rSR_DiagRoutineRequest_DiagRoutineRequestData: accessed-variable=rSR_DiagRoutineRequest.DiagRoutineRequestData
              DRA_rSR_DisplaySetPower_DisplaySetPowerData: accessed-variable=rSR_DisplaySetPower.DisplaySetPowerData
              DRA_rSR_FRTT_Status_FRTT_StatusData: accessed-variable=rSR_FRTT_Status.FRTT_StatusData
              DRA_rSR_FastGaugeInfo_FastGaugeInfoData: accessed-variable=rSR_FastGaugeInfo.FastGaugeInfoData
              DRP_rSR_HealthDumpGetData_HealthDumpGetDataData: accessed-variable=rSR_HealthDumpGetData.HealthDumpGetDataData
              DRP_rSR_HealthDumpGetHdr_HealthDumpGetHdrData: accessed-variable=rSR_HealthDumpGetHdr.HealthDumpGetHdrData
              DRA_rSR_HudWarningDisplay_HudWarningDisplayData: accessed-variable=rSR_HudWarningDisplay.HudWarningDisplayData
              DRP_rSR_IgnState_IgnStateData: accessed-variable=rSR_IgnState.IgnStateData
              DRA_rSR_IlluminationData_IlluminationDataData: accessed-variable=rSR_IlluminationData.IlluminationDataData
              DRA_rSR_PowerSystemStateReqChange_PowerSystemStateReqChangeData: accessed-variable=rSR_PowerSystemStateReqChange.PowerSystemStateReqChangeData
              DRA_rSR_RTT_Icon_RTT_IconData: accessed-variable=rSR_RTT_Icon.RTT_IconData
              DRA_rSR_RTT_Status_RTT_StatusData: accessed-variable=rSR_RTT_Status.RTT_StatusData
              DRA_rSR_RTT_Toggle_RTT_ToggleData: accessed-variable=rSR_RTT_Toggle.RTT_ToggleData
              DRA_rSR_ShiftPosIndStatus_ShiftPosIndStatusData: accessed-variable=rSR_ShiftPosIndStatus.ShiftPosIndStatusData
              DRA_rSR_SlowGaugeInfo_SlowGaugeInfoData: accessed-variable=rSR_SlowGaugeInfo.SlowGaugeInfoData
              DRA_rSR_TT_Status_TT_StatusData: accessed-variable=rSR_TT_Status.TT_StatusData
              DRA_rSR_TpmsWarningData_TpmsWarningDataData: accessed-variable=rSR_TpmsWarningData.TpmsWarningDataData
              DRA_rSR_UpdateLongServiceReq_UpdateLongServiceReqData: accessed-variable=rSR_UpdateLongServiceReq.UpdateLongServiceReqData
              DRA_rSR_UpdateShortServiceReq_UpdateShortServiceReqData: accessed-variable=rSR_UpdateShortServiceReq.UpdateShortServiceReqData
              DRA_rSR_WarningDisplay_WarningDisplayData: accessed-variable=rSR_WarningDisplay.WarningDisplayData
              DRA_rSR_WarningExtDisplay_WarningExtDisplayData: accessed-variable=rSR_WarningExtDisplay.WarningExtDisplayData
          data-send-points:
            16 x access:
              DWA_pSR_DisplayCurrentState_DisplayCurrentStateData: accessed-variable=pSR_DisplayCurrentState.DisplayCurrentStateData
              DWA_pSR_EmmcErrorNotifier_EmmcErrorNotifierData: accessed-variable=pSR_EmmcErrorNotifier.EmmcErrorNotifierData
              DSP_pSR_HealthDomainFatalError_HealthDomainFatalErrorData: accessed-variable=pSR_HealthDomainFatalError.HealthDomainFatalErrorData
              DSP_pSR_HealthDomainHeartbeat_HealthDomainHeartbeatData: accessed-variable=pSR_HealthDomainHeartbeat.HealthDomainHeartbeatData
              DSP_pSR_HealthDumpData_HealthDumpDataData: accessed-variable=pSR_HealthDumpData.HealthDumpDataData
              DSP_pSR_HealthDumpHdrInfo_HealthDumpHdrInfoData: accessed-variable=pSR_HealthDumpHdrInfo.HealthDumpHdrInfoData
              DSP_pSR_HealthEventRecord_HealthEventRecordData: accessed-variable=pSR_HealthEventRecord.HealthEventRecordData
              DWA_pSR_HudWarningStatus_HudWarningStatusData: accessed-variable=pSR_HudWarningStatus.HudWarningStatusData
              DSP_pSR_MainHMIReadyStatus_MainHMIReadyStatusData: accessed-variable=pSR_MainHMIReadyStatus.MainHMIReadyStatusData
              DSP_pSR_PowerExtendShutdownTime_PowerExtendShutdownTimeData: accessed-variable=pSR_PowerExtendShutdownTime.PowerExtendShutdownTimeData
              DSP_pSR_PowerKeepSystemAwake_PowerKeepSystemAwakeData: accessed-variable=pSR_PowerKeepSystemAwake.PowerKeepSystemAwakeData
              DWA_pSR_PowerSystemState_PowerSystemStateData: accessed-variable=pSR_PowerSystemState.PowerSystemStateData
              DSP_pSR_SafeHMIReadyStatus_SafeHMIReadyStatusData: accessed-variable=pSR_SafeHMIReadyStatus.SafeHMIReadyStatusData
              DWA_pSR_UpdateShortServiceResp_UpdateShortServiceRespData: accessed-variable=pSR_UpdateShortServiceResp.UpdateShortServiceRespData
              DWA_pSR_WarningDisplayAvailable_WarningDisplayAvailableData: accessed-variable=pSR_WarningDisplayAvailable.WarningDisplayAvailableData
              DWA_pSR_WarningStatus_WarningStatusData: accessed-variable=pSR_WarningStatus.WarningStatusData
          sync call OA_rCS_UclSystemCallbacks_ErrorNotification: operation=rCS_UclSystemCallbacks.ErrorNotification, timeout=0.0
          sync call OA_rCS_UclSystemCallbacks_LinkStatusChanged: operation=rCS_UclSystemCallbacks.LinkStatusChanged, timeout=0.0
        OnDre_WarningDisplay
          data-receive-point-by-arguments:
            23 x access:
              DRP_rSR_DiagDIDRequest_DiagDIDRequestData: accessed-variable=rSR_DiagDIDRequest.DiagDIDRequestData
              DRP_rSR_DiagIOCtrlRequest_DiagIOCtrlRequestData: accessed-variable=rSR_DiagIOCtrlRequest.DiagIOCtrlRequestData
              DRP_rSR_DiagRoutineRequest_DiagRoutineRequestData: accessed-variable=rSR_DiagRoutineRequest.DiagRoutineRequestData
              DRA_rSR_DisplaySetPower_DisplaySetPowerData: accessed-variable=rSR_DisplaySetPower.DisplaySetPowerData
              DRA_rSR_FRTT_Status_FRTT_StatusData: accessed-variable=rSR_FRTT_Status.FRTT_StatusData
              DRA_rSR_FastGaugeInfo_FastGaugeInfoData: accessed-variable=rSR_FastGaugeInfo.FastGaugeInfoData
              DRP_rSR_HealthDumpGetData_HealthDumpGetDataData: accessed-variable=rSR_HealthDumpGetData.HealthDumpGetDataData
              DRP_rSR_HealthDumpGetHdr_HealthDumpGetHdrData: accessed-variable=rSR_HealthDumpGetHdr.HealthDumpGetHdrData
              DRA_rSR_HudWarningDisplay_HudWarningDisplayData: accessed-variable=rSR_HudWarningDisplay.HudWarningDisplayData
              DRP_rSR_IgnState_IgnStateData: accessed-variable=rSR_IgnState.IgnStateData
              DRA_rSR_IlluminationData_IlluminationDataData: accessed-variable=rSR_IlluminationData.IlluminationDataData
              DRA_rSR_PowerSystemStateReqChange_PowerSystemStateReqChangeData: accessed-variable=rSR_PowerSystemStateReqChange.PowerSystemStateReqChangeData
              DRA_rSR_RTT_Icon_RTT_IconData: accessed-variable=rSR_RTT_Icon.RTT_IconData
              DRA_rSR_RTT_Status_RTT_StatusData: accessed-variable=rSR_RTT_Status.RTT_StatusData
              DRA_rSR_RTT_Toggle_RTT_ToggleData: accessed-variable=rSR_RTT_Toggle.RTT_ToggleData
              DRA_rSR_ShiftPosIndStatus_ShiftPosIndStatusData: accessed-variable=rSR_ShiftPosIndStatus.ShiftPosIndStatusData
              DRA_rSR_SlowGaugeInfo_SlowGaugeInfoData: accessed-variable=rSR_SlowGaugeInfo.SlowGaugeInfoData
              DRA_rSR_TT_Status_TT_StatusData: accessed-variable=rSR_TT_Status.TT_StatusData
              DRA_rSR_TpmsWarningData_TpmsWarningDataData: accessed-variable=rSR_TpmsWarningData.TpmsWarningDataData
              DRA_rSR_UpdateLongServiceReq_UpdateLongServiceReqData: accessed-variable=rSR_UpdateLongServiceReq.UpdateLongServiceReqData
              DRA_rSR_UpdateShortServiceReq_UpdateShortServiceReqData: accessed-variable=rSR_UpdateShortServiceReq.UpdateShortServiceReqData
              DRA_rSR_WarningDisplay_WarningDisplayData: accessed-variable=rSR_WarningDisplay.WarningDisplayData
              DRA_rSR_WarningExtDisplay_WarningExtDisplayData: accessed-variable=rSR_WarningExtDisplay.WarningExtDisplayData
          data-send-points:
            16 x access:
              DWA_pSR_DisplayCurrentState_DisplayCurrentStateData: accessed-variable=pSR_DisplayCurrentState.DisplayCurrentStateData
              DWA_pSR_EmmcErrorNotifier_EmmcErrorNotifierData: accessed-variable=pSR_EmmcErrorNotifier.EmmcErrorNotifierData
              DSP_pSR_HealthDomainFatalError_HealthDomainFatalErrorData: accessed-variable=pSR_HealthDomainFatalError.HealthDomainFatalErrorData
              DSP_pSR_HealthDomainHeartbeat_HealthDomainHeartbeatData: accessed-variable=pSR_HealthDomainHeartbeat.HealthDomainHeartbeatData
              DSP_pSR_HealthDumpData_HealthDumpDataData: accessed-variable=pSR_HealthDumpData.HealthDumpDataData
              DSP_pSR_HealthDumpHdrInfo_HealthDumpHdrInfoData: accessed-variable=pSR_HealthDumpHdrInfo.HealthDumpHdrInfoData
              DSP_pSR_HealthEventRecord_HealthEventRecordData: accessed-variable=pSR_HealthEventRecord.HealthEventRecordData
              DWA_pSR_HudWarningStatus_HudWarningStatusData: accessed-variable=pSR_HudWarningStatus.HudWarningStatusData
              DSP_pSR_MainHMIReadyStatus_MainHMIReadyStatusData: accessed-variable=pSR_MainHMIReadyStatus.MainHMIReadyStatusData
              DSP_pSR_PowerExtendShutdownTime_PowerExtendShutdownTimeData: accessed-variable=pSR_PowerExtendShutdownTime.PowerExtendShutdownTimeData
              DSP_pSR_PowerKeepSystemAwake_PowerKeepSystemAwakeData: accessed-variable=pSR_PowerKeepSystemAwake.PowerKeepSystemAwakeData
              DWA_pSR_PowerSystemState_PowerSystemStateData: accessed-variable=pSR_PowerSystemState.PowerSystemStateData
              DSP_pSR_SafeHMIReadyStatus_SafeHMIReadyStatusData: accessed-variable=pSR_SafeHMIReadyStatus.SafeHMIReadyStatusData
              DWA_pSR_UpdateShortServiceResp_UpdateShortServiceRespData: accessed-variable=pSR_UpdateShortServiceResp.UpdateShortServiceRespData
              DWA_pSR_WarningDisplayAvailable_WarningDisplayAvailableData: accessed-variable=pSR_WarningDisplayAvailable.WarningDisplayAvailableData
              DWA_pSR_WarningStatus_WarningStatusData: accessed-variable=pSR_WarningStatus.WarningStatusData
          sync call OA_rCS_UclSystemCallbacks_ErrorNotification: operation=rCS_UclSystemCallbacks.ErrorNotification, timeout=0.0
          sync call OA_rCS_UclSystemCallbacks_LinkStatusChanged: operation=rCS_UclSystemCallbacks.LinkStatusChanged, timeout=0.0
        OnDre_WarningExtDisplay
          data-receive-point-by-arguments:
            23 x access:
              DRP_rSR_DiagDIDRequest_DiagDIDRequestData: accessed-variable=rSR_DiagDIDRequest.DiagDIDRequestData
              DRP_rSR_DiagIOCtrlRequest_DiagIOCtrlRequestData: accessed-variable=rSR_DiagIOCtrlRequest.DiagIOCtrlRequestData
              DRP_rSR_DiagRoutineRequest_DiagRoutineRequestData: accessed-variable=rSR_DiagRoutineRequest.DiagRoutineRequestData
              DRA_rSR_DisplaySetPower_DisplaySetPowerData: accessed-variable=rSR_DisplaySetPower.DisplaySetPowerData
              DRA_rSR_FRTT_Status_FRTT_StatusData: accessed-variable=rSR_FRTT_Status.FRTT_StatusData
              DRA_rSR_FastGaugeInfo_FastGaugeInfoData: accessed-variable=rSR_FastGaugeInfo.FastGaugeInfoData
              DRP_rSR_HealthDumpGetData_HealthDumpGetDataData: accessed-variable=rSR_HealthDumpGetData.HealthDumpGetDataData
              DRP_rSR_HealthDumpGetHdr_HealthDumpGetHdrData: accessed-variable=rSR_HealthDumpGetHdr.HealthDumpGetHdrData
              DRA_rSR_HudWarningDisplay_HudWarningDisplayData: accessed-variable=rSR_HudWarningDisplay.HudWarningDisplayData
              DRP_rSR_IgnState_IgnStateData: accessed-variable=rSR_IgnState.IgnStateData
              DRA_rSR_IlluminationData_IlluminationDataData: accessed-variable=rSR_IlluminationData.IlluminationDataData
              DRA_rSR_PowerSystemStateReqChange_PowerSystemStateReqChangeData: accessed-variable=rSR_PowerSystemStateReqChange.PowerSystemStateReqChangeData
              DRA_rSR_RTT_Icon_RTT_IconData: accessed-variable=rSR_RTT_Icon.RTT_IconData
              DRA_rSR_RTT_Status_RTT_StatusData: accessed-variable=rSR_RTT_Status.RTT_StatusData
              DRA_rSR_RTT_Toggle_RTT_ToggleData: accessed-variable=rSR_RTT_Toggle.RTT_ToggleData
              DRA_rSR_ShiftPosIndStatus_ShiftPosIndStatusData: accessed-variable=rSR_ShiftPosIndStatus.ShiftPosIndStatusData
              DRA_rSR_SlowGaugeInfo_SlowGaugeInfoData: accessed-variable=rSR_SlowGaugeInfo.SlowGaugeInfoData
              DRA_rSR_TT_Status_TT_StatusData: accessed-variable=rSR_TT_Status.TT_StatusData
              DRA_rSR_TpmsWarningData_TpmsWarningDataData: accessed-variable=rSR_TpmsWarningData.TpmsWarningDataData
              DRA_rSR_UpdateLongServiceReq_UpdateLongServiceReqData: accessed-variable=rSR_UpdateLongServiceReq.UpdateLongServiceReqData
              DRA_rSR_UpdateShortServiceReq_UpdateShortServiceReqData: accessed-variable=rSR_UpdateShortServiceReq.UpdateShortServiceReqData
              DRA_rSR_WarningDisplay_WarningDisplayData: accessed-variable=rSR_WarningDisplay.WarningDisplayData
              DRA_rSR_WarningExtDisplay_WarningExtDisplayData: accessed-variable=rSR_WarningExtDisplay.WarningExtDisplayData
          data-send-points:
            16 x access:
              DWA_pSR_DisplayCurrentState_DisplayCurrentStateData: accessed-variable=pSR_DisplayCurrentState.DisplayCurrentStateData
              DWA_pSR_EmmcErrorNotifier_EmmcErrorNotifierData: accessed-variable=pSR_EmmcErrorNotifier.EmmcErrorNotifierData
              DSP_pSR_HealthDomainFatalError_HealthDomainFatalErrorData: accessed-variable=pSR_HealthDomainFatalError.HealthDomainFatalErrorData
              DSP_pSR_HealthDomainHeartbeat_HealthDomainHeartbeatData: accessed-variable=pSR_HealthDomainHeartbeat.HealthDomainHeartbeatData
              DSP_pSR_HealthDumpData_HealthDumpDataData: accessed-variable=pSR_HealthDumpData.HealthDumpDataData
              DSP_pSR_HealthDumpHdrInfo_HealthDumpHdrInfoData: accessed-variable=pSR_HealthDumpHdrInfo.HealthDumpHdrInfoData
              DSP_pSR_HealthEventRecord_HealthEventRecordData: accessed-variable=pSR_HealthEventRecord.HealthEventRecordData
              DWA_pSR_HudWarningStatus_HudWarningStatusData: accessed-variable=pSR_HudWarningStatus.HudWarningStatusData
              DSP_pSR_MainHMIReadyStatus_MainHMIReadyStatusData: accessed-variable=pSR_MainHMIReadyStatus.MainHMIReadyStatusData
              DSP_pSR_PowerExtendShutdownTime_PowerExtendShutdownTimeData: accessed-variable=pSR_PowerExtendShutdownTime.PowerExtendShutdownTimeData
              DSP_pSR_PowerKeepSystemAwake_PowerKeepSystemAwakeData: accessed-variable=pSR_PowerKeepSystemAwake.PowerKeepSystemAwakeData
              DWA_pSR_PowerSystemState_PowerSystemStateData: accessed-variable=pSR_PowerSystemState.PowerSystemStateData
              DSP_pSR_SafeHMIReadyStatus_SafeHMIReadyStatusData: accessed-variable=pSR_SafeHMIReadyStatus.SafeHMIReadyStatusData
              DWA_pSR_UpdateShortServiceResp_UpdateShortServiceRespData: accessed-variable=pSR_UpdateShortServiceResp.UpdateShortServiceRespData
              DWA_pSR_WarningDisplayAvailable_WarningDisplayAvailableData: accessed-variable=pSR_WarningDisplayAvailable.WarningDisplayAvailableData
              DWA_pSR_WarningStatus_WarningStatusData: accessed-variable=pSR_WarningStatus.WarningStatusData
          sync call OA_rCS_UclSystemCallbacks_ErrorNotification: operation=rCS_UclSystemCallbacks.ErrorNotification, timeout=0.0
          sync call OA_rCS_UclSystemCallbacks_LinkStatusChanged: operation=rCS_UclSystemCallbacks.LinkStatusChanged, timeout=0.0
  24 x constant specification:
    UclProxyCddDisplayCurrentStateDataValue0: value-spec={short-label=UclProxyCddDisplayCurrentStateDataValue0, fields=[UclProxyCddDisplayCurrentStateDataValue_0:0, UclProxyCddDisplayCurrentStateDataValue_1:0]}
    UclProxyCddEmmcErrorNotifierDataValue0: value-spec={short-label=UclProxyCddEmmcErrorNotifierDataValue0, fields=UclProxyCddEmmcErrorNotifierDataValue_0:0}
    UclProxyCddHudWarningStatusDataValue0: value-spec={short-label=UclProxyCddHudWarningStatusDataValue0, fields=[UclProxyCddHudWarningStatusDataValue_0:0, UclProxyCddHudWarningStatusDataValue_1:0, UclProxyCddHudWarningStatusDataValue_2:[UclProxyCdddynData0Value:0, UclProxyCdddynData1Value:0, UclProxyCdddynData2Value:0, UclProxyCdddynData3Value:0, UclProxyCdddynData4Value:0, UclProxyCdddynData5Value:0, UclProxyCdddynData6Value:0, UclProxyCdddynData7Value:0, UclProxyCdddynData8Value:0, UclProxyCdddynData9Value:0]]}
    UclProxyCddPowerSystemStateDataValue0: value-spec={short-label=UclProxyCddPowerSystemStateDataValue0, fields=[UclProxyCddPowerSystemStateDataValue_0:0, UclProxyCddPowerSystemStateDataValue_1:0]}
    UclProxyCddUpdateShortServiceRespDataValue0: value-spec={short-label=UclProxyCddUpdateShortServiceRespDataValue0, fields=[UclProxyCddUpdateShortServiceRespDataValue_0:0, UclProxyCddUpdateShortServiceRespDataValue_1:0, UclProxyCddUpdateShortServiceRespDataValue_2:0, UclProxyCddUpdateShortServiceRespDataValue_3:0, UclProxyCddUpdateShortServiceRespDataValue_4:0, UclProxyCddUpdateShortServiceRespDataValue_5:0, UclProxyCddUpdateShortServiceRespDataValue_6:[UclProxyCdddata0Value:0, UclProxyCdddata1Value:0, UclProxyCdddata2Value:0, UclProxyCdddata3Value:0, UclProxyCdddata4Value:0, UclProxyCdddata5Value:0, UclProxyCdddata6Value:0, UclProxyCdddata7Value:0, UclProxyCdddata8Value:0, UclProxyCdddata9Value:0, UclProxyCdddata10Value:0, UclProxyCdddata11Value:0, UclProxyCdddata12Value:0, UclProxyCdddata13Value:0, UclProxyCdddata14Value:0, UclProxyCdddata15Value:0, UclProxyCdddata16Value:0, UclProxyCdddata17Value:0, UclProxyCdddata18Value:0, UclProxyCdddata19Value:0, UclProxyCdddata20Value:0, UclProxyCdddata21Value:0, UclProxyCdddata22Value:0, UclProxyCdddata23Value:0, UclProxyCdddata24Value:0, UclProxyCdddata25Value:0, UclProxyCdddata26Value:0, UclProxyCdddata27Value:0, UclProxyCdddata28Value:0, UclProxyCdddata29Value:0, UclProxyCdddata30Value:0, UclProxyCdddata31Value:0, UclProxyCdddata32Value:0, UclProxyCdddata33Value:0, UclProxyCdddata34Value:0, UclProxyCdddata35Value:0, UclProxyCdddata36Value:0, UclProxyCdddata37Value:0, UclProxyCdddata38Value:0, UclProxyCdddata39Value:0, UclProxyCdddata40Value:0, UclProxyCdddata41Value:0, UclProxyCdddata42Value:0, UclProxyCdddata43Value:0, UclProxyCdddata44Value:0, UclProxyCdddata45Value:0, UclProxyCdddata46Value:0, UclProxyCdddata47Value:0, UclProxyCdddata48Value:0, UclProxyCdddata49Value:0, UclProxyCdddata50Value:0, UclProxyCdddata51Value:0, UclProxyCdddata52Value:0, UclProxyCdddata53Value:0, UclProxyCdddata54Value:0, UclProxyCdddata55Value:0, UclProxyCdddata56Value:0, UclProxyCdddata57Value:0, UclProxyCdddata58Value:0, UclProxyCdddata59Value:0, UclProxyCdddata60Value:0, UclProxyCdddata61Value:0, UclProxyCdddata62Value:0, UclProxyCdddata63Value:0]]}
    UclProxyCddWarningDisplayAvailableDataValue0: value-spec={short-label=UclProxyCddWarningDisplayAvailableDataValue0, fields=UclProxyCddWarningDisplayAvailableDataValue_0:0}
    UclProxyCddWarningStatusDataValue0: value-spec={short-label=UclProxyCddWarningStatusDataValue0, fields=[UclProxyCddWarningStatusDataValue_0:0, UclProxyCddWarningStatusDataValue_1:0, UclProxyCddWarningStatusDataValue_2:[UclProxyCdddynData0Value:0, UclProxyCdddynData1Value:0, UclProxyCdddynData2Value:0, UclProxyCdddynData3Value:0, UclProxyCdddynData4Value:0, UclProxyCdddynData5Value:0, UclProxyCdddynData6Value:0, UclProxyCdddynData7Value:0, UclProxyCdddynData8Value:0, UclProxyCdddynData9Value:0]]}
    UclProxyCddDisplaySetPowerDataValue0: value-spec={short-label=UclProxyCddDisplaySetPowerDataValue0, fields=[UclProxyCddDisplaySetPowerDataValue_0:0, UclProxyCddDisplaySetPowerDataValue_1:0]}
    UclProxyCddFRTT_StatusDataValue0: value-spec={short-label=UclProxyCddFRTT_StatusDataValue0, fields=UclProxyCddFRTT_StatusDataValue_0:[UclProxyCddmask0Value:0, UclProxyCddmask1Value:0]}
    UclProxyCddFastGaugeInfoDataValue0: value-spec={short-label=UclProxyCddFastGaugeInfoDataValue0, fields={short-label=UclProxyCddFastGaugeInfoDataValue_0, fields=[UclProxyCddgaugeInfo_4Value_0:0, UclProxyCddgaugeInfo_4Value_1:0, UclProxyCddgaugeInfo_4Value_2:0, UclProxyCddgaugeInfo_4Value_3:0, UclProxyCddgaugeInfo_4Value_4:0]}}
    UclProxyCddHudWarningDisplayDataValue0: value-spec={short-label=UclProxyCddHudWarningDisplayDataValue0, fields=[UclProxyCddHudWarningDisplayDataValue_0:0, UclProxyCddHudWarningDisplayDataValue_1:0, UclProxyCddHudWarningDisplayDataValue_2:[UclProxyCdddynData0Value:0, UclProxyCdddynData1Value:0, UclProxyCdddynData2Value:0, UclProxyCdddynData3Value:0, UclProxyCdddynData4Value:0, UclProxyCdddynData5Value:0, UclProxyCdddynData6Value:0, UclProxyCdddynData7Value:0]]}
    UclProxyCddIlluminationDataDataValue0: value-spec={short-label=UclProxyCddIlluminationDataDataValue0, fields=[UclProxyCddIlluminationDataDataValue_0:0, UclProxyCddIlluminationDataDataValue_1:0, UclProxyCddIlluminationDataDataValue_2:0, UclProxyCddIlluminationDataDataValue_3:0]}
    UclProxyCddPowerSystemStateReqChangeDataValue0: value-spec={short-label=UclProxyCddPowerSystemStateReqChangeDataValue0, fields=[UclProxyCddPowerSystemStateReqChangeDataValue_0:0, UclProxyCddPowerSystemStateReqChangeDataValue_1:0]}
    UclProxyCddRTT_IconDataValue0: value-spec={short-label=UclProxyCddRTT_IconDataValue0, fields=UclProxyCddRTT_IconDataValue_0:[UclProxyCddicon0Value:0, UclProxyCddicon1Value:0]}
    UclProxyCddRTT_StatusDataValue0: value-spec={short-label=UclProxyCddRTT_StatusDataValue0, fields=UclProxyCddRTT_StatusDataValue_0:[UclProxyCddmask0Value:0, UclProxyCddmask1Value:0]}
    UclProxyCddRTT_ToggleDataValue0: value-spec={short-label=UclProxyCddRTT_ToggleDataValue0, fields=[UclProxyCddRTT_ToggleDataValue_0:0, UclProxyCddRTT_ToggleDataValue_1:0]}
    UclProxyCddShiftPosIndStatusDataValue0: value-spec={short-label=UclProxyCddShiftPosIndStatusDataValue0, fields={short-label=UclProxyCddShiftPosIndStatusDataValue_0, fields=[UclProxyCddstatusValue_0:0, UclProxyCddstatusValue_1:0, UclProxyCddstatusValue_2:0, UclProxyCddstatusValue_3:0, UclProxyCddstatusValue_4:0, UclProxyCddstatusValue_5:0]}}
    UclProxyCddSlowGaugeInfoDataValue0: value-spec={short-label=UclProxyCddSlowGaugeInfoDataValue0, fields={short-label=UclProxyCddSlowGaugeInfoDataValue_0, fields=[UclProxyCddgaugeInfoValue_0:0, UclProxyCddgaugeInfoValue_1:0, UclProxyCddgaugeInfoValue_2:0, UclProxyCddgaugeInfoValue_3:0, UclProxyCddgaugeInfoValue_4:0]}}
    UclProxyCddTT_StatusDataValue0: value-spec={short-label=UclProxyCddTT_StatusDataValue0, fields=UclProxyCddTT_StatusDataValue_0:[UclProxyCddmask0Value:0, UclProxyCddmask1Value:0, UclProxyCddmask2Value:0, UclProxyCddmask3Value:0, UclProxyCddmask4Value:0, UclProxyCddmask5Value:0, UclProxyCddmask6Value:0, UclProxyCddmask7Value:0, UclProxyCddmask8Value:0, UclProxyCddmask9Value:0, UclProxyCddmask10Value:0, UclProxyCddmask11Value:0, UclProxyCddmask12Value:0, UclProxyCddmask13Value:0, UclProxyCddmask14Value:0]}
    UclProxyCddTpmsWarningDataDataValue0: value-spec={short-label=UclProxyCddTpmsWarningDataDataValue0, fields=UclProxyCddTpmsWarningDataDataValue_0:[UclProxyCddtpmsWarndata0Value:0, UclProxyCddtpmsWarndata1Value:0, UclProxyCddtpmsWarndata2Value:0, UclProxyCddtpmsWarndata3Value:0, UclProxyCddtpmsWarndata4Value:0]}
    UclProxyCddUpdateLongServiceReqDataValue0: value-spec={short-label=UclProxyCddUpdateLongServiceReqDataValue0, fields=[UclProxyCddUpdateLongServiceReqDataValue_0:0, UclProxyCddUpdateLongServiceReqDataValue_1:0, UclProxyCddUpdateLongServiceReqDataValue_2:0, UclProxyCddUpdateLongServiceReqDataValue_3:0, UclProxyCddUpdateLongServiceReqDataValue_4:0, UclProxyCddUpdateLongServiceReqDataValue_5:0, UclProxyCddUpdateLongServiceReqDataValue_6:[UclProxyCdddata0Value:0, UclProxyCdddata1Value:0, UclProxyCdddata2Value:0, UclProxyCdddata3Value:0, UclProxyCdddata4Value:0, UclProxyCdddata5Value:0, UclProxyCdddata6Value:0, UclProxyCdddata7Value:0, UclProxyCdddata8Value:0, UclProxyCdddata9Value:0, UclProxyCdddata10Value:0, UclProxyCdddata11Value:0, UclProxyCdddata12Value:0, UclProxyCdddata13Value:0, UclProxyCdddata14Value:0, UclProxyCdddata15Value:0, UclProxyCdddata16Value:0, UclProxyCdddata17Value:0, UclProxyCdddata18Value:0, UclProxyCdddata19Value:0, UclProxyCdddata20Value:0, UclProxyCdddata21Value:0, UclProxyCdddata22Value:0, UclProxyCdddata23Value:0, UclProxyCdddata24Value:0, UclProxyCdddata25Value:0, UclProxyCdddata26Value:0, UclProxyCdddata27Value:0, UclProxyCdddata28Value:0, UclProxyCdddata29Value:0, UclProxyCdddata30Value:0, UclProxyCdddata31Value:0, UclProxyCdddata32Value:0, UclProxyCdddata33Value:0, UclProxyCdddata34Value:0, UclProxyCdddata35Value:0, UclProxyCdddata36Value:0, UclProxyCdddata37Value:0, UclProxyCdddata38Value:0, UclProxyCdddata39Value:0, UclProxyCdddata40Value:0, UclProxyCdddata41Value:0, UclProxyCdddata42Value:0, UclProxyCdddata43Value:0, UclProxyCdddata44Value:0, UclProxyCdddata45Value:0, UclProxyCdddata46Value:0, UclProxyCdddata47Value:0, UclProxyCdddata48Value:0, UclProxyCdddata49Value:0, UclProxyCdddata50Value:0, UclProxyCdddata51Value:0, UclProxyCdddata52Value:0, UclProxyCdddata53Value:0, UclProxyCdddata54Value:0, UclProxyCdddata55Value:0, UclProxyCdddata56Value:0, UclProxyCdddata57Value:0, UclProxyCdddata58Value:0, UclProxyCdddata59Value:0, UclProxyCdddata60Value:0, UclProxyCdddata61Value:0, UclProxyCdddata62Value:0, UclProxyCdddata63Value:0, UclProxyCdddata64Value:0, UclProxyCdddata65Value:0, UclProxyCdddata66Value:0, UclProxyCdddata67Value:0, UclProxyCdddata68Value:0, UclProxyCdddata69Value:0, UclProxyCdddata70Value:0, UclProxyCdddata71Value:0, UclProxyCdddata72Value:0, UclProxyCdddata73Value:0, UclProxyCdddata74Value:0, UclProxyCdddata75Value:0, UclProxyCdddata76Value:0, UclProxyCdddata77Value:0, UclProxyCdddata78Value:0, UclProxyCdddata79Value:0, UclProxyCdddata80Value:0, UclProxyCdddata81Value:0, UclProxyCdddata82Value:0, UclProxyCdddata83Value:0, UclProxyCdddata84Value:0, UclProxyCdddata85Value:0, UclProxyCdddata86Value:0, UclProxyCdddata87Value:0, UclProxyCdddata88Value:0, UclProxyCdddata89Value:0, UclProxyCdddata90Value:0, UclProxyCdddata91Value:0, UclProxyCdddata92Value:0, UclProxyCdddata93Value:0, UclProxyCdddata94Value:0, UclProxyCdddata95Value:0, UclProxyCdddata96Value:0, UclProxyCdddata97Value:0, UclProxyCdddata98Value:0, UclProxyCdddata99Value:0, UclProxyCdddata100Value:0, UclProxyCdddata101Value:0, UclProxyCdddata102Value:0, UclProxyCdddata103Value:0, UclProxyCdddata104Value:0, UclProxyCdddata105Value:0, UclProxyCdddata106Value:0, UclProxyCdddata107Value:0, UclProxyCdddata108Value:0, UclProxyCdddata109Value:0, UclProxyCdddata110Value:0, UclProxyCdddata111Value:0, UclProxyCdddata112Value:0, UclProxyCdddata113Value:0, UclProxyCdddata114Value:0, UclProxyCdddata115Value:0, UclProxyCdddata116Value:0, UclProxyCdddata117Value:0, UclProxyCdddata118Value:0, UclProxyCdddata119Value:0, UclProxyCdddata120Value:0, UclProxyCdddata121Value:0, UclProxyCdddata122Value:0, UclProxyCdddata123Value:0, UclProxyCdddata124Value:0, UclProxyCdddata125Value:0, UclProxyCdddata126Value:0, UclProxyCdddata127Value:0, UclProxyCdddata128Value:0, UclProxyCdddata129Value:0, UclProxyCdddata130Value:0, UclProxyCdddata131Value:0, UclProxyCdddata132Value:0, UclProxyCdddata133Value:0, UclProxyCdddata134Value:0, UclProxyCdddata135Value:0, UclProxyCdddata136Value:0, UclProxyCdddata137Value:0, UclProxyCdddata138Value:0, UclProxyCdddata139Value:0, UclProxyCdddata140Value:0, UclProxyCdddata141Value:0, UclProxyCdddata142Value:0, UclProxyCdddata143Value:0, UclProxyCdddata144Value:0, UclProxyCdddata145Value:0, UclProxyCdddata146Value:0, UclProxyCdddata147Value:0, UclProxyCdddata148Value:0, UclProxyCdddata149Value:0, UclProxyCdddata150Value:0, UclProxyCdddata151Value:0, UclProxyCdddata152Value:0, UclProxyCdddata153Value:0, UclProxyCdddata154Value:0, UclProxyCdddata155Value:0, UclProxyCdddata156Value:0, UclProxyCdddata157Value:0, UclProxyCdddata158Value:0, UclProxyCdddata159Value:0, UclProxyCdddata160Value:0, UclProxyCdddata161Value:0, UclProxyCdddata162Value:0, UclProxyCdddata163Value:0, UclProxyCdddata164Value:0, UclProxyCdddata165Value:0, UclProxyCdddata166Value:0, UclProxyCdddata167Value:0, UclProxyCdddata168Value:0, UclProxyCdddata169Value:0, UclProxyCdddata170Value:0, UclProxyCdddata171Value:0, UclProxyCdddata172Value:0, UclProxyCdddata173Value:0, UclProxyCdddata174Value:0, UclProxyCdddata175Value:0, UclProxyCdddata176Value:0, UclProxyCdddata177Value:0, UclProxyCdddata178Value:0, UclProxyCdddata179Value:0, UclProxyCdddata180Value:0, UclProxyCdddata181Value:0, UclProxyCdddata182Value:0, UclProxyCdddata183Value:0, UclProxyCdddata184Value:0, UclProxyCdddata185Value:0, UclProxyCdddata186Value:0, UclProxyCdddata187Value:0, UclProxyCdddata188Value:0, UclProxyCdddata189Value:0, UclProxyCdddata190Value:0, UclProxyCdddata191Value:0, UclProxyCdddata192Value:0, UclProxyCdddata193Value:0, UclProxyCdddata194Value:0, UclProxyCdddata195Value:0, UclProxyCdddata196Value:0, UclProxyCdddata197Value:0, UclProxyCdddata198Value:0, UclProxyCdddata199Value:0, UclProxyCdddata200Value:0, UclProxyCdddata201Value:0, UclProxyCdddata202Value:0, UclProxyCdddata203Value:0, UclProxyCdddata204Value:0, UclProxyCdddata205Value:0, UclProxyCdddata206Value:0, UclProxyCdddata207Value:0, UclProxyCdddata208Value:0, UclProxyCdddata209Value:0, UclProxyCdddata210Value:0, UclProxyCdddata211Value:0, UclProxyCdddata212Value:0, UclProxyCdddata213Value:0, UclProxyCdddata214Value:0, UclProxyCdddata215Value:0, UclProxyCdddata216Value:0, UclProxyCdddata217Value:0, UclProxyCdddata218Value:0, UclProxyCdddata219Value:0, UclProxyCdddata220Value:0, UclProxyCdddata221Value:0, UclProxyCdddata222Value:0, UclProxyCdddata223Value:0, UclProxyCdddata224Value:0, UclProxyCdddata225Value:0, UclProxyCdddata226Value:0, UclProxyCdddata227Value:0, UclProxyCdddata228Value:0, UclProxyCdddata229Value:0, UclProxyCdddata230Value:0, UclProxyCdddata231Value:0, UclProxyCdddata232Value:0, UclProxyCdddata233Value:0, UclProxyCdddata234Value:0, UclProxyCdddata235Value:0, UclProxyCdddata236Value:0, UclProxyCdddata237Value:0, UclProxyCdddata238Value:0, UclProxyCdddata239Value:0, UclProxyCdddata240Value:0, UclProxyCdddata241Value:0, UclProxyCdddata242Value:0, UclProxyCdddata243Value:0, UclProxyCdddata244Value:0, UclProxyCdddata245Value:0, UclProxyCdddata246Value:0, UclProxyCdddata247Value:0, UclProxyCdddata248Value:0, UclProxyCdddata249Value:0, UclProxyCdddata250Value:0, UclProxyCdddata251Value:0, UclProxyCdddata252Value:0, UclProxyCdddata253Value:0, UclProxyCdddata254Value:0, UclProxyCdddata255Value:0, UclProxyCdddata256Value:0, UclProxyCdddata257Value:0, UclProxyCdddata258Value:0, UclProxyCdddata259Value:0, UclProxyCdddata260Value:0, UclProxyCdddata261Value:0, UclProxyCdddata262Value:0, UclProxyCdddata263Value:0, UclProxyCdddata264Value:0, UclProxyCdddata265Value:0, UclProxyCdddata266Value:0, UclProxyCdddata267Value:0, UclProxyCdddata268Value:0, UclProxyCdddata269Value:0, UclProxyCdddata270Value:0, UclProxyCdddata271Value:0, UclProxyCdddata272Value:0, UclProxyCdddata273Value:0, UclProxyCdddata274Value:0, UclProxyCdddata275Value:0, UclProxyCdddata276Value:0, UclProxyCdddata277Value:0, UclProxyCdddata278Value:0, UclProxyCdddata279Value:0, UclProxyCdddata280Value:0, UclProxyCdddata281Value:0, UclProxyCdddata282Value:0, UclProxyCdddata283Value:0, UclProxyCdddata284Value:0, UclProxyCdddata285Value:0, UclProxyCdddata286Value:0, UclProxyCdddata287Value:0, UclProxyCdddata288Value:0, UclProxyCdddata289Value:0, UclProxyCdddata290Value:0, UclProxyCdddata291Value:0, UclProxyCdddata292Value:0, UclProxyCdddata293Value:0, UclProxyCdddata294Value:0, UclProxyCdddata295Value:0, UclProxyCdddata296Value:0, UclProxyCdddata297Value:0, UclProxyCdddata298Value:0, UclProxyCdddata299Value:0, UclProxyCdddata300Value:0, UclProxyCdddata301Value:0, UclProxyCdddata302Value:0, UclProxyCdddata303Value:0, UclProxyCdddata304Value:0, UclProxyCdddata305Value:0, UclProxyCdddata306Value:0, UclProxyCdddata307Value:0, UclProxyCdddata308Value:0, UclProxyCdddata309Value:0, UclProxyCdddata310Value:0, UclProxyCdddata311Value:0, UclProxyCdddata312Value:0, UclProxyCdddata313Value:0, UclProxyCdddata314Value:0, UclProxyCdddata315Value:0, UclProxyCdddata316Value:0, UclProxyCdddata317Value:0, UclProxyCdddata318Value:0, UclProxyCdddata319Value:0, UclProxyCdddata320Value:0, UclProxyCdddata321Value:0, UclProxyCdddata322Value:0, UclProxyCdddata323Value:0, UclProxyCdddata324Value:0, UclProxyCdddata325Value:0, UclProxyCdddata326Value:0, UclProxyCdddata327Value:0, UclProxyCdddata328Value:0, UclProxyCdddata329Value:0, UclProxyCdddata330Value:0, UclProxyCdddata331Value:0, UclProxyCdddata332Value:0, UclProxyCdddata333Value:0, UclProxyCdddata334Value:0, UclProxyCdddata335Value:0, UclProxyCdddata336Value:0, UclProxyCdddata337Value:0, UclProxyCdddata338Value:0, UclProxyCdddata339Value:0, UclProxyCdddata340Value:0, UclProxyCdddata341Value:0, UclProxyCdddata342Value:0, UclProxyCdddata343Value:0, UclProxyCdddata344Value:0, UclProxyCdddata345Value:0, UclProxyCdddata346Value:0, UclProxyCdddata347Value:0, UclProxyCdddata348Value:0, UclProxyCdddata349Value:0, UclProxyCdddata350Value:0, UclProxyCdddata351Value:0, UclProxyCdddata352Value:0, UclProxyCdddata353Value:0, UclProxyCdddata354Value:0, UclProxyCdddata355Value:0, UclProxyCdddata356Value:0, UclProxyCdddata357Value:0, UclProxyCdddata358Value:0, UclProxyCdddata359Value:0, UclProxyCdddata360Value:0, UclProxyCdddata361Value:0, UclProxyCdddata362Value:0, UclProxyCdddata363Value:0, UclProxyCdddata364Value:0, UclProxyCdddata365Value:0, UclProxyCdddata366Value:0, UclProxyCdddata367Value:0, UclProxyCdddata368Value:0, UclProxyCdddata369Value:0, UclProxyCdddata370Value:0, UclProxyCdddata371Value:0, UclProxyCdddata372Value:0, UclProxyCdddata373Value:0, UclProxyCdddata374Value:0, UclProxyCdddata375Value:0, UclProxyCdddata376Value:0, UclProxyCdddata377Value:0, UclProxyCdddata378Value:0, UclProxyCdddata379Value:0, UclProxyCdddata380Value:0, UclProxyCdddata381Value:0, UclProxyCdddata382Value:0, UclProxyCdddata383Value:0, UclProxyCdddata384Value:0, UclProxyCdddata385Value:0, UclProxyCdddata386Value:0, UclProxyCdddata387Value:0, UclProxyCdddata388Value:0, UclProxyCdddata389Value:0, UclProxyCdddata390Value:0, UclProxyCdddata391Value:0, UclProxyCdddata392Value:0, UclProxyCdddata393Value:0, UclProxyCdddata394Value:0, UclProxyCdddata395Value:0, UclProxyCdddata396Value:0, UclProxyCdddata397Value:0, UclProxyCdddata398Value:0, UclProxyCdddata399Value:0, UclProxyCdddata400Value:0, UclProxyCdddata401Value:0, UclProxyCdddata402Value:0, UclProxyCdddata403Value:0, UclProxyCdddata404Value:0, UclProxyCdddata405Value:0, UclProxyCdddata406Value:0, UclProxyCdddata407Value:0, UclProxyCdddata408Value:0, UclProxyCdddata409Value:0, UclProxyCdddata410Value:0, UclProxyCdddata411Value:0, UclProxyCdddata412Value:0, UclProxyCdddata413Value:0, UclProxyCdddata414Value:0, UclProxyCdddata415Value:0, UclProxyCdddata416Value:0, UclProxyCdddata417Value:0, UclProxyCdddata418Value:0, UclProxyCdddata419Value:0, UclProxyCdddata420Value:0, UclProxyCdddata421Value:0, UclProxyCdddata422Value:0, UclProxyCdddata423Value:0, UclProxyCdddata424Value:0, UclProxyCdddata425Value:0, UclProxyCdddata426Value:0, UclProxyCdddata427Value:0, UclProxyCdddata428Value:0, UclProxyCdddata429Value:0, UclProxyCdddata430Value:0, UclProxyCdddata431Value:0, UclProxyCdddata432Value:0, UclProxyCdddata433Value:0, UclProxyCdddata434Value:0, UclProxyCdddata435Value:0, UclProxyCdddata436Value:0, UclProxyCdddata437Value:0, UclProxyCdddata438Value:0, UclProxyCdddata439Value:0, UclProxyCdddata440Value:0, UclProxyCdddata441Value:0, UclProxyCdddata442Value:0, UclProxyCdddata443Value:0, UclProxyCdddata444Value:0, UclProxyCdddata445Value:0, UclProxyCdddata446Value:0, UclProxyCdddata447Value:0, UclProxyCdddata448Value:0, UclProxyCdddata449Value:0, UclProxyCdddata450Value:0, UclProxyCdddata451Value:0, UclProxyCdddata452Value:0, UclProxyCdddata453Value:0, UclProxyCdddata454Value:0, UclProxyCdddata455Value:0, UclProxyCdddata456Value:0, UclProxyCdddata457Value:0, UclProxyCdddata458Value:0, UclProxyCdddata459Value:0, UclProxyCdddata460Value:0, UclProxyCdddata461Value:0, UclProxyCdddata462Value:0, UclProxyCdddata463Value:0, UclProxyCdddata464Value:0, UclProxyCdddata465Value:0, UclProxyCdddata466Value:0, UclProxyCdddata467Value:0, UclProxyCdddata468Value:0, UclProxyCdddata469Value:0, UclProxyCdddata470Value:0, UclProxyCdddata471Value:0, UclProxyCdddata472Value:0, UclProxyCdddata473Value:0, UclProxyCdddata474Value:0, UclProxyCdddata475Value:0, UclProxyCdddata476Value:0, UclProxyCdddata477Value:0, UclProxyCdddata478Value:0, UclProxyCdddata479Value:0, UclProxyCdddata480Value:0, UclProxyCdddata481Value:0, UclProxyCdddata482Value:0, UclProxyCdddata483Value:0, UclProxyCdddata484Value:0, UclProxyCdddata485Value:0, UclProxyCdddata486Value:0, UclProxyCdddata487Value:0, UclProxyCdddata488Value:0, UclProxyCdddata489Value:0, UclProxyCdddata490Value:0, UclProxyCdddata491Value:0, UclProxyCdddata492Value:0, UclProxyCdddata493Value:0, UclProxyCdddata494Value:0, UclProxyCdddata495Value:0, UclProxyCdddata496Value:0, UclProxyCdddata497Value:0, UclProxyCdddata498Value:0, UclProxyCdddata499Value:0, UclProxyCdddata500Value:0, UclProxyCdddata501Value:0, UclProxyCdddata502Value:0, UclProxyCdddata503Value:0, UclProxyCdddata504Value:0, UclProxyCdddata505Value:0, UclProxyCdddata506Value:0, UclProxyCdddata507Value:0, UclProxyCdddata508Value:0, UclProxyCdddata509Value:0, UclProxyCdddata510Value:0, UclProxyCdddata511Value:0]]}
    UclProxyCddUpdateShortServiceReqDataValue0: value-spec={short-label=UclProxyCddUpdateShortServiceReqDataValue0, fields=[UclProxyCddUpdateShortServiceReqDataValue_0:0, UclProxyCddUpdateShortServiceReqDataValue_1:0, UclProxyCddUpdateShortServiceReqDataValue_2:0, UclProxyCddUpdateShortServiceReqDataValue_3:0, UclProxyCddUpdateShortServiceReqDataValue_4:0, UclProxyCddUpdateShortServiceReqDataValue_5:0, UclProxyCddUpdateShortServiceReqDataValue_6:[UclProxyCdddata0Value:0, UclProxyCdddata1Value:0, UclProxyCdddata2Value:0, UclProxyCdddata3Value:0, UclProxyCdddata4Value:0, UclProxyCdddata5Value:0, UclProxyCdddata6Value:0, UclProxyCdddata7Value:0, UclProxyCdddata8Value:0, UclProxyCdddata9Value:0, UclProxyCdddata10Value:0, UclProxyCdddata11Value:0, UclProxyCdddata12Value:0, UclProxyCdddata13Value:0, UclProxyCdddata14Value:0, UclProxyCdddata15Value:0, UclProxyCdddata16Value:0, UclProxyCdddata17Value:0, UclProxyCdddata18Value:0, UclProxyCdddata19Value:0, UclProxyCdddata20Value:0, UclProxyCdddata21Value:0, UclProxyCdddata22Value:0, UclProxyCdddata23Value:0, UclProxyCdddata24Value:0, UclProxyCdddata25Value:0, UclProxyCdddata26Value:0, UclProxyCdddata27Value:0, UclProxyCdddata28Value:0, UclProxyCdddata29Value:0, UclProxyCdddata30Value:0, UclProxyCdddata31Value:0, UclProxyCdddata32Value:0, UclProxyCdddata33Value:0, UclProxyCdddata34Value:0, UclProxyCdddata35Value:0, UclProxyCdddata36Value:0, UclProxyCdddata37Value:0, UclProxyCdddata38Value:0, UclProxyCdddata39Value:0, UclProxyCdddata40Value:0, UclProxyCdddata41Value:0, UclProxyCdddata42Value:0, UclProxyCdddata43Value:0, UclProxyCdddata44Value:0, UclProxyCdddata45Value:0, UclProxyCdddata46Value:0, UclProxyCdddata47Value:0, UclProxyCdddata48Value:0, UclProxyCdddata49Value:0, UclProxyCdddata50Value:0, UclProxyCdddata51Value:0, UclProxyCdddata52Value:0, UclProxyCdddata53Value:0, UclProxyCdddata54Value:0, UclProxyCdddata55Value:0, UclProxyCdddata56Value:0, UclProxyCdddata57Value:0, UclProxyCdddata58Value:0, UclProxyCdddata59Value:0, UclProxyCdddata60Value:0, UclProxyCdddata61Value:0, UclProxyCdddata62Value:0, UclProxyCdddata63Value:0]]}
    UclProxyCddWarningDisplayDataValue0: value-spec={short-label=UclProxyCddWarningDisplayDataValue0, fields=[UclProxyCddWarningDisplayDataValue_0:0, UclProxyCddWarningDisplayDataValue_1:0, UclProxyCddWarningDisplayDataValue_2:[UclProxyCdddynData0Value:0, UclProxyCdddynData1Value:0, UclProxyCdddynData2Value:0, UclProxyCdddynData3Value:0, UclProxyCdddynData4Value:0, UclProxyCdddynData5Value:0, UclProxyCdddynData6Value:0, UclProxyCdddynData7Value:0]]}
    UclProxyCddWarningExtDisplayDataValue0: value-spec={short-label=UclProxyCddWarningExtDisplayDataValue0, fields=[UclProxyCddWarningExtDisplayDataValue_0:0, UclProxyCddWarningExtDisplayDataValue_1:0, UclProxyCddWarningExtDisplayDataValue_2:[UclProxyCdddynData0Value:0, UclProxyCdddynData1Value:0, UclProxyCdddynData2Value:0, UclProxyCdddynData3Value:0, UclProxyCdddynData4Value:0, UclProxyCdddynData5Value:0, UclProxyCdddynData6Value:0, UclProxyCdddynData7Value:0]]}
  swc implementation IMPL_UclProxyCdd: programming-language=C, behavior=IB_UclProxyCdd
    code-descriptors:
      code CodeDescriptor
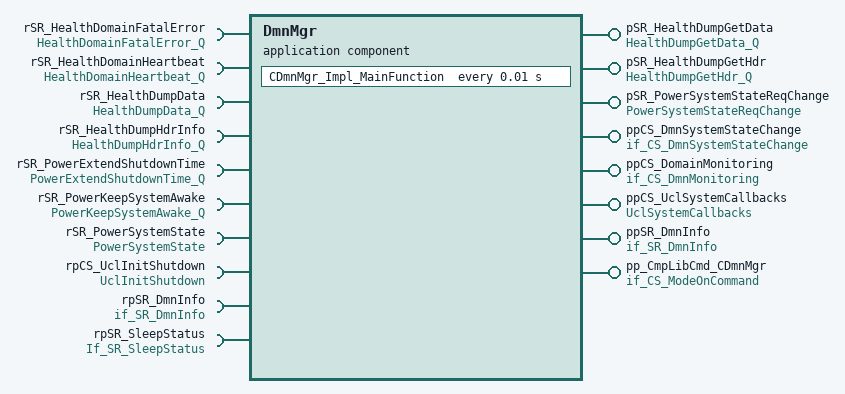
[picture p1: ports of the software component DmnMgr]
  application sw component type DmnMgr
    8 x provide port:
      pSR_HealthDumpGetData: queued-sender-com-spec=HealthDumpGetDataData, provided-interface=HealthDumpGetData_Q
      pSR_HealthDumpGetHdr: queued-sender-com-spec=HealthDumpGetHdrData, provided-interface=HealthDumpGetHdr_Q
      pSR_PowerSystemStateReqChange: nonqueued-sender-com-spec{data-element=PowerSystemStateReqChangeData, init-value=constant-reference=DmnMgrPowerSystemStateReqChangeDataValue0}, provided-interface=PowerSystemStateReqChange
      ppCS_DmnSystemStateChange: provided-interface=if_CS_DmnSystemStateChange
        provided-com-specs:
          operation=DmnSystemStateChangeReq, queue-length=1
          operation=DmnSystemStateChangeStatus, queue-length=1
      ppCS_DomainMonitoring: provided-com-specs=[{operation=StartDomainMonitoring, queue-length=1}, {operation=StopDomainMonitoring, queue-length=1}], provided-interface=if_CS_DmnMonitoring
      ppCS_UclSystemCallbacks: provided-com-specs=[{operation=ErrorNotification, queue-length=1}, {operation=LinkStatusChanged, queue-length=1}], provided-interface=UclSystemCallbacks
      ppSR_DmnInfo: nonqueued-sender-com-spec{data-element=SDmnStatus, init-value=constant-reference=DmnMgrSDmnStatusValue0}, provided-interface=if_SR_DmnInfo
      pp_CmpLibCmd_CDmnMgr: server-com-spec{operation=Impl_OnCommand, queue-length=1}, provided-interface=if_CS_ModeOnCommand
    10 x require port:
      rSR_HealthDomainFatalError: queued-receiver-com-spec{data-element=HealthDomainFatalErrorData, queue-length=2}, required-interface=HealthDomainFatalError_Q
      rSR_HealthDomainHeartbeat: queued-receiver-com-spec{data-element=HealthDomainHeartbeatData, queue-length=5}, required-interface=HealthDomainHeartbeat_Q
      rSR_HealthDumpData: queued-receiver-com-spec{data-element=HealthDumpDataData, queue-length=1}, required-interface=HealthDumpData_Q
      rSR_HealthDumpHdrInfo: queued-receiver-com-spec{data-element=HealthDumpHdrInfoData, queue-length=1}, required-interface=HealthDumpHdrInfo_Q
      rSR_PowerExtendShutdownTime: queued-receiver-com-spec{data-element=PowerExtendShutdownTimeData, queue-length=5}, required-interface=PowerExtendShutdownTime_Q
      rSR_PowerKeepSystemAwake: queued-receiver-com-spec{data-element=PowerKeepSystemAwakeData, queue-length=5}, required-interface=PowerKeepSystemAwake_Q
      rSR_PowerSystemState: nonqueued-receiver-com-spec{data-element=PowerSystemStateData, init-value=constant-reference=DmnMgrPowerSystemStateDataValue0}, required-interface=PowerSystemState
      rpCS_UclInitShutdown: required-interface=UclInitShutdown
      rpSR_DmnInfo: nonqueued-receiver-com-spec{data-element=SDmnStatus, init-value=constant-reference=DmnMgrSDmnStatusValue0}, required-interface=if_SR_DmnInfo
      rpSR_SleepStatus: nonqueued-receiver-com-spec{data-element=SleepManager_SleepStatus, init-value=constant-reference=DmnMgrSleepManager_SleepStatusValue0}, required-interface=If_SR_SleepStatus
    behavior IB_DmnMgr
      timing event TECDmnMgr_Impl_MainFunction: start-on-event=CDmnMgr_Impl_MainFunction, period=0.01
      5 x operation invoked event:
        OIE_pp_CmpLibCmd_CDmnMgr_CDmnMgr_Impl_OnCommandTrigByImpl_OnCommand: start-on-event=CDmnMgr_Impl_OnCommand, operation=pp_CmpLibCmd_CDmnMgr.Impl_OnCommand
        OIE_ppCS_DmnSystemStateChange_DmnMgr_DmnSystemStateChangeReqTrigByDmnSystemStateChangeReq: start-on-event=DmnMgr_DmnSystemStateChangeReq, operation=ppCS_DmnSystemStateChange.DmnSystemStateChangeReq
        OIE_ppCS_DmnSystemStateChange_DmnMgr_DmnSystemStateChangeStatusTrigByDmnSystemStateChangeStatus: start-on-event=DmnMgr_DmnSystemStateChangeStatus, operation=ppCS_DmnSystemStateChange.DmnSystemStateChangeStatus
        OIE_ppCS_UclSystemCallbacks_DmnMgr_ErrorNotificationTrigByErrorNotification: start-on-event=DmnMgr_ErrorNotification, operation=ppCS_UclSystemCallbacks.ErrorNotification
        OIE_ppCS_UclSystemCallbacks_DmnMgr_LinkStatusChangedTrigByLinkStatusChanged: start-on-event=DmnMgr_LinkStatusChanged, operation=ppCS_UclSystemCallbacks.LinkStatusChanged
      7 x data received event:
        DREDmnMgr_MonitorDmnExtendShutdownTimeTrigByPowerExtendShutdownTimeData: start-on-event=DmnMgr_MonitorDmnExtendShutdownTime, data=rSR_PowerExtendShutdownTime.PowerExtendShutdownTimeData
        DREDmnMgr_MonitorDmnHealthDumpDataTrigByHealthDumpDataData: start-on-event=DmnMgr_MonitorDmnHealthDumpData, data=rSR_HealthDumpData.HealthDumpDataData
        DREDmnMgr_MonitorDmnHealthDumpHdrInfoTrigByHealthDumpHdrInfoData: start-on-event=DmnMgr_MonitorDmnHealthDumpHdrInfo, data=rSR_HealthDumpHdrInfo.HealthDumpHdrInfoData
        DREDmnMgr_MonitorDmnHealthFatalErrorTrigByHealthDomainFatalErrorData: start-on-event=DmnMgr_MonitorDmnHealthFatalError, data=rSR_HealthDomainFatalError.HealthDomainFatalErrorData
        DREDmnMgr_MonitorDmnHeartBeatTrigByHealthDomainHeartbeatData: start-on-event=DmnMgr_MonitorDmnHeartBeat, data=rSR_HealthDomainHeartbeat.HealthDomainHeartbeatData
        DREDmnMgr_MonitorDmnKeepSystemAwakeTrigByPowerKeepSystemAwakeData: start-on-event=DmnMgr_MonitorDmnKeepSystemAwake, data=rSR_PowerKeepSystemAwake.PowerKeepSystemAwakeData
        DREDmnMgr_MonitorDmnPowerSystemStateTrigByPowerSystemStateData: start-on-event=DmnMgr_MonitorDmnPowerSystemState, data=rSR_PowerSystemState.PowerSystemStateData
      operation invoked event OIE_ppCS_DomainMonitoring_DmnMgr_StartDomainMonitoringTrigByStartDomainMonitoring: start-on-event=DmnMgr_StartDomainMonitoring, operation=ppCS_DomainMonitoring.StartDomainMonitoring
      operation invoked event OIE_ppCS_DomainMonitoring_DmnMgr_StopDomainMonitoringTrigByStopDomainMonitoring: start-on-event=DmnMgr_StopDomainMonitoring, operation=ppCS_DomainMonitoring.StopDomainMonitoring
      port-api-options:
        enable-take-address=false, indirect-api=false, port=pSR_HealthDumpGetData
        enable-take-address=false, indirect-api=false, port=pSR_HealthDumpGetHdr
        enable-take-address=false, indirect-api=false, port=pSR_PowerSystemStateReqChange
        enable-take-address=false, indirect-api=false, port=ppCS_DmnSystemStateChange
        enable-take-address=false, indirect-api=false, port=ppCS_DomainMonitoring
        enable-take-address=false, indirect-api=false, port=ppCS_UclSystemCallbacks
        enable-take-address=false, indirect-api=false, port=ppSR_DmnInfo
        enable-take-address=false, indirect-api=false, port=pp_CmpLibCmd_CDmnMgr
        enable-take-address=false, indirect-api=false, port=rSR_HealthDomainFatalError
        enable-take-address=false, indirect-api=false, port=rSR_HealthDomainHeartbeat
        enable-take-address=false, indirect-api=false, port=rSR_HealthDumpData
        enable-take-address=false, indirect-api=false, port=rSR_HealthDumpHdrInfo
        enable-take-address=false, indirect-api=false, port=rSR_PowerExtendShutdownTime
        enable-take-address=false, indirect-api=false, port=rSR_PowerKeepSystemAwake
        enable-take-address=false, indirect-api=false, port=rSR_PowerSystemState
        enable-take-address=false, indirect-api=false, port=rpCS_UclInitShutdown
        enable-take-address=false, indirect-api=false, port=rpSR_DmnInfo
        enable-take-address=false, indirect-api=false, port=DmnMgr/rpSR_SleepStatus
      15 x runnable, all with can-be-invoked-concurrently=true:
        CDmnMgr_Impl_MainFunction
          data-receive-point-by-arguments:
            9 x access:
              DRP_rSR_HealthDomainFatalError_HealthDomainFatalErrorData: accessed-variable=rSR_HealthDomainFatalError.HealthDomainFatalErrorData
              DRP_rSR_HealthDomainHeartbeat_HealthDomainHeartbeatData: accessed-variable=rSR_HealthDomainHeartbeat.HealthDomainHeartbeatData
              DRP_rSR_HealthDumpData_HealthDumpDataData: accessed-variable=rSR_HealthDumpData.HealthDumpDataData
              DRP_rSR_HealthDumpHdrInfo_HealthDumpHdrInfoData: accessed-variable=rSR_HealthDumpHdrInfo.HealthDumpHdrInfoData
              DRP_rSR_PowerExtendShutdownTime_PowerExtendShutdownTimeData: accessed-variable=rSR_PowerExtendShutdownTime.PowerExtendShutdownTimeData
              DRP_rSR_PowerKeepSystemAwake_PowerKeepSystemAwakeData: accessed-variable=rSR_PowerKeepSystemAwake.PowerKeepSystemAwakeData
              DRA_rSR_PowerSystemState_PowerSystemStateData: accessed-variable=rSR_PowerSystemState.PowerSystemStateData
              DRA_rpSR_DmnInfo_SDmnStatus: accessed-variable=rpSR_DmnInfo.SDmnStatus
              DRA_rpSR_SleepStatus_SleepManager_SleepStatus: accessed-variable=rpSR_SleepStatus.SleepManager_SleepStatus
          data-send-points:
            4 x access:
              DSP_pSR_HealthDumpGetData_HealthDumpGetDataData: accessed-variable=pSR_HealthDumpGetData.HealthDumpGetDataData
              DSP_pSR_HealthDumpGetHdr_HealthDumpGetHdrData: accessed-variable=pSR_HealthDumpGetHdr.HealthDumpGetHdrData
              DWA_pSR_PowerSystemStateReqChange_PowerSystemStateReqChangeData: accessed-variable=pSR_PowerSystemStateReqChange.PowerSystemStateReqChangeData
              DWA_ppSR_DmnInfo_SDmnStatus: accessed-variable=ppSR_DmnInfo.SDmnStatus
          sync call OA_rpCS_UclInitShutdown_Impl_Shutdown: operation=rpCS_UclInitShutdown.Impl_Shutdown, timeout=0.0
          sync call OA_rpCS_UclInitShutdown_Impl_Initialize: operation=rpCS_UclInitShutdown.Impl_Initialize, timeout=0.0
        CDmnMgr_Impl_OnCommand
        DmnMgr_DmnSystemStateChangeReq
        DmnMgr_DmnSystemStateChangeStatus
        DmnMgr_ErrorNotification
        DmnMgr_LinkStatusChanged
        DmnMgr_MonitorDmnExtendShutdownTime
        DmnMgr_MonitorDmnHealthDumpData
        DmnMgr_MonitorDmnHealthDumpHdrInfo
        DmnMgr_MonitorDmnHealthFatalError
        DmnMgr_MonitorDmnHeartBeat
        DmnMgr_MonitorDmnKeepSystemAwake
        DmnMgr_MonitorDmnPowerSystemState
        DmnMgr_StartDomainMonitoring
        DmnMgr_StopDomainMonitoring
  4 x constant specification:
    DmnMgrPowerSystemStateReqChangeDataValue0: value-spec={short-label=DmnMgrPowerSystemStateReqChangeDataValue0, fields=[DmnMgrPowerSystemStateReqChangeDataValue_0:0, DmnMgrPowerSystemStateReqChangeDataValue_1:0]}
    DmnMgrSDmnStatusValue0: value-spec={short-label=DmnMgrSDmnStatusValue0, fields=[DmnMgrSDmnStatusValue_0:0, DmnMgrSDmnStatusValue_1:0, DmnMgrSDmnStatusValue_2:0, DmnMgrSDmnStatusValue_3:0, DmnMgrSDmnStatusValue_4:0, DmnMgrSDmnStatusValue_5:0]}
    DmnMgrPowerSystemStateDataValue0: value-spec={short-label=DmnMgrPowerSystemStateDataValue0, fields=[DmnMgrPowerSystemStateDataValue_0:0, DmnMgrPowerSystemStateDataValue_1:0]}
    DmnMgrSleepManager_SleepStatusValue0: value-spec=DmnMgrSleepManager_SleepStatusValue0:0
  swc implementation IMPL_DmnMgr: programming-language=C, behavior=IB_DmnMgr
    code-descriptors:
      code CodeDescriptor
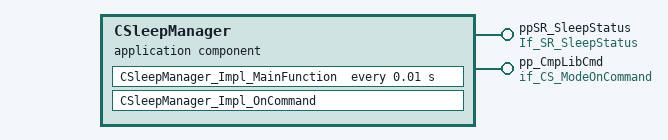
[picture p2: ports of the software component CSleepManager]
  application sw component type CSleepManager
    provide port ppSR_SleepStatus: nonqueued-sender-com-spec{data-element=SleepManager_SleepStatus, init-value=constant-reference=CSleepManagerSleepManager_SleepStatusValue0}, provided-interface=If_SR_SleepStatus
    provide port pp_CmpLibCmd: server-com-spec{operation=Impl_OnCommand, queue-length=1}, provided-interface=if_CS_ModeOnCommand
    behavior IB_CSleepManager
      timing event TECSleepManager_Impl_MainFunction: start-on-event=CSleepManager_Impl_MainFunction, period=0.01
      operation invoked event OIE_pp_CmpLibCmd_CSleepManager_Impl_OnCommandTrigByImpl_OnCommand: start-on-event=CSleepManager_Impl_OnCommand, operation=pp_CmpLibCmd.Impl_OnCommand
      port-api-options:
        enable-take-address=false, indirect-api=false, port=ppSR_SleepStatus
        enable-take-address=false, indirect-api=false, port=CSleepManager/pp_CmpLibCmd
      runnable CSleepManager_Impl_MainFunction: can-be-invoked-concurrently=true
        data-send-points:
          access DWA_ppSR_SleepStatus_SleepManager_SleepStatus: accessed-variable=ppSR_SleepStatus.SleepManager_SleepStatus
      runnable CSleepManager_Impl_OnCommand: can-be-invoked-concurrently=true
  constant specification CSleepManagerSleepManager_SleepStatusValue0: value-spec=CSleepManagerSleepManager_SleepStatusValue0:0
  swc implementation IMPL_CSleepManager: programming-language=C, behavior=IB_CSleepManager
    code-descriptors:
      code CodeDescriptor
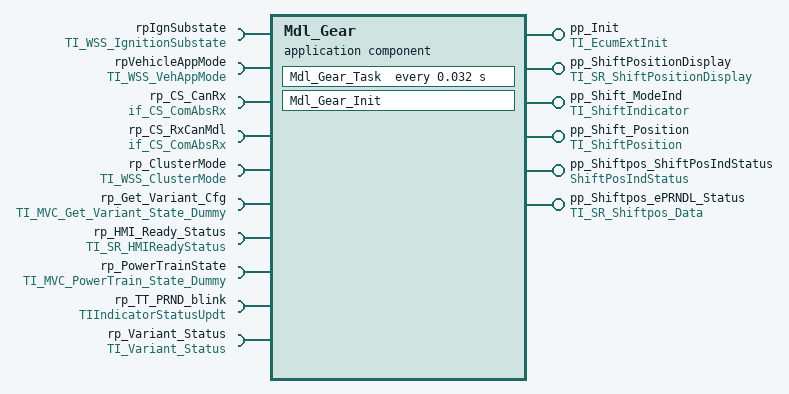
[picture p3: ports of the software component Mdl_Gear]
  application sw component type Mdl_Gear
    6 x provide port:
      pp_Init: server-com-spec{operation=TI_EcumExtInit/Init, queue-length=1}, provided-interface=TI_EcumExtInit
      pp_ShiftPositionDisplay: nonqueued-sender-com-spec{data-element=ShiftPositionDisplay, init-value=constant-reference=Mdl_GearShiftPositionDisplayValue0}, provided-interface=TI_SR_ShiftPositionDisplay
      pp_Shift_ModeInd: nonqueued-sender-com-spec{data-element=ShiftModeIndicator, init-value=constant-reference=Mdl_GearShiftModeIndicatorValue0}, provided-interface=TI_ShiftIndicator
      pp_Shift_Position: nonqueued-sender-com-spec{data-element=ShiftPosition, init-value=constant-reference=Mdl_GearShiftPositionValue0}, provided-interface=TI_ShiftPosition
      pp_Shiftpos_ShiftPosIndStatus: nonqueued-sender-com-spec{data-element=ShiftPosIndStatusData, init-value=constant-reference=Mdl_GearShiftPosIndStatusDataValue0}, provided-interface=ShiftPosIndStatus
      pp_Shiftpos_ePRNDL_Status: nonqueued-sender-com-spec{data-element=ShiftPos_Data, init-value=constant-reference=Mdl_GearShiftPos_DataValue0}, provided-interface=TI_SR_Shiftpos_Data
    10 x require port:
      rpIgnSubstate: nonqueued-receiver-com-spec{data-element=IgnitionSubstate, init-value=constant-reference=Mdl_GearIgnitionSubstateValue0}, required-interface=TI_WSS_IgnitionSubstate
      rpVehicleAppMode: nonqueued-receiver-com-spec{data-element=WSSCurrentVehicleState, init-value=constant-reference=Mdl_GearWSSCurrentVehicleStateValue0}, required-interface=TI_WSS_VehAppMode
      rp_CS_CanRx: required-interface=if_CS_ComAbsRx
      rp_CS_RxCanMdl: required-interface=if_CS_ComAbsRx
      rp_ClusterMode: nonqueued-receiver-com-spec{data-element=WSSCurrentClusterMode, init-value=constant-reference=Mdl_GearWSSCurrentClusterModeValue0}, required-interface=TI_WSS_ClusterMode
      rp_Get_Variant_Cfg: required-interface=TI_MVC_Get_Variant_State_Dummy
      rp_HMI_Ready_Status: nonqueued-receiver-com-spec{data-element=HMI_ReadyStatus, init-value=constant-reference=Mdl_GearHMI_ReadyStatusValue0}, required-interface=TI_SR_HMIReadyStatus
      rp_PowerTrainState: nonqueued-receiver-com-spec{data-element=PowerTrain_Flag, init-value=constant-reference=Mdl_GearPowerTrain_FlagValue0}, required-interface=TI_MVC_PowerTrain_State_Dummy
      rp_TT_PRND_blink: nonqueued-receiver-com-spec{data-element=TIUpdateIndicatorStatus, init-value=constant-reference=Mdl_GearTIUpdateIndicatorStatusValue0}, required-interface=TIIndicatorStatusUpdt
      rp_Variant_Status: required-interface=TI_Variant_Status
    behavior IB_Mdl_Gear
      operation invoked event OIE_pp_Init_Mdl_Gear_InitTrigByInit: start-on-event=Mdl_Gear_Init, operation=pp_Init.Init
      timing event TEMdl_Gear_Task: start-on-event=Mdl_Gear_Task, period=0.032
      port-api-options:
        enable-take-address=false, indirect-api=false, port=Mdl_Gear/pp_Init
        enable-take-address=false, indirect-api=false, port=pp_ShiftPositionDisplay
        enable-take-address=false, indirect-api=false, port=pp_Shift_ModeInd
        enable-take-address=false, indirect-api=false, port=pp_Shift_Position
        enable-take-address=false, indirect-api=false, port=pp_Shiftpos_ShiftPosIndStatus
        enable-take-address=false, indirect-api=false, port=pp_Shiftpos_ePRNDL_Status
        enable-take-address=false, indirect-api=false, port=Mdl_Gear/rpIgnSubstate
        enable-take-address=false, indirect-api=false, port=Mdl_Gear/rpVehicleAppMode
        enable-take-address=false, indirect-api=false, port=Mdl_Gear/rp_CS_CanRx
        enable-take-address=false, indirect-api=false, port=Mdl_Gear/rp_CS_RxCanMdl
        enable-take-address=false, indirect-api=false, port=Mdl_Gear/rp_ClusterMode
        enable-take-address=false, indirect-api=false, port=Mdl_Gear/rp_Get_Variant_Cfg
        enable-take-address=false, indirect-api=false, port=rp_HMI_Ready_Status
        enable-take-address=false, indirect-api=false, port=rp_PowerTrainState
        enable-take-address=false, indirect-api=false, port=rp_TT_PRND_blink
        enable-take-address=false, indirect-api=false, port=Mdl_Gear/rp_Variant_Status
      runnable Mdl_Gear_Init: can-be-invoked-concurrently=true
      runnable Mdl_Gear_Task: can-be-invoked-concurrently=true
        data-receive-point-by-arguments:
          6 x access:
            DRA_rpIgnSubstate_IgnitionSubstate: accessed-variable=rpIgnSubstate.IgnitionSubstate
            DRA_rpVehicleAppMode_WSSCurrentVehicleState: accessed-variable=rpVehicleAppMode.WSSCurrentVehicleState
            DRA_rp_ClusterMode_WSSCurrentClusterMode: accessed-variable=rp_ClusterMode.WSSCurrentClusterMode
            DRA_rp_HMI_Ready_Status_HMI_ReadyStatus: accessed-variable=rp_HMI_Ready_Status.HMI_ReadyStatus
            DRA_rp_PowerTrainState_PowerTrain_Flag: accessed-variable=rp_PowerTrainState.PowerTrain_Flag
            DRA_rp_TT_PRND_blink_TIUpdateIndicatorStatus: accessed-variable=rp_TT_PRND_blink.TIUpdateIndicatorStatus
        data-send-points:
          5 x access:
            DWA_pp_ShiftPositionDisplay_ShiftPositionDisplay: accessed-variable=pp_ShiftPositionDisplay.ShiftPositionDisplay
            DWA_pp_Shift_ModeInd_ShiftModeIndicator: accessed-variable=pp_Shift_ModeInd.ShiftModeIndicator
            DWA_pp_Shift_Position_ShiftPosition: accessed-variable=pp_Shift_Position.ShiftPosition
            DWA_pp_Shiftpos_ShiftPosIndStatus_ShiftPosIndStatusData: accessed-variable=pp_Shiftpos_ShiftPosIndStatus.ShiftPosIndStatusData
            DWA_pp_Shiftpos_ePRNDL_Status_ShiftPos_Data: accessed-variable=pp_Shiftpos_ePRNDL_Status.ShiftPos_Data
        20 x sync call, all with timeout=0.0:
          OA_rp_CS_CanRx_RxCan_GetSignalValueU8Arr: operation=rp_CS_CanRx.RxCan_GetSignalValueU8Arr
          OA_rp_CS_CanRx_RxCan_SetSignalInitValue: operation=rp_CS_CanRx.RxCan_SetSignalInitValue
          OA_rp_CS_CanRx_RxCan_SetSignalInitValueU8Arr: operation=rp_CS_CanRx.RxCan_SetSignalInitValueU8Arr
          OA_rp_CS_CanRx_RxCan_SignalInvalidProcessingControl: operation=rp_CS_CanRx.RxCan_SignalInvalidProcessingControl
          OA_rp_CS_CanRx_RxCan_SignalMissingProcessingControl: operation=rp_CS_CanRx.RxCan_SignalMissingProcessingControl
          OA_rp_CS_CanRx_RxCan_SignalNRProcessingControl: operation=rp_CS_CanRx.RxCan_SignalNRProcessingControl
          OA_rp_CS_CanRx_RxCan_SignalGetJustRcvdStatus: operation=rp_CS_CanRx.RxCan_SignalGetJustRcvdStatus
          OA_rp_CS_CanRx_RxCan_SignalClearJustRcvdStatus: operation=rp_CS_CanRx.RxCan_SignalClearJustRcvdStatus
          OA_rp_CS_CanRx_RxCan_GetSignalValue: operation=rp_CS_CanRx.RxCan_GetSignalValue
          OA_rp_CS_RxCanMdl_RxCan_GetSignalValueU8Arr: operation=rp_CS_RxCanMdl.RxCan_GetSignalValueU8Arr
          OA_rp_CS_RxCanMdl_RxCan_SetSignalInitValue: operation=rp_CS_RxCanMdl.RxCan_SetSignalInitValue
          OA_rp_CS_RxCanMdl_RxCan_SetSignalInitValueU8Arr: operation=rp_CS_RxCanMdl.RxCan_SetSignalInitValueU8Arr
          OA_rp_CS_RxCanMdl_RxCan_SignalInvalidProcessingControl: operation=rp_CS_RxCanMdl.RxCan_SignalInvalidProcessingControl
          OA_rp_CS_RxCanMdl_RxCan_SignalMissingProcessingControl: operation=rp_CS_RxCanMdl.RxCan_SignalMissingProcessingControl
          OA_rp_CS_RxCanMdl_RxCan_SignalNRProcessingControl: operation=rp_CS_RxCanMdl.RxCan_SignalNRProcessingControl
          OA_rp_CS_RxCanMdl_RxCan_SignalGetJustRcvdStatus: operation=rp_CS_RxCanMdl.RxCan_SignalGetJustRcvdStatus
          OA_rp_CS_RxCanMdl_RxCan_SignalClearJustRcvdStatus: operation=rp_CS_RxCanMdl.RxCan_SignalClearJustRcvdStatus
          OA_rp_CS_RxCanMdl_RxCan_GetSignalValue: operation=rp_CS_RxCanMdl.RxCan_GetSignalValue
          OA_rp_Get_Variant_Cfg_Get_Variant_Config_State: operation=rp_Get_Variant_Cfg.Get_Variant_Config_State
          OA_rp_Variant_Status_GetVariant_Status: operation=rp_Variant_Status.GetVariant_Status
  11 x constant specification:
    Mdl_GearShiftPositionDisplayValue0: value-spec=Mdl_GearShiftPositionDisplayValue0:0
    Mdl_GearShiftModeIndicatorValue0: value-spec=Mdl_GearShiftModeIndicatorValue0:0
    Mdl_GearShiftPositionValue0: value-spec=Mdl_GearShiftPositionValue0:0
    Mdl_GearShiftPosIndStatusDataValue0: value-spec={short-label=Mdl_GearShiftPosIndStatusDataValue0, fields={short-label=Mdl_GearShiftPosIndStatusDataValue_0, fields=[Mdl_GearstatusValue_0:0, Mdl_GearstatusValue_1:0, Mdl_GearstatusValue_2:0, Mdl_GearstatusValue_3:0, Mdl_GearstatusValue_4:0, Mdl_GearstatusValue_5:0]}}
    Mdl_GearShiftPos_DataValue0: value-spec={short-label=Mdl_GearShiftPos_DataValue0, fields=[Mdl_GearShiftPos_DataValue_0:0, Mdl_GearShiftPos_DataValue_1:0, Mdl_GearShiftPos_DataValue_2:0, Mdl_GearShiftPos_DataValue_3:0, Mdl_GearShiftPos_DataValue_4:0]}
    Mdl_GearIgnitionSubstateValue0: value-spec=Mdl_GearIgnitionSubstateValue0:0
    Mdl_GearWSSCurrentVehicleStateValue0: value-spec=Mdl_GearWSSCurrentVehicleStateValue0:0
    Mdl_GearWSSCurrentClusterModeValue0: value-spec=Mdl_GearWSSCurrentClusterModeValue0:0
    Mdl_GearHMI_ReadyStatusValue0: value-spec=Mdl_GearHMI_ReadyStatusValue0:0
    Mdl_GearPowerTrain_FlagValue0: value-spec=Mdl_GearPowerTrain_FlagValue0:0
    Mdl_GearTIUpdateIndicatorStatusValue0: value-spec=Mdl_GearTIUpdateIndicatorStatusValue0:0
  swc implementation IMPL_Mdl_Gear: programming-language=C, behavior=IB_Mdl_Gear
    code-descriptors:
      code CodeDescriptor
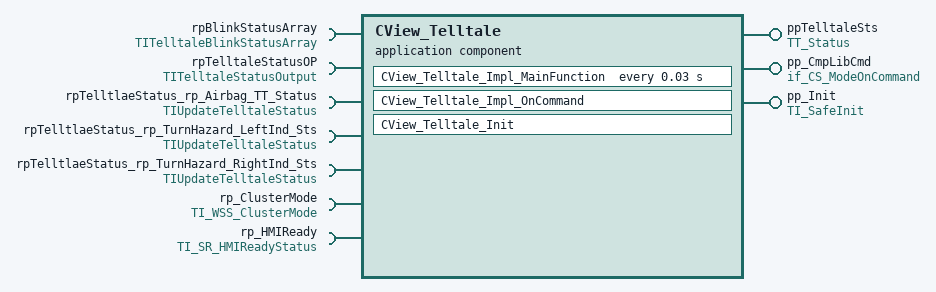
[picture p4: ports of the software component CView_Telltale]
  application sw component type CView_Telltale
    provide port ppTelltaleSts: nonqueued-sender-com-spec{data-element=TT_StatusData, init-value=constant-reference=CView_TelltaleTT_StatusDataValue0}, provided-interface=TT_Status
    provide port pp_CmpLibCmd: server-com-spec{operation=Impl_OnCommand, queue-length=1}, provided-interface=if_CS_ModeOnCommand
    provide port pp_Init: server-com-spec{operation=TI_SafeInit/Init, queue-length=1}, provided-interface=TI_SafeInit
    7 x require port:
      rpBlinkStatusArray: required-interface=TITelltaleBlinkStatusArray
        required-com-specs:
          data-element=TTBlinkStatusArray, init-value=constant-reference=CView_TelltaleTTBlinkStatusArrayValue0
          data-element=TTdummyDataForTypes, init-value=constant-reference=CView_TelltaleTTdummyDataForTypesValue0
      rpTelltaleStatusOP: nonqueued-receiver-com-spec{data-element=TelltaleOpArray, init-value=constant-reference=CView_TelltaleTelltaleOpArrayValue0}, required-interface=TITelltaleStatusOutput
      rpTelltlaeStatus_rp_Airbag_TT_Status: nonqueued-receiver-com-spec{data-element=CurrentTelltaleStatus, init-value=constant-reference=CView_TelltaleCurrentTelltaleStatusValue0}, required-interface=TIUpdateTelltaleStatus
      rpTelltlaeStatus_rp_TurnHazard_LeftInd_Sts: nonqueued-receiver-com-spec{data-element=CurrentTelltaleStatus, init-value=constant-reference=CView_TelltaleCurrentTelltaleStatusValue0}, required-interface=TIUpdateTelltaleStatus
      rpTelltlaeStatus_rp_TurnHazard_RightInd_Sts: nonqueued-receiver-com-spec{data-element=CurrentTelltaleStatus, init-value=constant-reference=CView_TelltaleCurrentTelltaleStatusValue0}, required-interface=TIUpdateTelltaleStatus
      rp_ClusterMode: nonqueued-receiver-com-spec{data-element=WSSCurrentClusterMode, init-value=constant-reference=CView_TelltaleWSSCurrentClusterModeValue0}, required-interface=TI_WSS_ClusterMode
      rp_HMIReady: nonqueued-receiver-com-spec{data-element=HMI_ReadyStatus, init-value=constant-reference=CView_TelltaleHMI_ReadyStatusValue0}, required-interface=TI_SR_HMIReadyStatus
    behavior IB_CView_Telltale
      timing event TECView_Telltale_Impl_MainFunction: start-on-event=CView_Telltale_Impl_MainFunction, period=0.03
      operation invoked event OIE_pp_CmpLibCmd_CView_Telltale_Impl_OnCommandTrigByImpl_OnCommand: start-on-event=CView_Telltale_Impl_OnCommand, operation=pp_CmpLibCmd.Impl_OnCommand
      operation invoked event OIE_pp_Init_CView_Telltale_InitTrigByInit: start-on-event=CView_Telltale_Init, operation=pp_Init.Init
      port-api-options:
        enable-take-address=false, indirect-api=false, port=ppTelltaleSts
        enable-take-address=false, indirect-api=false, port=CView_Telltale/pp_CmpLibCmd
        enable-take-address=false, indirect-api=false, port=CView_Telltale/pp_Init
        enable-take-address=false, indirect-api=false, port=rpBlinkStatusArray
        enable-take-address=false, indirect-api=false, port=CView_Telltale/rpTelltaleStatusOP
        enable-take-address=false, indirect-api=false, port=CView_Telltale/rpTelltlaeStatus_rp_Airbag_TT_Status
        enable-take-address=false, indirect-api=false, port=CView_Telltale/rpTelltlaeStatus_rp_TurnHazard_LeftInd_Sts
        enable-take-address=false, indirect-api=false, port=CView_Telltale/rpTelltlaeStatus_rp_TurnHazard_RightInd_Sts
        enable-take-address=false, indirect-api=false, port=CView_Telltale/rp_ClusterMode
        enable-take-address=false, indirect-api=false, port=rp_HMIReady
      runnable CView_Telltale_Impl_MainFunction: can-be-invoked-concurrently=true
        data-receive-point-by-arguments:
          8 x access:
            DRA_rpBlinkStatusArray_TTBlinkStatusArray: accessed-variable=rpBlinkStatusArray.TTBlinkStatusArray
            DRA_rpBlinkStatusArray_TTdummyDataForTypes: accessed-variable=rpBlinkStatusArray.TTdummyDataForTypes
            DRA_rpTelltaleStatusOP_TelltaleOpArray: accessed-variable=rpTelltaleStatusOP.TelltaleOpArray
            DRA_rpTelltlaeStatus_rp_Airbag_TT_Status_CurrentTelltaleStatus: accessed-variable=rpTelltlaeStatus_rp_Airbag_TT_Status.CurrentTelltaleStatus
            DRA_rpTelltlaeStatus_rp_TurnHazard_LeftInd_Sts_CurrentTelltaleStatus: accessed-variable=rpTelltlaeStatus_rp_TurnHazard_LeftInd_Sts.CurrentTelltaleStatus
            DRA_rpTelltlaeStatus_rp_TurnHazard_RightInd_Sts_CurrentTelltaleStatus: accessed-variable=rpTelltlaeStatus_rp_TurnHazard_RightInd_Sts.CurrentTelltaleStatus
            DRA_rp_ClusterMode_WSSCurrentClusterMode: accessed-variable=rp_ClusterMode.WSSCurrentClusterMode
            DRA_rp_HMIReady_HMI_ReadyStatus: accessed-variable=rp_HMIReady.HMI_ReadyStatus
        data-send-points:
          access DWA_ppTelltaleSts_TT_StatusData: accessed-variable=ppTelltaleSts.TT_StatusData
      runnable CView_Telltale_Impl_OnCommand: can-be-invoked-concurrently=true
      runnable CView_Telltale_Init: can-be-invoked-concurrently=true
  7 x constant specification:
    CView_TelltaleTT_StatusDataValue0: value-spec={short-label=CView_TelltaleTT_StatusDataValue0, fields=CView_TelltaleTT_StatusDataValue_0:[CView_Telltalemask0Value:0, CView_Telltalemask1Value:0, CView_Telltalemask2Value:0, CView_Telltalemask3Value:0, CView_Telltalemask4Value:0, CView_Telltalemask5Value:0, CView_Telltalemask6Value:0, CView_Telltalemask7Value:0, CView_Telltalemask8Value:0, CView_Telltalemask9Value:0, CView_Telltalemask10Value:0, CView_Telltalemask11Value:0, CView_Telltalemask12Value:0, CView_Telltalemask13Value:0, CView_Telltalemask14Value:0]}
    CView_TelltaleTTBlinkStatusArrayValue0: value-spec=CView_TelltaleTTBlinkStatusArrayValue0:[CView_TelltaleTTBlinkStatusArray0Value:0, CView_TelltaleTTBlinkStatusArray1Value:0, CView_TelltaleTTBlinkStatusArray2Value:0, CView_TelltaleTTBlinkStatusArray3Value:0, CView_TelltaleTTBlinkStatusArray4Value:0, CView_TelltaleTTBlinkStatusArray5Value:0, CView_TelltaleTTBlinkStatusArray6Value:0, CView_TelltaleTTBlinkStatusArray7Value:0, CView_TelltaleTTBlinkStatusArray8Value:0, CView_TelltaleTTBlinkStatusArray9Value:0, CView_TelltaleTTBlinkStatusArray10Value:0, CView_TelltaleTTBlinkStatusArray11Value:0, CView_TelltaleTTBlinkStatusArray12Value:0, CView_TelltaleTTBlinkStatusArray13Value:0, CView_TelltaleTTBlinkStatusArray14Value:0, CView_TelltaleTTBlinkStatusArray15Value:0]
    CView_TelltaleTTdummyDataForTypesValue0: value-spec=CView_TelltaleTTdummyDataForTypesValue0:0
    CView_TelltaleTelltaleOpArrayValue0: value-spec=CView_TelltaleTelltaleOpArrayValue0:[CView_TelltaleTelltaleOpArray0Value:0, CView_TelltaleTelltaleOpArray1Value:0, CView_TelltaleTelltaleOpArray2Value:0, CView_TelltaleTelltaleOpArray3Value:0, CView_TelltaleTelltaleOpArray4Value:0, CView_TelltaleTelltaleOpArray5Value:0, CView_TelltaleTelltaleOpArray6Value:0, CView_TelltaleTelltaleOpArray7Value:0, CView_TelltaleTelltaleOpArray8Value:0, CView_TelltaleTelltaleOpArray9Value:0, CView_TelltaleTelltaleOpArray10Value:0, CView_TelltaleTelltaleOpArray11Value:0, CView_TelltaleTelltaleOpArray12Value:0, CView_TelltaleTelltaleOpArray13Value:0, CView_TelltaleTelltaleOpArray14Value:0, CView_TelltaleTelltaleOpArray15Value:0, CView_TelltaleTelltaleOpArray16Value:0, CView_TelltaleTelltaleOpArray17Value:0, CView_TelltaleTelltaleOpArray18Value:0, CView_TelltaleTelltaleOpArray19Value:0, CView_TelltaleTelltaleOpArray20Value:0, CView_TelltaleTelltaleOpArray21Value:0, CView_TelltaleTelltaleOpArray22Value:0, CView_TelltaleTelltaleOpArray23Value:0, CView_TelltaleTelltaleOpArray24Value:0, CView_TelltaleTelltaleOpArray25Value:0, CView_TelltaleTelltaleOpArray26Value:0, CView_TelltaleTelltaleOpArray27Value:0, CView_TelltaleTelltaleOpArray28Value:0, CView_TelltaleTelltaleOpArray29Value:0, CView_TelltaleTelltaleOpArray30Value:0, CView_TelltaleTelltaleOpArray31Value:0, CView_TelltaleTelltaleOpArray32Value:0, CView_TelltaleTelltaleOpArray33Value:0, CView_TelltaleTelltaleOpArray34Value:0, CView_TelltaleTelltaleOpArray35Value:0, CView_TelltaleTelltaleOpArray36Value:0, CView_TelltaleTelltaleOpArray37Value:0, CView_TelltaleTelltaleOpArray38Value:0, CView_TelltaleTelltaleOpArray39Value:0, CView_TelltaleTelltaleOpArray40Value:0, CView_TelltaleTelltaleOpArray41Value:0, CView_TelltaleTelltaleOpArray42Value:0, CView_TelltaleTelltaleOpArray43Value:0, CView_TelltaleTelltaleOpArray44Value:0, CView_TelltaleTelltaleOpArray45Value:0, CView_TelltaleTelltaleOpArray46Value:0, CView_TelltaleTelltaleOpArray47Value:0, CView_TelltaleTelltaleOpArray48Value:0, CView_TelltaleTelltaleOpArray49Value:0, CView_TelltaleTelltaleOpArray50Value:0, CView_TelltaleTelltaleOpArray51Value:0, CView_TelltaleTelltaleOpArray52Value:0, CView_TelltaleTelltaleOpArray53Value:0, CView_TelltaleTelltaleOpArray54Value:0, CView_TelltaleTelltaleOpArray55Value:0, CView_TelltaleTelltaleOpArray56Value:0, CView_TelltaleTelltaleOpArray57Value:0, CView_TelltaleTelltaleOpArray58Value:0, CView_TelltaleTelltaleOpArray59Value:0, CView_TelltaleTelltaleOpArray60Value:0, CView_TelltaleTelltaleOpArray61Value:0, CView_TelltaleTelltaleOpArray62Value:0, CView_TelltaleTelltaleOpArray63Value:0, CView_TelltaleTelltaleOpArray64Value:0, CView_TelltaleTelltaleOpArray65Value:0, CView_TelltaleTelltaleOpArray66Value:0, CView_TelltaleTelltaleOpArray67Value:0, CView_TelltaleTelltaleOpArray68Value:0, CView_TelltaleTelltaleOpArray69Value:0, CView_TelltaleTelltaleOpArray70Value:0, CView_TelltaleTelltaleOpArray71Value:0, CView_TelltaleTelltaleOpArray72Value:0, CView_TelltaleTelltaleOpArray73Value:0, CView_TelltaleTelltaleOpArray74Value:0, CView_TelltaleTelltaleOpArray75Value:0, CView_TelltaleTelltaleOpArray76Value:0, CView_TelltaleTelltaleOpArray77Value:0, CView_TelltaleTelltaleOpArray78Value:0, CView_TelltaleTelltaleOpArray79Value:0, CView_TelltaleTelltaleOpArray80Value:0, CView_TelltaleTelltaleOpArray81Value:0, CView_TelltaleTelltaleOpArray82Value:0, CView_TelltaleTelltaleOpArray83Value:0, CView_TelltaleTelltaleOpArray84Value:0, CView_TelltaleTelltaleOpArray85Value:0, CView_TelltaleTelltaleOpArray86Value:0, CView_TelltaleTelltaleOpArray87Value:0, CView_TelltaleTelltaleOpArray88Value:0, CView_TelltaleTelltaleOpArray89Value:0, CView_TelltaleTelltaleOpArray90Value:0, CView_TelltaleTelltaleOpArray91Value:0]
    CView_TelltaleCurrentTelltaleStatusValue0: value-spec=CView_TelltaleCurrentTelltaleStatusValue0:0
    CView_TelltaleWSSCurrentClusterModeValue0: value-spec=CView_TelltaleWSSCurrentClusterModeValue0:0
    CView_TelltaleHMI_ReadyStatusValue0: value-spec=CView_TelltaleHMI_ReadyStatusValue0:0
  swc implementation IMPL_CView_Telltale: programming-language=C, behavior=IB_CView_Telltale
    code-descriptors:
      code CodeDescriptor
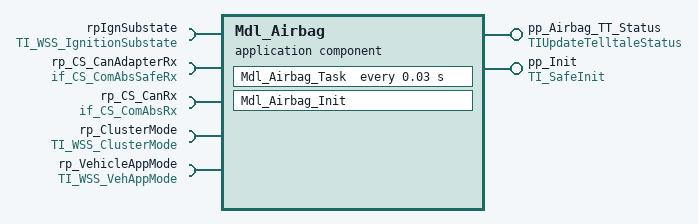
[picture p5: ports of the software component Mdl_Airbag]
  application sw component type Mdl_Airbag
    provide port pp_Airbag_TT_Status: nonqueued-sender-com-spec{data-element=CurrentTelltaleStatus, init-value=constant-reference=Mdl_AirbagCurrentTelltaleStatusValue0}, provided-interface=TIUpdateTelltaleStatus
    provide port pp_Init: server-com-spec{operation=TI_SafeInit/Init, queue-length=1}, provided-interface=TI_SafeInit
    5 x require port:
      rpIgnSubstate: nonqueued-receiver-com-spec{data-element=IgnitionSubstate, init-value=constant-reference=Mdl_AirbagIgnitionSubstateValue0}, required-interface=TI_WSS_IgnitionSubstate
      rp_CS_CanAdapterRx: required-interface=if_CS_ComAbsSafeRx
      rp_CS_CanRx: required-interface=if_CS_ComAbsRx
      rp_ClusterMode: nonqueued-receiver-com-spec{data-element=WSSCurrentClusterMode, init-value=constant-reference=Mdl_AirbagWSSCurrentClusterModeValue0}, required-interface=TI_WSS_ClusterMode
      rp_VehicleAppMode: nonqueued-receiver-com-spec{data-element=WSSCurrentVehicleState, init-value=constant-reference=Mdl_AirbagWSSCurrentVehicleStateValue0}, required-interface=TI_WSS_VehAppMode
    behavior IB_Mdl_Airbag
      operation invoked event OIE_pp_Init_Mdl_Airbag_InitTrigByInit: start-on-event=Mdl_Airbag_Init, operation=pp_Init.Init
      timing event TEMdl_Airbag_Task: start-on-event=Mdl_Airbag_Task, period=0.03
      port-api-options:
        enable-take-address=false, indirect-api=false, port=pp_Airbag_TT_Status
        enable-take-address=false, indirect-api=false, port=Mdl_Airbag/pp_Init
        enable-take-address=false, indirect-api=false, port=Mdl_Airbag/rpIgnSubstate
        enable-take-address=false, indirect-api=false, port=rp_CS_CanAdapterRx
        enable-take-address=false, indirect-api=false, port=Mdl_Airbag/rp_CS_CanRx
        enable-take-address=false, indirect-api=false, port=Mdl_Airbag/rp_ClusterMode
        enable-take-address=false, indirect-api=false, port=rp_VehicleAppMode
      runnable Mdl_Airbag_Init: can-be-invoked-concurrently=true
      runnable Mdl_Airbag_Task: can-be-invoked-concurrently=true
        data-receive-point-by-arguments:
          access DRA_rpIgnSubstate_IgnitionSubstate: accessed-variable=rpIgnSubstate.IgnitionSubstate
          access DRA_rp_ClusterMode_WSSCurrentClusterMode: accessed-variable=rp_ClusterMode.WSSCurrentClusterMode
          access DRA_rp_VehicleAppMode_WSSCurrentVehicleState: accessed-variable=rp_VehicleAppMode.WSSCurrentVehicleState
        data-send-points:
          access DWA_pp_Airbag_TT_Status_CurrentTelltaleStatus: accessed-variable=pp_Airbag_TT_Status.CurrentTelltaleStatus
        16 x sync call, all with timeout=0.0:
          OA_rp_CS_CanAdapterRx_RxCan_SignalInvalidProcessingControl: operation=rp_CS_CanAdapterRx.RxCan_SignalInvalidProcessingControl
          OA_rp_CS_CanAdapterRx_RxCan_SignalMissingProcessingControl: operation=rp_CS_CanAdapterRx.RxCan_SignalMissingProcessingControl
          OA_rp_CS_CanAdapterRx_RxCan_SignalNRProcessingControl: operation=rp_CS_CanAdapterRx.RxCan_SignalNRProcessingControl
          OA_rp_CS_CanAdapterRx_RxCan_SetSignalInitValue: operation=rp_CS_CanAdapterRx.RxCan_SetSignalInitValue
          OA_rp_CS_CanAdapterRx_Mdl_SafetyAdapter_ReloadMissingTimer: operation=rp_CS_CanAdapterRx.Mdl_SafetyAdapter_ReloadMissingTimer
          OA_rp_CS_CanAdapterRx_RxCanVarInit: operation=rp_CS_CanAdapterRx.RxCanVarInit
          OA_rp_CS_CanAdapterRx_RxCan_GetSafeSignalValue: operation=rp_CS_CanAdapterRx.RxCan_GetSafeSignalValue
          OA_rp_CS_CanRx_RxCan_GetSignalValueU8Arr: operation=rp_CS_CanRx.RxCan_GetSignalValueU8Arr
          OA_rp_CS_CanRx_RxCan_SetSignalInitValue: operation=rp_CS_CanRx.RxCan_SetSignalInitValue
          OA_rp_CS_CanRx_RxCan_SetSignalInitValueU8Arr: operation=rp_CS_CanRx.RxCan_SetSignalInitValueU8Arr
          OA_rp_CS_CanRx_RxCan_SignalInvalidProcessingControl: operation=rp_CS_CanRx.RxCan_SignalInvalidProcessingControl
          OA_rp_CS_CanRx_RxCan_SignalMissingProcessingControl: operation=rp_CS_CanRx.RxCan_SignalMissingProcessingControl
          OA_rp_CS_CanRx_RxCan_SignalNRProcessingControl: operation=rp_CS_CanRx.RxCan_SignalNRProcessingControl
          OA_rp_CS_CanRx_RxCan_SignalGetJustRcvdStatus: operation=rp_CS_CanRx.RxCan_SignalGetJustRcvdStatus
          OA_rp_CS_CanRx_RxCan_SignalClearJustRcvdStatus: operation=rp_CS_CanRx.RxCan_SignalClearJustRcvdStatus
          OA_rp_CS_CanRx_RxCan_GetSignalValue: operation=rp_CS_CanRx.RxCan_GetSignalValue
  4 x constant specification:
    Mdl_AirbagCurrentTelltaleStatusValue0: value-spec=Mdl_AirbagCurrentTelltaleStatusValue0:0
    Mdl_AirbagIgnitionSubstateValue0: value-spec=Mdl_AirbagIgnitionSubstateValue0:0
    Mdl_AirbagWSSCurrentClusterModeValue0: value-spec=Mdl_AirbagWSSCurrentClusterModeValue0:0
    Mdl_AirbagWSSCurrentVehicleStateValue0: value-spec=Mdl_AirbagWSSCurrentVehicleStateValue0:0
  swc implementation IMPL_Mdl_Airbag: programming-language=C, behavior=IB_Mdl_Airbag
    code-descriptors:
      code CodeDescriptor
